VERSION ""

NS_ :

BS_:

BU_: FBD_HL IPB_App1 FBD_HM FBD_HR FBD_Miko FBD_MM FBD_Trunk FBD_VL FBD_VM FBD_VR Diagnosetool_CAN_FD_IPB_41

BO_ 686 AnalyticsDataFBD_HL: 48 FBD_HL
 SG_ AnalyticsDataFBD_HL_Ranging_Upti : 0|16@1+ (1.0,0) [0|65532] "s" IPB_App1
 SG_ AnalyticsDataFBD_HL_Ranging_Coun : 16|16@1+ (1.0,0) [0|65532] "" IPB_App1
 SG_ AnalyticsDataFBD_HL_RI_Low_New : 32|16@1+ (1.0,0) [0|65532] "" IPB_App1
 SG_ AnalyticsDataFBD_HL_RI_Low_Cont : 48|16@1+ (1.0,0) [0|65532] "" IPB_App1
 SG_ AnalyticsDataFBD_HL_RI_Med_New : 64|16@1+ (1.0,0) [0|65532] "" IPB_App1
 SG_ AnalyticsDataFBD_HL_RI_Med_Cont : 80|16@1+ (1.0,0) [0|65532] "" IPB_App1
 SG_ AnalyticsDataFBD_HL_RI_High_New : 96|16@1+ (1.0,0) [0|65532] "" IPB_App1
 SG_ AnalyticsDataFBD_HL_RI_High_Cont : 112|16@1+ (1.0,0) [0|65532] "" IPB_App1
 SG_ AnalyticsDataFBD_HL_Ranging_Sess : 128|16@1+ (1.0,0) [0|65532] "" IPB_App1
 SG_ AnalyticsDataFBD_HL_Ranging_Se_2 : 144|16@1+ (1.0,0) [0|65532] "" IPB_App1
 SG_ AnalyticsDataFBD_HL_Ranging_Se_3 : 160|16@1+ (1.0,0) [0|65532] "" IPB_App1
 SG_ AnalyticsDataFBD_HL_Ranging_Se_4 : 176|16@1+ (1.0,0) [0|65532] "" IPB_App1
 SG_ AnalyticsDataFBD_HL_Ranging_Se_5 : 192|16@1+ (1.0,0) [0|65532] "" IPB_App1
 SG_ AnalyticsDataFBD_HL_Ranging_Se_6 : 208|16@1+ (1.0,0) [0|65532] "" IPB_App1
 SG_ AnalyticsDataFBD_HL_Receive_Wind : 224|16@1+ (0.1,0) [0|6553.2] "s" IPB_App1
 SG_ AnalyticsDataFBD_HL_Receive_Wi_2 : 240|16@1+ (0.1,0) [0|6553.2] "s" IPB_App1
 SG_ AnalyticsDataFBD_HL_Receive_Wi_3 : 256|16@1+ (0.1,0) [0|6553.2] "s" IPB_App1
 SG_ AnalyticsDataFBD_HL_FDD_Success_ : 272|16@1+ (1.0,0) [0|65532] "" IPB_App1
 SG_ AnalyticsDataFBD_HL_FDD_Succes_2 : 288|16@1+ (1.0,0) [0|65532] "" IPB_App1
 SG_ AnalyticsDataFBD_HL_RSSI_New : 304|16@1+ (1.0,0) [0|65532] "" IPB_App1
 SG_ AnalyticsDataFBD_HL_RSSI_Cont : 320|16@1+ (1.0,0) [0|65532] "" IPB_App1
 SG_ AnalyticsDataFBD_HL_BLE_Localiza : 336|16@1+ (1.0,0) [0|65532] "" IPB_App1
 SG_ AnalyticsDataFBD_HL_BLE_Locali_2 : 352|16@1+ (1.0,0) [0|65532] "" IPB_App1
 SG_ AnalyticsDataFBD_HL_Fallback_Mod : 368|16@1+ (1.0,0) [0|65532] "" IPB_App1

BO_ 681 AnalyticsDataFBD_HM: 48 FBD_HM
 SG_ AnalyticsDataFBD_HM_Ranging_Upti : 0|16@1+ (1.0,0) [0|65532] "s" IPB_App1
 SG_ AnalyticsDataFBD_HM_Ranging_Coun : 16|16@1+ (1.0,0) [0|65532] "" IPB_App1
 SG_ AnalyticsDataFBD_HM_RI_Low_New : 32|16@1+ (1.0,0) [0|65532] "" IPB_App1
 SG_ AnalyticsDataFBD_HM_RI_Low_Cont : 48|16@1+ (1.0,0) [0|65532] "" IPB_App1
 SG_ AnalyticsDataFBD_HM_RI_Med_New : 64|16@1+ (1.0,0) [0|65532] "" IPB_App1
 SG_ AnalyticsDataFBD_HM_RI_Med_Cont : 80|16@1+ (1.0,0) [0|65532] "" IPB_App1
 SG_ AnalyticsDataFBD_HM_RI_High_New : 96|16@1+ (1.0,0) [0|65532] "" IPB_App1
 SG_ AnalyticsDataFBD_HM_RI_High_Cont : 112|16@1+ (1.0,0) [0|65532] "" IPB_App1
 SG_ AnalyticsDataFBD_HM_Ranging_Sess : 128|16@1+ (1.0,0) [0|65532] "" IPB_App1
 SG_ AnalyticsDataFBD_HM_Ranging_Se_2 : 144|16@1+ (1.0,0) [0|65532] "" IPB_App1
 SG_ AnalyticsDataFBD_HM_Ranging_Se_3 : 160|16@1+ (1.0,0) [0|65532] "" IPB_App1
 SG_ AnalyticsDataFBD_HM_Ranging_Se_4 : 176|16@1+ (1.0,0) [0|65532] "" IPB_App1
 SG_ AnalyticsDataFBD_HM_Ranging_Se_5 : 192|16@1+ (1.0,0) [0|65532] "" IPB_App1
 SG_ AnalyticsDataFBD_HM_Ranging_Se_6 : 208|16@1+ (1.0,0) [0|65532] "" IPB_App1
 SG_ AnalyticsDataFBD_HM_Receive_Wind : 224|16@1+ (0.1,0) [0|6553.2] "s" IPB_App1
 SG_ AnalyticsDataFBD_HM_Receive_Wi_2 : 240|16@1+ (0.1,0) [0|6553.2] "s" IPB_App1
 SG_ AnalyticsDataFBD_HM_Receive_Wi_3 : 256|16@1+ (0.1,0) [0|6553.2] "s" IPB_App1
 SG_ AnalyticsDataFBD_HM_FDD_Success_ : 272|16@1+ (1.0,0) [0|65532] "" IPB_App1
 SG_ AnalyticsDataFBD_HM_FDD_Succes_2 : 288|16@1+ (1.0,0) [0|65532] "" IPB_App1
 SG_ AnalyticsDataFBD_HM_RSSI_New : 304|16@1+ (1.0,0) [0|65532] "" IPB_App1
 SG_ AnalyticsDataFBD_HM_RSSI_Cont : 320|16@1+ (1.0,0) [0|65532] "" IPB_App1
 SG_ AnalyticsDataFBD_HM_BLE_Localiza : 336|16@1+ (1.0,0) [0|65532] "" IPB_App1
 SG_ AnalyticsDataFBD_HM_BLE_Locali_2 : 352|16@1+ (1.0,0) [0|65532] "" IPB_App1
 SG_ AnalyticsDataFBD_HM_Fallback_Mod : 368|16@1+ (1.0,0) [0|65532] "" IPB_App1

BO_ 687 AnalyticsDataFBD_HR: 48 FBD_HR
 SG_ AnalyticsDataFBD_HR_Ranging_Upti : 0|16@1+ (1.0,0) [0|65532] "s" IPB_App1
 SG_ AnalyticsDataFBD_HR_Ranging_Coun : 16|16@1+ (1.0,0) [0|65532] "" IPB_App1
 SG_ AnalyticsDataFBD_HR_RI_Low_New : 32|16@1+ (1.0,0) [0|65532] "" IPB_App1
 SG_ AnalyticsDataFBD_HR_RI_Low_Cont : 48|16@1+ (1.0,0) [0|65532] "" IPB_App1
 SG_ AnalyticsDataFBD_HR_RI_Med_New : 64|16@1+ (1.0,0) [0|65532] "" IPB_App1
 SG_ AnalyticsDataFBD_HR_RI_Med_Cont : 80|16@1+ (1.0,0) [0|65532] "" IPB_App1
 SG_ AnalyticsDataFBD_HR_RI_High_New : 96|16@1+ (1.0,0) [0|65532] "" IPB_App1
 SG_ AnalyticsDataFBD_HR_RI_High_Cont : 112|16@1+ (1.0,0) [0|65532] "" IPB_App1
 SG_ AnalyticsDataFBD_HR_Ranging_Sess : 128|16@1+ (1.0,0) [0|65532] "" IPB_App1
 SG_ AnalyticsDataFBD_HR_Ranging_Se_2 : 144|16@1+ (1.0,0) [0|65532] "" IPB_App1
 SG_ AnalyticsDataFBD_HR_Ranging_Se_3 : 160|16@1+ (1.0,0) [0|65532] "" IPB_App1
 SG_ AnalyticsDataFBD_HR_Ranging_Se_4 : 176|16@1+ (1.0,0) [0|65532] "" IPB_App1
 SG_ AnalyticsDataFBD_HR_Ranging_Se_5 : 192|16@1+ (1.0,0) [0|65532] "" IPB_App1
 SG_ AnalyticsDataFBD_HR_Ranging_Se_6 : 208|16@1+ (1.0,0) [0|65532] "" IPB_App1
 SG_ AnalyticsDataFBD_HR_Receive_Wind : 224|16@1+ (0.1,0) [0|6553.2] "s" IPB_App1
 SG_ AnalyticsDataFBD_HR_Receive_Wi_2 : 240|16@1+ (0.1,0) [0|6553.2] "s" IPB_App1
 SG_ AnalyticsDataFBD_HR_Receive_Wi_3 : 256|16@1+ (0.1,0) [0|6553.2] "s" IPB_App1
 SG_ AnalyticsDataFBD_HR_FDD_Success_ : 272|16@1+ (1.0,0) [0|65532] "" IPB_App1
 SG_ AnalyticsDataFBD_HR_FDD_Succes_2 : 288|16@1+ (1.0,0) [0|65532] "" IPB_App1
 SG_ AnalyticsDataFBD_HR_RSSI_New : 304|16@1+ (1.0,0) [0|65532] "" IPB_App1
 SG_ AnalyticsDataFBD_HR_RSSI_Cont : 320|16@1+ (1.0,0) [0|65532] "" IPB_App1
 SG_ AnalyticsDataFBD_HR_BLE_Localiza : 336|16@1+ (1.0,0) [0|65532] "" IPB_App1
 SG_ AnalyticsDataFBD_HR_BLE_Locali_2 : 352|16@1+ (1.0,0) [0|65532] "" IPB_App1
 SG_ AnalyticsDataFBD_HR_Fallback_Mod : 368|16@1+ (1.0,0) [0|65532] "" IPB_App1

BO_ 682 AnalyticsDataFBD_Miko: 48 FBD_Miko
 SG_ AnalyticsDataFBD_Miko_Ranging_Up : 0|16@1+ (1.0,0) [0|65532] "s" IPB_App1
 SG_ AnalyticsDataFBD_Miko_Ranging_Co : 16|16@1+ (1.0,0) [0|65532] "" IPB_App1
 SG_ AnalyticsDataFBD_Miko_RI_Low_New : 32|16@1+ (1.0,0) [0|65532] "" IPB_App1
 SG_ AnalyticsDataFBD_Miko_RI_Low_Con : 48|16@1+ (1.0,0) [0|65532] "" IPB_App1
 SG_ AnalyticsDataFBD_Miko_RI_Med_New : 64|16@1+ (1.0,0) [0|65532] "" IPB_App1
 SG_ AnalyticsDataFBD_Miko_RI_Med_Con : 80|16@1+ (1.0,0) [0|65532] "" IPB_App1
 SG_ AnalyticsDataFBD_Miko_RI_High_Ne : 96|16@1+ (1.0,0) [0|65532] "" IPB_App1
 SG_ AnalyticsDataFBD_Miko_RI_High_Co : 112|16@1+ (1.0,0) [0|65532] "" IPB_App1
 SG_ AnalyticsDataFBD_Miko_Ranging_Se : 128|16@1+ (1.0,0) [0|65532] "" IPB_App1
 SG_ AnalyticsDataFBD_Miko_Ranging__2 : 144|16@1+ (1.0,0) [0|65532] "" IPB_App1
 SG_ AnalyticsDataFBD_Miko_Ranging__3 : 160|16@1+ (1.0,0) [0|65532] "" IPB_App1
 SG_ AnalyticsDataFBD_Miko_Ranging__4 : 176|16@1+ (1.0,0) [0|65532] "" IPB_App1
 SG_ AnalyticsDataFBD_Miko_Ranging__5 : 192|16@1+ (1.0,0) [0|65532] "" IPB_App1
 SG_ AnalyticsDataFBD_Miko_Ranging__6 : 208|16@1+ (1.0,0) [0|65532] "" IPB_App1
 SG_ AnalyticsDataFBD_Miko_Receive_Wi : 224|16@1+ (0.1,0) [0|6553.2] "s" IPB_App1
 SG_ AnalyticsDataFBD_Miko_Receive__2 : 240|16@1+ (0.1,0) [0|6553.2] "s" IPB_App1
 SG_ AnalyticsDataFBD_Miko_Receive__3 : 256|16@1+ (0.1,0) [0|6553.2] "s" IPB_App1
 SG_ AnalyticsDataFBD_Miko_FDD_Succes : 272|16@1+ (1.0,0) [0|65532] "" IPB_App1
 SG_ AnalyticsDataFBD_Miko_FDD_Succ_2 : 288|16@1+ (1.0,0) [0|65532] "" IPB_App1
 SG_ AnalyticsDataFBD_Miko_RSSI_New : 304|16@1+ (1.0,0) [0|65532] "" IPB_App1
 SG_ AnalyticsDataFBD_Miko_RSSI_Cont : 320|16@1+ (1.0,0) [0|65532] "" IPB_App1
 SG_ AnalyticsDataFBD_Miko_BLE_Locali : 336|16@1+ (1.0,0) [0|65532] "" IPB_App1
 SG_ AnalyticsDataFBD_Miko_BLE_Loca_2 : 352|16@1+ (1.0,0) [0|65532] "" IPB_App1
 SG_ AnalyticsDataFBD_Miko_Fallback_M : 368|16@1+ (1.0,0) [0|65532] "" IPB_App1

BO_ 690 AnalyticsDataFBD_MM: 48 FBD_MM
 SG_ AnalyticsDataFBD_MM_Ranging_Upti : 0|16@1+ (1.0,0) [0|65532] "s" IPB_App1
 SG_ AnalyticsDataFBD_MM_Ranging_Coun : 16|16@1+ (1.0,0) [0|65532] "" IPB_App1
 SG_ AnalyticsDataFBD_MM_RI_Low_New : 32|16@1+ (1.0,0) [0|65532] "" IPB_App1
 SG_ AnalyticsDataFBD_MM_RI_Low_Cont : 48|16@1+ (1.0,0) [0|65532] "" IPB_App1
 SG_ AnalyticsDataFBD_MM_RI_Med_New : 64|16@1+ (1.0,0) [0|65532] "" IPB_App1
 SG_ AnalyticsDataFBD_MM_RI_Med_Cont : 80|16@1+ (1.0,0) [0|65532] "" IPB_App1
 SG_ AnalyticsDataFBD_MM_RI_High_New : 96|16@1+ (1.0,0) [0|65532] "" IPB_App1
 SG_ AnalyticsDataFBD_MM_RI_High_Cont : 112|16@1+ (1.0,0) [0|65532] "" IPB_App1
 SG_ AnalyticsDataFBD_MM_Ranging_Sess : 128|16@1+ (1.0,0) [0|65532] "" IPB_App1
 SG_ AnalyticsDataFBD_MM_Ranging_Se_2 : 144|16@1+ (1.0,0) [0|65532] "" IPB_App1
 SG_ AnalyticsDataFBD_MM_Ranging_Se_3 : 160|16@1+ (1.0,0) [0|65532] "" IPB_App1
 SG_ AnalyticsDataFBD_MM_Ranging_Se_4 : 176|16@1+ (1.0,0) [0|65532] "" IPB_App1
 SG_ AnalyticsDataFBD_MM_Ranging_Se_5 : 192|16@1+ (1.0,0) [0|65532] "" IPB_App1
 SG_ AnalyticsDataFBD_MM_Ranging_Se_6 : 208|16@1+ (1.0,0) [0|65532] "" IPB_App1
 SG_ AnalyticsDataFBD_MM_Receive_Wind : 224|16@1+ (0.1,0) [0|6553.2] "s" IPB_App1
 SG_ AnalyticsDataFBD_MM_Receive_Wi_2 : 240|16@1+ (0.1,0) [0|6553.2] "s" IPB_App1
 SG_ AnalyticsDataFBD_MM_Receive_Wi_3 : 256|16@1+ (0.1,0) [0|6553.2] "s" IPB_App1
 SG_ AnalyticsDataFBD_MM_FDD_Success_ : 272|16@1+ (1.0,0) [0|65532] "" IPB_App1
 SG_ AnalyticsDataFBD_MM_FDD_Succes_2 : 288|16@1+ (1.0,0) [0|65532] "" IPB_App1
 SG_ AnalyticsDataFBD_MM_RSSI_New : 304|16@1+ (1.0,0) [0|65532] "" IPB_App1
 SG_ AnalyticsDataFBD_MM_RSSI_Cont : 320|16@1+ (1.0,0) [0|65532] "" IPB_App1
 SG_ AnalyticsDataFBD_MM_BLE_Localiza : 336|16@1+ (1.0,0) [0|65532] "" IPB_App1
 SG_ AnalyticsDataFBD_MM_BLE_Locali_2 : 352|16@1+ (1.0,0) [0|65532] "" IPB_App1
 SG_ AnalyticsDataFBD_MM_Fallback_Mod : 368|16@1+ (1.0,0) [0|65532] "" IPB_App1

BO_ 683 AnalyticsDataFBD_Trunk: 48 FBD_Trunk
 SG_ AnalyticsDataFBD_Trunk_Ranging_U : 0|16@1+ (1.0,0) [0|65532] "s" IPB_App1
 SG_ AnalyticsDataFBD_Trunk_Ranging_C : 16|16@1+ (1.0,0) [0|65532] "" IPB_App1
 SG_ AnalyticsDataFBD_Trunk_RI_Low_Ne : 32|16@1+ (1.0,0) [0|65532] "" IPB_App1
 SG_ AnalyticsDataFBD_Trunk_RI_Low_Co : 48|16@1+ (1.0,0) [0|65532] "" IPB_App1
 SG_ AnalyticsDataFBD_Trunk_RI_Med_Ne : 64|16@1+ (1.0,0) [0|65532] "" IPB_App1
 SG_ AnalyticsDataFBD_Trunk_RI_Med_Co : 80|16@1+ (1.0,0) [0|65532] "" IPB_App1
 SG_ AnalyticsDataFBD_Trunk_RI_High_N : 96|16@1+ (1.0,0) [0|65532] "" IPB_App1
 SG_ AnalyticsDataFBD_Trunk_RI_High_C : 112|16@1+ (1.0,0) [0|65532] "" IPB_App1
 SG_ AnalyticsDataFBD_Trunk_Ranging_S : 128|16@1+ (1.0,0) [0|65532] "" IPB_App1
 SG_ AnalyticsDataFBD_Trunk_Ranging_2 : 144|16@1+ (1.0,0) [0|65532] "" IPB_App1
 SG_ AnalyticsDataFBD_Trunk_Ranging_3 : 160|16@1+ (1.0,0) [0|65532] "" IPB_App1
 SG_ AnalyticsDataFBD_Trunk_Ranging_4 : 176|16@1+ (1.0,0) [0|65532] "" IPB_App1
 SG_ AnalyticsDataFBD_Trunk_Ranging_5 : 192|16@1+ (1.0,0) [0|65532] "" IPB_App1
 SG_ AnalyticsDataFBD_Trunk_Ranging_6 : 208|16@1+ (1.0,0) [0|65532] "" IPB_App1
 SG_ AnalyticsDataFBD_Trunk_Receive_W : 224|16@1+ (0.1,0) [0|6553.2] "s" IPB_App1
 SG_ AnalyticsDataFBD_Trunk_Receive_2 : 240|16@1+ (0.1,0) [0|6553.2] "s" IPB_App1
 SG_ AnalyticsDataFBD_Trunk_Receive_3 : 256|16@1+ (0.1,0) [0|6553.2] "s" IPB_App1
 SG_ AnalyticsDataFBD_Trunk_FDD_Succe : 272|16@1+ (1.0,0) [0|65532] "" IPB_App1
 SG_ AnalyticsDataFBD_Trunk_FDD_Suc_2 : 288|16@1+ (1.0,0) [0|65532] "" IPB_App1
 SG_ AnalyticsDataFBD_Trunk_RSSI_New : 304|16@1+ (1.0,0) [0|65532] "" IPB_App1
 SG_ AnalyticsDataFBD_Trunk_RSSI_Cont : 320|16@1+ (1.0,0) [0|65532] "" IPB_App1
 SG_ AnalyticsDataFBD_Trunk_BLE_Local : 336|16@1+ (1.0,0) [0|65532] "" IPB_App1
 SG_ AnalyticsDataFBD_Trunk_BLE_Loc_2 : 352|16@1+ (1.0,0) [0|65532] "" IPB_App1
 SG_ AnalyticsDataFBD_Trunk_Fallback_ : 368|16@1+ (1.0,0) [0|65532] "" IPB_App1

BO_ 684 AnalyticsDataFBD_VL: 48 FBD_VL
 SG_ AnalyticsDataFBD_VL_Ranging_Upti : 0|16@1+ (1.0,0) [0|65532] "s" IPB_App1
 SG_ AnalyticsDataFBD_VL_Ranging_Coun : 16|16@1+ (1.0,0) [0|65532] "" IPB_App1
 SG_ AnalyticsDataFBD_VL_RI_Low_New : 32|16@1+ (1.0,0) [0|65532] "" IPB_App1
 SG_ AnalyticsDataFBD_VL_RI_Low_Cont : 48|16@1+ (1.0,0) [0|65532] "" IPB_App1
 SG_ AnalyticsDataFBD_VL_RI_Med_New : 64|16@1+ (1.0,0) [0|65532] "" IPB_App1
 SG_ AnalyticsDataFBD_VL_RI_Med_Cont : 80|16@1+ (1.0,0) [0|65532] "" IPB_App1
 SG_ AnalyticsDataFBD_VL_RI_High_New : 96|16@1+ (1.0,0) [0|65532] "" IPB_App1
 SG_ AnalyticsDataFBD_VL_RI_High_Cont : 112|16@1+ (1.0,0) [0|65532] "" IPB_App1
 SG_ AnalyticsDataFBD_VL_Ranging_Sess : 128|16@1+ (1.0,0) [0|65532] "" IPB_App1
 SG_ AnalyticsDataFBD_VL_Ranging_Se_2 : 144|16@1+ (1.0,0) [0|65532] "" IPB_App1
 SG_ AnalyticsDataFBD_VL_Ranging_Se_3 : 160|16@1+ (1.0,0) [0|65532] "" IPB_App1
 SG_ AnalyticsDataFBD_VL_Ranging_Se_4 : 176|16@1+ (1.0,0) [0|65532] "" IPB_App1
 SG_ AnalyticsDataFBD_VL_Ranging_Se_5 : 192|16@1+ (1.0,0) [0|65532] "" IPB_App1
 SG_ AnalyticsDataFBD_VL_Ranging_Se_6 : 208|16@1+ (1.0,0) [0|65532] "" IPB_App1
 SG_ AnalyticsDataFBD_VL_Receive_Wind : 224|16@1+ (0.1,0) [0|6553.2] "s" IPB_App1
 SG_ AnalyticsDataFBD_VL_Receive_Wi_2 : 240|16@1+ (0.1,0) [0|6553.2] "s" IPB_App1
 SG_ AnalyticsDataFBD_VL_Receive_Wi_3 : 256|16@1+ (0.1,0) [0|6553.2] "s" IPB_App1
 SG_ AnalyticsDataFBD_VL_FDD_Success_ : 272|16@1+ (1.0,0) [0|65532] "" IPB_App1
 SG_ AnalyticsDataFBD_VL_FDD_Succes_2 : 288|16@1+ (1.0,0) [0|65532] "" IPB_App1
 SG_ AnalyticsDataFBD_VL_RSSI_New : 304|16@1+ (1.0,0) [0|65532] "" IPB_App1
 SG_ AnalyticsDataFBD_VL_RSSI_Cont : 320|16@1+ (1.0,0) [0|65532] "" IPB_App1
 SG_ AnalyticsDataFBD_VL_BLE_Localiza : 336|16@1+ (1.0,0) [0|65532] "" IPB_App1
 SG_ AnalyticsDataFBD_VL_BLE_Locali_2 : 352|16@1+ (1.0,0) [0|65532] "" IPB_App1
 SG_ AnalyticsDataFBD_VL_Fallback_Mod : 368|16@1+ (1.0,0) [0|65532] "" IPB_App1

BO_ 680 AnalyticsDataFBD_VM: 48 FBD_VM
 SG_ AnalyticsDataFBD_VM_Ranging_Upti : 0|16@1+ (1.0,0) [0|65532] "s" IPB_App1
 SG_ AnalyticsDataFBD_VM_Ranging_Coun : 16|16@1+ (1.0,0) [0|65532] "" IPB_App1
 SG_ AnalyticsDataFBD_VM_RI_Low_New : 32|16@1+ (1.0,0) [0|65532] "" IPB_App1
 SG_ AnalyticsDataFBD_VM_RI_Low_Cont : 48|16@1+ (1.0,0) [0|65532] "" IPB_App1
 SG_ AnalyticsDataFBD_VM_RI_Med_New : 64|16@1+ (1.0,0) [0|65532] "" IPB_App1
 SG_ AnalyticsDataFBD_VM_RI_Med_Cont : 80|16@1+ (1.0,0) [0|65532] "" IPB_App1
 SG_ AnalyticsDataFBD_VM_RI_High_New : 96|16@1+ (1.0,0) [0|65532] "" IPB_App1
 SG_ AnalyticsDataFBD_VM_RI_High_Cont : 112|16@1+ (1.0,0) [0|65532] "" IPB_App1
 SG_ AnalyticsDataFBD_VM_Ranging_Sess : 128|16@1+ (1.0,0) [0|65532] "" IPB_App1
 SG_ AnalyticsDataFBD_VM_Ranging_Se_2 : 144|16@1+ (1.0,0) [0|65532] "" IPB_App1
 SG_ AnalyticsDataFBD_VM_Ranging_Se_3 : 160|16@1+ (1.0,0) [0|65532] "" IPB_App1
 SG_ AnalyticsDataFBD_VM_Ranging_Se_4 : 176|16@1+ (1.0,0) [0|65532] "" IPB_App1
 SG_ AnalyticsDataFBD_VM_Ranging_Se_5 : 192|16@1+ (1.0,0) [0|65532] "" IPB_App1
 SG_ AnalyticsDataFBD_VM_Ranging_Se_6 : 208|16@1+ (1.0,0) [0|65532] "" IPB_App1
 SG_ AnalyticsDataFBD_VM_Receive_Wind : 224|16@1+ (0.1,0) [0|6553.2] "s" IPB_App1
 SG_ AnalyticsDataFBD_VM_Receive_Wi_2 : 240|16@1+ (0.1,0) [0|6553.2] "s" IPB_App1
 SG_ AnalyticsDataFBD_VM_Receive_Wi_3 : 256|16@1+ (0.1,0) [0|6553.2] "s" IPB_App1
 SG_ AnalyticsDataFBD_VM_FDD_Success_ : 272|16@1+ (1.0,0) [0|65532] "" IPB_App1
 SG_ AnalyticsDataFBD_VM_FDD_Succes_2 : 288|16@1+ (1.0,0) [0|65532] "" IPB_App1
 SG_ AnalyticsDataFBD_VM_RSSI_New : 304|16@1+ (1.0,0) [0|65532] "" IPB_App1
 SG_ AnalyticsDataFBD_VM_RSSI_Cont : 320|16@1+ (1.0,0) [0|65532] "" IPB_App1
 SG_ AnalyticsDataFBD_VM_BLE_Localiza : 336|16@1+ (1.0,0) [0|65532] "" IPB_App1
 SG_ AnalyticsDataFBD_VM_BLE_Locali_2 : 352|16@1+ (1.0,0) [0|65532] "" IPB_App1
 SG_ AnalyticsDataFBD_VM_Fallback_Mod : 368|16@1+ (1.0,0) [0|65532] "" IPB_App1

BO_ 685 AnalyticsDataFBD_VR: 48 FBD_VR
 SG_ AnalyticsDataFBD_VR_Ranging_Upti : 0|16@1+ (1.0,0) [0|65532] "s" IPB_App1
 SG_ AnalyticsDataFBD_VR_Ranging_Coun : 16|16@1+ (1.0,0) [0|65532] "" IPB_App1
 SG_ AnalyticsDataFBD_VR_RI_Low_New : 32|16@1+ (1.0,0) [0|65532] "" IPB_App1
 SG_ AnalyticsDataFBD_VR_RI_Low_Cont : 48|16@1+ (1.0,0) [0|65532] "" IPB_App1
 SG_ AnalyticsDataFBD_VR_RI_Med_New : 64|16@1+ (1.0,0) [0|65532] "" IPB_App1
 SG_ AnalyticsDataFBD_VR_RI_Med_Cont : 80|16@1+ (1.0,0) [0|65532] "" IPB_App1
 SG_ AnalyticsDataFBD_VR_RI_High_New : 96|16@1+ (1.0,0) [0|65532] "" IPB_App1
 SG_ AnalyticsDataFBD_VR_RI_High_Cont : 112|16@1+ (1.0,0) [0|65532] "" IPB_App1
 SG_ AnalyticsDataFBD_VR_Ranging_Sess : 128|16@1+ (1.0,0) [0|65532] "" IPB_App1
 SG_ AnalyticsDataFBD_VR_Ranging_Se_2 : 144|16@1+ (1.0,0) [0|65532] "" IPB_App1
 SG_ AnalyticsDataFBD_VR_Ranging_Se_3 : 160|16@1+ (1.0,0) [0|65532] "" IPB_App1
 SG_ AnalyticsDataFBD_VR_Ranging_Se_4 : 176|16@1+ (1.0,0) [0|65532] "" IPB_App1
 SG_ AnalyticsDataFBD_VR_Ranging_Se_5 : 192|16@1+ (1.0,0) [0|65532] "" IPB_App1
 SG_ AnalyticsDataFBD_VR_Ranging_Se_6 : 208|16@1+ (1.0,0) [0|65532] "" IPB_App1
 SG_ AnalyticsDataFBD_VR_Receive_Wind : 224|16@1+ (0.1,0) [0|6553.2] "s" IPB_App1
 SG_ AnalyticsDataFBD_VR_Receive_Wi_2 : 240|16@1+ (0.1,0) [0|6553.2] "s" IPB_App1
 SG_ AnalyticsDataFBD_VR_Receive_Wi_3 : 256|16@1+ (0.1,0) [0|6553.2] "s" IPB_App1
 SG_ AnalyticsDataFBD_VR_FDD_Success_ : 272|16@1+ (1.0,0) [0|65532] "" IPB_App1
 SG_ AnalyticsDataFBD_VR_FDD_Succes_2 : 288|16@1+ (1.0,0) [0|65532] "" IPB_App1
 SG_ AnalyticsDataFBD_VR_RSSI_New : 304|16@1+ (1.0,0) [0|65532] "" IPB_App1
 SG_ AnalyticsDataFBD_VR_RSSI_Cont : 320|16@1+ (1.0,0) [0|65532] "" IPB_App1
 SG_ AnalyticsDataFBD_VR_BLE_Localiza : 336|16@1+ (1.0,0) [0|65532] "" IPB_App1
 SG_ AnalyticsDataFBD_VR_BLE_Locali_2 : 352|16@1+ (1.0,0) [0|65532] "" IPB_App1
 SG_ AnalyticsDataFBD_VR_Fallback_Mod : 368|16@1+ (1.0,0) [0|65532] "" IPB_App1

BO_ 607 AnalyticsDataRequest: 8 IPB_App1
 SG_ AnalyticsDataRequest_Address : 0|16@1+ (1,0) [0|0] "" FBD_HL,FBD_HM,FBD_HR,FBD_MM,FBD_Miko,FBD_Trunk,FBD_VL,FBD_VM,FBD_VR
 SG_ AnalyticsDataRequest_RequestData : 16|8@1+ (1.0,0) [0|252] "" FBD_HL,FBD_HM,FBD_HR,FBD_MM,FBD_Miko,FBD_Trunk,FBD_VL,FBD_VM,FBD_VR

BO_ 605 ControlBindingFBD: 64 IPB_App1
 SG_ ControlBindingFBD_Address : 0|16@1+ (1,0) [0|0] "" FBD_HL,FBD_HM,FBD_HR,FBD_MM,FBD_Miko,FBD_Trunk,FBD_VL,FBD_VM,FBD_VR
 SG_ ControlBindingFBD_BindingSequenc : 16|8@1+ (1.0,0) [0|252] "" FBD_HL,FBD_HM,FBD_HR,FBD_MM,FBD_Miko,FBD_Trunk,FBD_VL,FBD_VM,FBD_VR
 SG_ ControlBindingFBD_Data00 : 24|8@1+ (1.0,0) [0|255] "" FBD_HL,FBD_HM,FBD_HR,FBD_MM,FBD_Miko,FBD_Trunk,FBD_VL,FBD_VM,FBD_VR
 SG_ ControlBindingFBD_Data01 : 32|8@1+ (1.0,0) [0|255] "" FBD_HL,FBD_HM,FBD_HR,FBD_MM,FBD_Miko,FBD_Trunk,FBD_VL,FBD_VM,FBD_VR
 SG_ ControlBindingFBD_Data02 : 40|8@1+ (1.0,0) [0|255] "" FBD_HL,FBD_HM,FBD_HR,FBD_MM,FBD_Miko,FBD_Trunk,FBD_VL,FBD_VM,FBD_VR
 SG_ ControlBindingFBD_Data03 : 48|8@1+ (1.0,0) [0|255] "" FBD_HL,FBD_HM,FBD_HR,FBD_MM,FBD_Miko,FBD_Trunk,FBD_VL,FBD_VM,FBD_VR
 SG_ ControlBindingFBD_Data04 : 56|8@1+ (1.0,0) [0|255] "" FBD_HL,FBD_HM,FBD_HR,FBD_MM,FBD_Miko,FBD_Trunk,FBD_VL,FBD_VM,FBD_VR
 SG_ ControlBindingFBD_Data05 : 64|8@1+ (1.0,0) [0|255] "" FBD_HL,FBD_HM,FBD_HR,FBD_MM,FBD_Miko,FBD_Trunk,FBD_VL,FBD_VM,FBD_VR
 SG_ ControlBindingFBD_Data06 : 72|8@1+ (1.0,0) [0|255] "" FBD_HL,FBD_HM,FBD_HR,FBD_MM,FBD_Miko,FBD_Trunk,FBD_VL,FBD_VM,FBD_VR
 SG_ ControlBindingFBD_Data07 : 80|8@1+ (1.0,0) [0|255] "" FBD_HL,FBD_HM,FBD_HR,FBD_MM,FBD_Miko,FBD_Trunk,FBD_VL,FBD_VM,FBD_VR
 SG_ ControlBindingFBD_Data08 : 88|8@1+ (1.0,0) [0|255] "" FBD_HL,FBD_HM,FBD_HR,FBD_MM,FBD_Miko,FBD_Trunk,FBD_VL,FBD_VM,FBD_VR
 SG_ ControlBindingFBD_Data09 : 96|8@1+ (1.0,0) [0|255] "" FBD_HL,FBD_HM,FBD_HR,FBD_MM,FBD_Miko,FBD_Trunk,FBD_VL,FBD_VM,FBD_VR
 SG_ ControlBindingFBD_Data10 : 104|8@1+ (1.0,0) [0|255] "" FBD_HL,FBD_HM,FBD_HR,FBD_MM,FBD_Miko,FBD_Trunk,FBD_VL,FBD_VM,FBD_VR
 SG_ ControlBindingFBD_Data11 : 112|8@1+ (1.0,0) [0|255] "" FBD_HL,FBD_HM,FBD_HR,FBD_MM,FBD_Miko,FBD_Trunk,FBD_VL,FBD_VM,FBD_VR
 SG_ ControlBindingFBD_Data12 : 120|8@1+ (1.0,0) [0|255] "" FBD_HL,FBD_HM,FBD_HR,FBD_MM,FBD_Miko,FBD_Trunk,FBD_VL,FBD_VM,FBD_VR
 SG_ ControlBindingFBD_Data13 : 128|8@1+ (1.0,0) [0|255] "" FBD_HL,FBD_HM,FBD_HR,FBD_MM,FBD_Miko,FBD_Trunk,FBD_VL,FBD_VM,FBD_VR
 SG_ ControlBindingFBD_Data14 : 136|8@1+ (1.0,0) [0|255] "" FBD_HL,FBD_HM,FBD_HR,FBD_MM,FBD_Miko,FBD_Trunk,FBD_VL,FBD_VM,FBD_VR
 SG_ ControlBindingFBD_Data15 : 144|8@1+ (1.0,0) [0|255] "" FBD_HL,FBD_HM,FBD_HR,FBD_MM,FBD_Miko,FBD_Trunk,FBD_VL,FBD_VM,FBD_VR
 SG_ ControlBindingFBD_Data16 : 152|8@1+ (1.0,0) [0|255] "" FBD_HL,FBD_HM,FBD_HR,FBD_MM,FBD_Miko,FBD_Trunk,FBD_VL,FBD_VM,FBD_VR
 SG_ ControlBindingFBD_Data17 : 160|8@1+ (1.0,0) [0|255] "" FBD_HL,FBD_HM,FBD_HR,FBD_MM,FBD_Miko,FBD_Trunk,FBD_VL,FBD_VM,FBD_VR
 SG_ ControlBindingFBD_Data18 : 168|8@1+ (1.0,0) [0|255] "" FBD_HL,FBD_HM,FBD_HR,FBD_MM,FBD_Miko,FBD_Trunk,FBD_VL,FBD_VM,FBD_VR
 SG_ ControlBindingFBD_Data19 : 176|8@1+ (1.0,0) [0|255] "" FBD_HL,FBD_HM,FBD_HR,FBD_MM,FBD_Miko,FBD_Trunk,FBD_VL,FBD_VM,FBD_VR
 SG_ ControlBindingFBD_Data20 : 184|8@1+ (1.0,0) [0|255] "" FBD_HL,FBD_HM,FBD_HR,FBD_MM,FBD_Miko,FBD_Trunk,FBD_VL,FBD_VM,FBD_VR
 SG_ ControlBindingFBD_Data21 : 192|8@1+ (1.0,0) [0|255] "" FBD_HL,FBD_HM,FBD_HR,FBD_MM,FBD_Miko,FBD_Trunk,FBD_VL,FBD_VM,FBD_VR
 SG_ ControlBindingFBD_Data22 : 200|8@1+ (1.0,0) [0|255] "" FBD_HL,FBD_HM,FBD_HR,FBD_MM,FBD_Miko,FBD_Trunk,FBD_VL,FBD_VM,FBD_VR
 SG_ ControlBindingFBD_Data23 : 208|8@1+ (1.0,0) [0|255] "" FBD_HL,FBD_HM,FBD_HR,FBD_MM,FBD_Miko,FBD_Trunk,FBD_VL,FBD_VM,FBD_VR
 SG_ ControlBindingFBD_Data24 : 216|8@1+ (1.0,0) [0|255] "" FBD_HL,FBD_HM,FBD_HR,FBD_MM,FBD_Miko,FBD_Trunk,FBD_VL,FBD_VM,FBD_VR
 SG_ ControlBindingFBD_Data25 : 224|8@1+ (1.0,0) [0|255] "" FBD_HL,FBD_HM,FBD_HR,FBD_MM,FBD_Miko,FBD_Trunk,FBD_VL,FBD_VM,FBD_VR
 SG_ ControlBindingFBD_Data26 : 232|8@1+ (1.0,0) [0|255] "" FBD_HL,FBD_HM,FBD_HR,FBD_MM,FBD_Miko,FBD_Trunk,FBD_VL,FBD_VM,FBD_VR
 SG_ ControlBindingFBD_Data27 : 240|8@1+ (1.0,0) [0|255] "" FBD_HL,FBD_HM,FBD_HR,FBD_MM,FBD_Miko,FBD_Trunk,FBD_VL,FBD_VM,FBD_VR
 SG_ ControlBindingFBD_Data28 : 248|8@1+ (1.0,0) [0|255] "" FBD_HL,FBD_HM,FBD_HR,FBD_MM,FBD_Miko,FBD_Trunk,FBD_VL,FBD_VM,FBD_VR
 SG_ ControlBindingFBD_Data29 : 256|8@1+ (1.0,0) [0|255] "" FBD_HL,FBD_HM,FBD_HR,FBD_MM,FBD_Miko,FBD_Trunk,FBD_VL,FBD_VM,FBD_VR
 SG_ ControlBindingFBD_Data30 : 264|8@1+ (1.0,0) [0|255] "" FBD_HL,FBD_HM,FBD_HR,FBD_MM,FBD_Miko,FBD_Trunk,FBD_VL,FBD_VM,FBD_VR
 SG_ ControlBindingFBD_Data31 : 272|8@1+ (1.0,0) [0|255] "" FBD_HL,FBD_HM,FBD_HR,FBD_MM,FBD_Miko,FBD_Trunk,FBD_VL,FBD_VM,FBD_VR
 SG_ ControlBindingFBD_Data32 : 280|8@1+ (1.0,0) [0|255] "" FBD_HL,FBD_HM,FBD_HR,FBD_MM,FBD_Miko,FBD_Trunk,FBD_VL,FBD_VM,FBD_VR
 SG_ ControlBindingFBD_Data33 : 288|8@1+ (1.0,0) [0|255] "" FBD_HL,FBD_HM,FBD_HR,FBD_MM,FBD_Miko,FBD_Trunk,FBD_VL,FBD_VM,FBD_VR
 SG_ ControlBindingFBD_Data34 : 296|8@1+ (1.0,0) [0|255] "" FBD_HL,FBD_HM,FBD_HR,FBD_MM,FBD_Miko,FBD_Trunk,FBD_VL,FBD_VM,FBD_VR
 SG_ ControlBindingFBD_Data35 : 304|8@1+ (1.0,0) [0|255] "" FBD_HL,FBD_HM,FBD_HR,FBD_MM,FBD_Miko,FBD_Trunk,FBD_VL,FBD_VM,FBD_VR
 SG_ ControlBindingFBD_Data36 : 312|8@1+ (1.0,0) [0|255] "" FBD_HL,FBD_HM,FBD_HR,FBD_MM,FBD_Miko,FBD_Trunk,FBD_VL,FBD_VM,FBD_VR
 SG_ ControlBindingFBD_Data37 : 320|8@1+ (1.0,0) [0|255] "" FBD_HL,FBD_HM,FBD_HR,FBD_MM,FBD_Miko,FBD_Trunk,FBD_VL,FBD_VM,FBD_VR
 SG_ ControlBindingFBD_Data38 : 328|8@1+ (1.0,0) [0|255] "" FBD_HL,FBD_HM,FBD_HR,FBD_MM,FBD_Miko,FBD_Trunk,FBD_VL,FBD_VM,FBD_VR
 SG_ ControlBindingFBD_Data39 : 336|8@1+ (1.0,0) [0|255] "" FBD_HL,FBD_HM,FBD_HR,FBD_MM,FBD_Miko,FBD_Trunk,FBD_VL,FBD_VM,FBD_VR
 SG_ ControlBindingFBD_Data40 : 344|8@1+ (1.0,0) [0|255] "" FBD_HL,FBD_HM,FBD_HR,FBD_MM,FBD_Miko,FBD_Trunk,FBD_VL,FBD_VM,FBD_VR
 SG_ ControlBindingFBD_Data41 : 352|8@1+ (1.0,0) [0|255] "" FBD_HL,FBD_HM,FBD_HR,FBD_MM,FBD_Miko,FBD_Trunk,FBD_VL,FBD_VM,FBD_VR
 SG_ ControlBindingFBD_Data42 : 360|8@1+ (1.0,0) [0|255] "" FBD_HL,FBD_HM,FBD_HR,FBD_MM,FBD_Miko,FBD_Trunk,FBD_VL,FBD_VM,FBD_VR
 SG_ ControlBindingFBD_Data43 : 368|8@1+ (1.0,0) [0|255] "" FBD_HL,FBD_HM,FBD_HR,FBD_MM,FBD_Miko,FBD_Trunk,FBD_VL,FBD_VM,FBD_VR
 SG_ ControlBindingFBD_Data44 : 376|8@1+ (1.0,0) [0|255] "" FBD_HL,FBD_HM,FBD_HR,FBD_MM,FBD_Miko,FBD_Trunk,FBD_VL,FBD_VM,FBD_VR
 SG_ ControlBindingFBD_Data45 : 384|8@1+ (1.0,0) [0|255] "" FBD_HL,FBD_HM,FBD_HR,FBD_MM,FBD_Miko,FBD_Trunk,FBD_VL,FBD_VM,FBD_VR
 SG_ ControlBindingFBD_Data46 : 392|8@1+ (1.0,0) [0|255] "" FBD_HL,FBD_HM,FBD_HR,FBD_MM,FBD_Miko,FBD_Trunk,FBD_VL,FBD_VM,FBD_VR
 SG_ ControlBindingFBD_Data47 : 400|8@1+ (1.0,0) [0|255] "" FBD_HL,FBD_HM,FBD_HR,FBD_MM,FBD_Miko,FBD_Trunk,FBD_VL,FBD_VM,FBD_VR
 SG_ ControlBindingFBD_Data48 : 408|8@1+ (1.0,0) [0|255] "" FBD_HL,FBD_HM,FBD_HR,FBD_MM,FBD_Miko,FBD_Trunk,FBD_VL,FBD_VM,FBD_VR
 SG_ ControlBindingFBD_Data49 : 416|8@1+ (1.0,0) [0|255] "" FBD_HL,FBD_HM,FBD_HR,FBD_MM,FBD_Miko,FBD_Trunk,FBD_VL,FBD_VM,FBD_VR
 SG_ ControlBindingFBD_Data50 : 424|8@1+ (1.0,0) [0|255] "" FBD_HL,FBD_HM,FBD_HR,FBD_MM,FBD_Miko,FBD_Trunk,FBD_VL,FBD_VM,FBD_VR
 SG_ ControlBindingFBD_Data51 : 432|8@1+ (1.0,0) [0|255] "" FBD_HL,FBD_HM,FBD_HR,FBD_MM,FBD_Miko,FBD_Trunk,FBD_VL,FBD_VM,FBD_VR
 SG_ ControlBindingFBD_Data52 : 440|8@1+ (1.0,0) [0|255] "" FBD_HL,FBD_HM,FBD_HR,FBD_MM,FBD_Miko,FBD_Trunk,FBD_VL,FBD_VM,FBD_VR
 SG_ ControlBindingFBD_Data53 : 448|8@1+ (1.0,0) [0|255] "" FBD_HL,FBD_HM,FBD_HR,FBD_MM,FBD_Miko,FBD_Trunk,FBD_VL,FBD_VM,FBD_VR
 SG_ ControlBindingFBD_Data54 : 456|8@1+ (1.0,0) [0|255] "" FBD_HL,FBD_HM,FBD_HR,FBD_MM,FBD_Miko,FBD_Trunk,FBD_VL,FBD_VM,FBD_VR
 SG_ ControlBindingFBD_Data55 : 464|8@1+ (1.0,0) [0|255] "" FBD_HL,FBD_HM,FBD_HR,FBD_MM,FBD_Miko,FBD_Trunk,FBD_VL,FBD_VM,FBD_VR
 SG_ ControlBindingFBD_Data56 : 472|8@1+ (1.0,0) [0|255] "" FBD_HL,FBD_HM,FBD_HR,FBD_MM,FBD_Miko,FBD_Trunk,FBD_VL,FBD_VM,FBD_VR
 SG_ ControlBindingFBD_Data57 : 480|8@1+ (1.0,0) [0|255] "" FBD_HL,FBD_HM,FBD_HR,FBD_MM,FBD_Miko,FBD_Trunk,FBD_VL,FBD_VM,FBD_VR
 SG_ ControlBindingFBD_Data58 : 488|8@1+ (1.0,0) [0|255] "" FBD_HL,FBD_HM,FBD_HR,FBD_MM,FBD_Miko,FBD_Trunk,FBD_VL,FBD_VM,FBD_VR
 SG_ ControlBindingFBD_Data59 : 496|8@1+ (1.0,0) [0|255] "" FBD_HL,FBD_HM,FBD_HR,FBD_MM,FBD_Miko,FBD_Trunk,FBD_VL,FBD_VM,FBD_VR
 SG_ ControlBindingFBD_Data60 : 504|8@1+ (1.0,0) [0|255] "" FBD_HL,FBD_HM,FBD_HR,FBD_MM,FBD_Miko,FBD_Trunk,FBD_VL,FBD_VM,FBD_VR

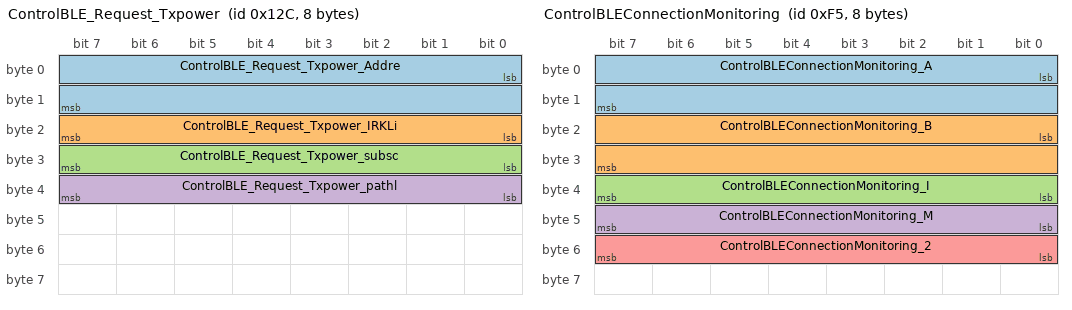
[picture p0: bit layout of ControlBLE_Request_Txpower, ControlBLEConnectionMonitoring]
BO_ 300 ControlBLE_Request_Txpower: 8 IPB_App1
 SG_ ControlBLE_Request_Txpower_Addre : 0|16@1+ (1,0) [0|0] "" FBD_HL,FBD_HM,FBD_HR,FBD_MM,FBD_Miko,FBD_Trunk,FBD_VL,FBD_VM,FBD_VR
 SG_ ControlBLE_Request_Txpower_IRKLi : 16|8@1+ (1.0,0) [0|252] "" FBD_HL,FBD_HM,FBD_HR,FBD_MM,FBD_Miko,FBD_Trunk,FBD_VL,FBD_VM,FBD_VR
 SG_ ControlBLE_Request_Txpower_subsc : 24|8@1+ (1,0) [0|0] "" FBD_HL,FBD_HM,FBD_HR,FBD_MM,FBD_Miko,FBD_Trunk,FBD_VL,FBD_VM,FBD_VR
 SG_ ControlBLE_Request_Txpower_pathl : 32|8@1+ (1,0) [0|0] "" FBD_HL,FBD_HM,FBD_HR,FBD_MM,FBD_Miko,FBD_Trunk,FBD_VL,FBD_VM,FBD_VR

BO_ 245 ControlBLEConnectionMonitoring: 8 IPB_App1
 SG_ ControlBLEConnectionMonitoring_A : 0|16@1+ (1,0) [0|0] "" FBD_HL,FBD_HM,FBD_HR,FBD_MM,FBD_Miko,FBD_Trunk,FBD_VL,FBD_VM,FBD_VR
 SG_ ControlBLEConnectionMonitoring_B : 16|16@1+ (1,0) [0|0] "" FBD_HL,FBD_HM,FBD_HR,FBD_MM,FBD_Miko,FBD_Trunk,FBD_VL,FBD_VM,FBD_VR
 SG_ ControlBLEConnectionMonitoring_I : 32|8@1+ (1.0,0) [0|252] "" FBD_HL,FBD_HM,FBD_HR,FBD_MM,FBD_Miko,FBD_Trunk,FBD_VL,FBD_VM,FBD_VR
 SG_ ControlBLEConnectionMonitoring_M : 40|8@1+ (1,0) [0|0] "" FBD_HL,FBD_HM,FBD_HR,FBD_MM,FBD_Miko,FBD_Trunk,FBD_VL,FBD_VM,FBD_VR
 SG_ ControlBLEConnectionMonitoring_2 : 48|8@1+ (10.0,0) [0|252] "ms" FBD_HL,FBD_HM,FBD_HR,FBD_MM,FBD_Miko,FBD_Trunk,FBD_VL,FBD_VM,FBD_VR

BO_ 383 ControlBLECS: 16 IPB_App1
 SG_ ControlBLECS_Address : 0|16@1+ (1,0) [0|0] "" FBD_HL,FBD_HM,FBD_HR,FBD_MM,FBD_Miko,FBD_Trunk,FBD_VL,FBD_VM,FBD_VR
 SG_ ControlBLECS_SessionID : 16|8@1+ (1.0,0) [0|252] "" FBD_HL,FBD_HM,FBD_HR,FBD_MM,FBD_Miko,FBD_Trunk,FBD_VL,FBD_VM,FBD_VR
 SG_ ControlBLECS_IRKListID : 24|8@1+ (1.0,0) [0|252] "" FBD_HL,FBD_HM,FBD_HR,FBD_MM,FBD_Miko,FBD_Trunk,FBD_VL,FBD_VM,FBD_VR
 SG_ ControlBLECS_DeviceGroup : 32|8@1+ (1.0,0) [0|252] "" FBD_HL,FBD_HM,FBD_HR,FBD_MM,FBD_Miko,FBD_Trunk,FBD_VL,FBD_VM,FBD_VR
 SG_ ControlBLECS_Algorithm : 40|8@1+ (1,0) [0|0] "" FBD_HL,FBD_HM,FBD_HR,FBD_MM,FBD_Miko,FBD_Trunk,FBD_VL,FBD_VM,FBD_VR
 SG_ ControlBLECS_DistanceOffset : 48|16@1+ (1.0,0) [0|65532] "" FBD_HL,FBD_HM,FBD_HR,FBD_MM,FBD_Miko,FBD_Trunk,FBD_VL,FBD_VM,FBD_VR
 SG_ ControlBLECS_AntennaConfig : 64|8@1+ (1,0) [0|0] "" FBD_HL,FBD_HM,FBD_HR,FBD_MM,FBD_Miko,FBD_Trunk,FBD_VL,FBD_VM,FBD_VR
 SG_ ControlBLECS_TxPower : 72|8@1+ (1.0,0) [0|252] "" FBD_HL,FBD_HM,FBD_HR,FBD_MM,FBD_Miko,FBD_Trunk,FBD_VL,FBD_VM,FBD_VR
 SG_ ControlBLECS_Role : 80|8@1+ (1,0) [0|0] "" FBD_HL,FBD_HM,FBD_HR,FBD_MM,FBD_Miko,FBD_Trunk,FBD_VL,FBD_VM,FBD_VR
 SG_ ControlBLECS_ProcedureResultsTra : 88|8@1+ (1,0) [0|0] "" FBD_HL,FBD_HM,FBD_HR,FBD_MM,FBD_Miko,FBD_Trunk,FBD_VL,FBD_VM,FBD_VR
 SG_ ControlBLECS_AntennaPathProcedur : 96|8@1+ (1,0) [0|0] "" FBD_HL,FBD_HM,FBD_HR,FBD_MM,FBD_Miko,FBD_Trunk,FBD_VL,FBD_VM,FBD_VR
 SG_ ControlBLECS_FBDonlyThreshold : 104|8@1+ (1.0,0) [0|252] "" FBD_HL,FBD_HM,FBD_HR,FBD_MM,FBD_Miko,FBD_Trunk,FBD_VL,FBD_VM,FBD_VR
 SG_ ControlBLECS_InlinePCT : 112|8@1+ (1,0) [0|0] "" FBD_HL,FBD_HM,FBD_HR,FBD_MM,FBD_Miko,FBD_Trunk,FBD_VL,FBD_VM,FBD_VR

BO_ 608 ControlBLEDeviceName: 32 IPB_App1
 SG_ ControlBLEDeviceName_Address : 0|16@1+ (1,0) [0|0] "" FBD_HL,FBD_HM,FBD_HR,FBD_MM,FBD_Miko,FBD_Trunk,FBD_VL,FBD_VM,FBD_VR
 SG_ ControlBLEDeviceName_Character00 : 16|8@1+ (1.0,0) [0|252] "" FBD_HL,FBD_HM,FBD_HR,FBD_MM,FBD_Miko,FBD_Trunk,FBD_VL,FBD_VM,FBD_VR
 SG_ ControlBLEDeviceName_Character01 : 24|8@1+ (1.0,0) [0|252] "" FBD_HL,FBD_HM,FBD_HR,FBD_MM,FBD_Miko,FBD_Trunk,FBD_VL,FBD_VM,FBD_VR
 SG_ ControlBLEDeviceName_Character02 : 32|8@1+ (1.0,0) [0|252] "" FBD_HL,FBD_HM,FBD_HR,FBD_MM,FBD_Miko,FBD_Trunk,FBD_VL,FBD_VM,FBD_VR
 SG_ ControlBLEDeviceName_Character03 : 40|8@1+ (1.0,0) [0|252] "" FBD_HL,FBD_HM,FBD_HR,FBD_MM,FBD_Miko,FBD_Trunk,FBD_VL,FBD_VM,FBD_VR
 SG_ ControlBLEDeviceName_Character04 : 48|8@1+ (1.0,0) [0|252] "" FBD_HL,FBD_HM,FBD_HR,FBD_MM,FBD_Miko,FBD_Trunk,FBD_VL,FBD_VM,FBD_VR
 SG_ ControlBLEDeviceName_Character05 : 56|8@1+ (1.0,0) [0|252] "" FBD_HL,FBD_HM,FBD_HR,FBD_MM,FBD_Miko,FBD_Trunk,FBD_VL,FBD_VM,FBD_VR
 SG_ ControlBLEDeviceName_Character06 : 64|8@1+ (1.0,0) [0|252] "" FBD_HL,FBD_HM,FBD_HR,FBD_MM,FBD_Miko,FBD_Trunk,FBD_VL,FBD_VM,FBD_VR
 SG_ ControlBLEDeviceName_Character07 : 72|8@1+ (1.0,0) [0|252] "" FBD_HL,FBD_HM,FBD_HR,FBD_MM,FBD_Miko,FBD_Trunk,FBD_VL,FBD_VM,FBD_VR
 SG_ ControlBLEDeviceName_Character08 : 80|8@1+ (1.0,0) [0|252] "" FBD_HL,FBD_HM,FBD_HR,FBD_MM,FBD_Miko,FBD_Trunk,FBD_VL,FBD_VM,FBD_VR
 SG_ ControlBLEDeviceName_Character09 : 88|8@1+ (1.0,0) [0|252] "" FBD_HL,FBD_HM,FBD_HR,FBD_MM,FBD_Miko,FBD_Trunk,FBD_VL,FBD_VM,FBD_VR
 SG_ ControlBLEDeviceName_Character10 : 96|8@1+ (1.0,0) [0|252] "" FBD_HL,FBD_HM,FBD_HR,FBD_MM,FBD_Miko,FBD_Trunk,FBD_VL,FBD_VM,FBD_VR
 SG_ ControlBLEDeviceName_Character11 : 104|8@1+ (1.0,0) [0|252] "" FBD_HL,FBD_HM,FBD_HR,FBD_MM,FBD_Miko,FBD_Trunk,FBD_VL,FBD_VM,FBD_VR
 SG_ ControlBLEDeviceName_Character12 : 112|8@1+ (1.0,0) [0|252] "" FBD_HL,FBD_HM,FBD_HR,FBD_MM,FBD_Miko,FBD_Trunk,FBD_VL,FBD_VM,FBD_VR
 SG_ ControlBLEDeviceName_Character13 : 120|8@1+ (1.0,0) [0|252] "" FBD_HL,FBD_HM,FBD_HR,FBD_MM,FBD_Miko,FBD_Trunk,FBD_VL,FBD_VM,FBD_VR
 SG_ ControlBLEDeviceName_Character14 : 128|8@1+ (1.0,0) [0|252] "" FBD_HL,FBD_HM,FBD_HR,FBD_MM,FBD_Miko,FBD_Trunk,FBD_VL,FBD_VM,FBD_VR
 SG_ ControlBLEDeviceName_Character15 : 136|8@1+ (1.0,0) [0|252] "" FBD_HL,FBD_HM,FBD_HR,FBD_MM,FBD_Miko,FBD_Trunk,FBD_VL,FBD_VM,FBD_VR
 SG_ ControlBLEDeviceName_Character16 : 144|8@1+ (1.0,0) [0|252] "" FBD_HL,FBD_HM,FBD_HR,FBD_MM,FBD_Miko,FBD_Trunk,FBD_VL,FBD_VM,FBD_VR
 SG_ ControlBLEDeviceName_Character17 : 152|8@1+ (1.0,0) [0|252] "" FBD_HL,FBD_HM,FBD_HR,FBD_MM,FBD_Miko,FBD_Trunk,FBD_VL,FBD_VM,FBD_VR
 SG_ ControlBLEDeviceName_Character18 : 160|8@1+ (1.0,0) [0|252] "" FBD_HL,FBD_HM,FBD_HR,FBD_MM,FBD_Miko,FBD_Trunk,FBD_VL,FBD_VM,FBD_VR
 SG_ ControlBLEDeviceName_Character19 : 168|8@1+ (1.0,0) [0|252] "" FBD_HL,FBD_HM,FBD_HR,FBD_MM,FBD_Miko,FBD_Trunk,FBD_VL,FBD_VM,FBD_VR
 SG_ ControlBLEDeviceName_Character20 : 176|8@1+ (1.0,0) [0|252] "" FBD_HL,FBD_HM,FBD_HR,FBD_MM,FBD_Miko,FBD_Trunk,FBD_VL,FBD_VM,FBD_VR
 SG_ ControlBLEDeviceName_Character21 : 184|8@1+ (1.0,0) [0|252] "" FBD_HL,FBD_HM,FBD_HR,FBD_MM,FBD_Miko,FBD_Trunk,FBD_VL,FBD_VM,FBD_VR
 SG_ ControlBLEDeviceName_Character22 : 192|8@1+ (1.0,0) [0|252] "" FBD_HL,FBD_HM,FBD_HR,FBD_MM,FBD_Miko,FBD_Trunk,FBD_VL,FBD_VM,FBD_VR
 SG_ ControlBLEDeviceName_Character23 : 200|8@1+ (1.0,0) [0|252] "" FBD_HL,FBD_HM,FBD_HR,FBD_MM,FBD_Miko,FBD_Trunk,FBD_VL,FBD_VM,FBD_VR
 SG_ ControlBLEDeviceName_Character24 : 208|8@1+ (1.0,0) [0|252] "" FBD_HL,FBD_HM,FBD_HR,FBD_MM,FBD_Miko,FBD_Trunk,FBD_VL,FBD_VM,FBD_VR
 SG_ ControlBLEDeviceName_Character25 : 216|8@1+ (1.0,0) [0|252] "" FBD_HL,FBD_HM,FBD_HR,FBD_MM,FBD_Miko,FBD_Trunk,FBD_VL,FBD_VM,FBD_VR
 SG_ ControlBLEDeviceName_Character26 : 224|8@1+ (1.0,0) [0|252] "" FBD_HL,FBD_HM,FBD_HR,FBD_MM,FBD_Miko,FBD_Trunk,FBD_VL,FBD_VM,FBD_VR
 SG_ ControlBLEDeviceName_Character27 : 232|8@1+ (1.0,0) [0|252] "" FBD_HL,FBD_HM,FBD_HR,FBD_MM,FBD_Miko,FBD_Trunk,FBD_VL,FBD_VM,FBD_VR
 SG_ ControlBLEDeviceName_Character28 : 240|8@1+ (1.0,0) [0|252] "" FBD_HL,FBD_HM,FBD_HR,FBD_MM,FBD_Miko,FBD_Trunk,FBD_VL,FBD_VM,FBD_VR
 SG_ ControlBLEDeviceName_Character29 : 248|8@1+ (1.0,0) [0|252] "" FBD_HL,FBD_HM,FBD_HR,FBD_MM,FBD_Miko,FBD_Trunk,FBD_VL,FBD_VM,FBD_VR

BO_ 200 ControlBLEInitialSettings: 20 IPB_App1
 SG_ ControlBLEInitialSettings_Addres : 0|16@1+ (1,0) [0|0] "" FBD_HL,FBD_HM,FBD_HR,FBD_MM,FBD_Miko,FBD_Trunk,FBD_VL,FBD_VM,FBD_VR
 SG_ ControlBLEInitialSettings_BLEOpe : 16|8@1+ (1,0) [0|0] "" FBD_HL,FBD_HM,FBD_HR,FBD_MM,FBD_Miko,FBD_Trunk,FBD_VL,FBD_VM,FBD_VR
 SG_ ControlBLEInitialSettings_Advert : 24|16@1+ (0.625,0) [0|40957] "ms" FBD_HL,FBD_HM,FBD_HR,FBD_MM,FBD_Miko,FBD_Trunk,FBD_VL,FBD_VM,FBD_VR
 SG_ ControlBLEInitialSettings_ScanWi : 40|16@1+ (0.625,0) [0|40957] "ms" FBD_HL,FBD_HM,FBD_HR,FBD_MM,FBD_Miko,FBD_Trunk,FBD_VL,FBD_VM,FBD_VR
 SG_ ControlBLEInitialSettings_enable : 56|8@1+ (1,0) [0|0] "" FBD_HL,FBD_HM,FBD_HR,FBD_MM,FBD_Miko,FBD_Trunk,FBD_VL,FBD_VM,FBD_VR
 SG_ ControlBLEInitialSettings_SetBLE : 64|8@1+ (1,0) [0|0] "" FBD_HL,FBD_HM,FBD_HR,FBD_MM,FBD_Miko,FBD_Trunk,FBD_VL,FBD_VM,FBD_VR
 SG_ ControlBLEInitialSettings_LR500_ : 72|16@1+ (0.625,0) [0|40957] "ms" FBD_HL,FBD_HM,FBD_HR,FBD_MM,FBD_Miko,FBD_Trunk,FBD_VL,FBD_VM,FBD_VR
 SG_ ControlBLEInitialSettings_LR125_ : 88|16@1+ (0.625,0) [0|40957] "ms" FBD_HL,FBD_HM,FBD_HR,FBD_MM,FBD_Miko,FBD_Trunk,FBD_VL,FBD_VM,FBD_VR
 SG_ ControlBLEInitialSettings_Enable : 104|8@1+ (1,0) [0|0] "" FBD_HL,FBD_HM,FBD_HR,FBD_MM,FBD_Miko,FBD_Trunk,FBD_VL,FBD_VM,FBD_VR
 SG_ ControlBLEInitialSettings_SetTxP : 112|8@1+ (1.0,0) [0|252] "" FBD_HL,FBD_HM,FBD_HR,FBD_MM,FBD_Miko,FBD_Trunk,FBD_VL,FBD_VM,FBD_VR
 SG_ ControlBLEInitialSettings_SetPSM : 120|8@1+ (1.0,0) [0|252] "" FBD_HL,FBD_HM,FBD_HR,FBD_MM,FBD_Miko,FBD_Trunk,FBD_VL,FBD_VM,FBD_VR
 SG_ ControlBLEInitialSettings_SetRPA : 128|8@1+ (1.0,0) [0|252] "" FBD_HL,FBD_HM,FBD_HR,FBD_MM,FBD_Miko,FBD_Trunk,FBD_VL,FBD_VM,FBD_VR
 SG_ ControlBLEInitialSettings_SetDCK : 136|8@1+ (1.0,0) [0|252] "" FBD_HL,FBD_HM,FBD_HR,FBD_MM,FBD_Miko,FBD_Trunk,FBD_VL,FBD_VM,FBD_VR
 SG_ ControlBLEInitialSettings_SetSca : 144|8@1+ (1,0) [0|0] "" FBD_HL,FBD_HM,FBD_HR,FBD_MM,FBD_Miko,FBD_Trunk,FBD_VL,FBD_VM,FBD_VR

BO_ 209 ControlBLERSSIRangingIntent: 16 IPB_App1
 SG_ ControlBLERSSIRangingIntent_Addr : 0|16@1+ (1,0) [0|0] "" FBD_HL,FBD_HM,FBD_HR,FBD_MM,FBD_Miko,FBD_Trunk,FBD_VL,FBD_VM,FBD_VR
 SG_ ControlBLERSSIRangingIntent_Acti : 16|8@1+ (1.0,0) [0|252] "" FBD_HL,FBD_HM,FBD_HR,FBD_MM,FBD_Miko,FBD_Trunk,FBD_VL,FBD_VM,FBD_VR
 SG_ ControlBLERSSIRangingIntent_Movi : 24|16@1+ (1.0,0) [0|65532] "ms" FBD_HL,FBD_HM,FBD_HR,FBD_MM,FBD_Miko,FBD_Trunk,FBD_VL,FBD_VM,FBD_VR
 SG_ ControlBLERSSIRangingIntent_FBD_ : 40|8@1+ (1.0,0) [0|252] "" FBD_HL,FBD_HM,FBD_HR,FBD_MM,FBD_Miko,FBD_Trunk,FBD_VL,FBD_VM,FBD_VR
 SG_ ControlBLERSSIRangingIntent_Mult : 48|8@1+ (1.0,0) [0|252] "" FBD_HL,FBD_HM,FBD_HR,FBD_MM,FBD_Miko,FBD_Trunk,FBD_VL,FBD_VM,FBD_VR
 SG_ ControlBLERSSIRangingIntent_IRKL : 56|8@1+ (1.0,0) [0|252] "" FBD_HL,FBD_HM,FBD_HR,FBD_MM,FBD_Miko,FBD_Trunk,FBD_VL,FBD_VM,FBD_VR
 SG_ ControlBLERSSIRangingIntent_BLEN : 64|16@1+ (1,0) [0|0] "" FBD_HL,FBD_HM,FBD_HR,FBD_MM,FBD_Miko,FBD_Trunk,FBD_VL,FBD_VM,FBD_VR
 SG_ ControlBLERSSIRangingIntent_MinN : 80|8@1+ (1.0,0) [0|252] "" FBD_HL,FBD_HM,FBD_HR,FBD_MM,FBD_Miko,FBD_Trunk,FBD_VL,FBD_VM,FBD_VR
 SG_ ControlBLERSSIRangingIntent_Devi : 88|8@1+ (1.0,0) [0|252] "" FBD_HL,FBD_HM,FBD_HR,FBD_MM,FBD_Miko,FBD_Trunk,FBD_VL,FBD_VM,FBD_VR

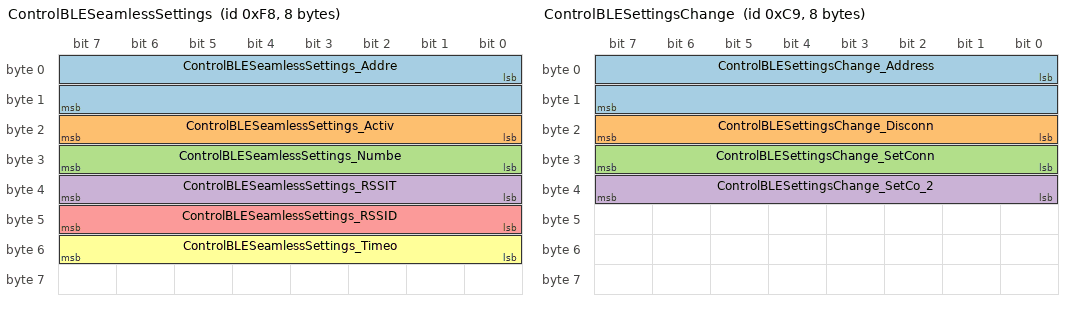
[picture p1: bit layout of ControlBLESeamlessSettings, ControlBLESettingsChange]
BO_ 248 ControlBLESeamlessSettings: 8 IPB_App1
 SG_ ControlBLESeamlessSettings_Addre : 0|16@1+ (1,0) [0|0] "" FBD_HL,FBD_HM,FBD_HR,FBD_MM,FBD_Miko,FBD_Trunk,FBD_VL,FBD_VM,FBD_VR
 SG_ ControlBLESeamlessSettings_Activ : 16|8@1+ (1.0,0) [0|252] "" FBD_HL,FBD_HM,FBD_HR,FBD_MM,FBD_Miko,FBD_Trunk,FBD_VL,FBD_VM,FBD_VR
 SG_ ControlBLESeamlessSettings_Numbe : 24|8@1+ (1.0,0) [0|252] "" FBD_HL,FBD_HM,FBD_HR,FBD_MM,FBD_Miko,FBD_Trunk,FBD_VL,FBD_VM,FBD_VR
 SG_ ControlBLESeamlessSettings_RSSIT : 32|8@1+ (0.5,-127) [-127|-1] "dB" FBD_HL,FBD_HM,FBD_HR,FBD_MM,FBD_Miko,FBD_Trunk,FBD_VL,FBD_VM,FBD_VR
 SG_ ControlBLESeamlessSettings_RSSID : 40|8@1+ (0.5,0) [0|126] "dB" FBD_HL,FBD_HM,FBD_HR,FBD_MM,FBD_Miko,FBD_Trunk,FBD_VL,FBD_VM,FBD_VR
 SG_ ControlBLESeamlessSettings_Timeo : 48|8@1+ (1.0,0) [0|252] "ms" FBD_HL,FBD_HM,FBD_HR,FBD_MM,FBD_Miko,FBD_Trunk,FBD_VL,FBD_VM,FBD_VR

BO_ 201 ControlBLESettingsChange: 8 IPB_App1
 SG_ ControlBLESettingsChange_Address : 0|16@1+ (1,0) [0|0] "" FBD_HL,FBD_HM,FBD_HR,FBD_MM,FBD_Miko,FBD_Trunk,FBD_VL,FBD_VM,FBD_VR
 SG_ ControlBLESettingsChange_Disconn : 16|8@1+ (1.0,0) [0|252] "" FBD_HL,FBD_HM,FBD_HR,FBD_MM,FBD_Miko,FBD_Trunk,FBD_VL,FBD_VM,FBD_VR
 SG_ ControlBLESettingsChange_SetConn : 24|8@1+ (1.0,0) [0|252] "" FBD_HL,FBD_HM,FBD_HR,FBD_MM,FBD_Miko,FBD_Trunk,FBD_VL,FBD_VM,FBD_VR
 SG_ ControlBLESettingsChange_SetCo_2 : 32|8@1+ (1.0,0) [0|252] "" FBD_HL,FBD_HM,FBD_HR,FBD_MM,FBD_Miko,FBD_Trunk,FBD_VL,FBD_VM,FBD_VR

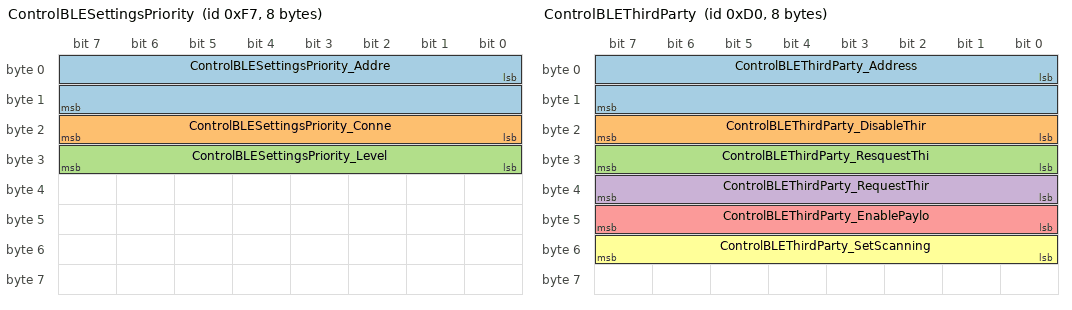
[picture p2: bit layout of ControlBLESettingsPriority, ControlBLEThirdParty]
BO_ 247 ControlBLESettingsPriority: 8 IPB_App1
 SG_ ControlBLESettingsPriority_Addre : 0|16@1+ (1,0) [0|0] "" FBD_HL,FBD_HM,FBD_HR,FBD_MM,FBD_Miko,FBD_Trunk,FBD_VL,FBD_VM,FBD_VR
 SG_ ControlBLESettingsPriority_Conne : 16|8@1+ (1.0,0) [0|252] "" FBD_HL,FBD_HM,FBD_HR,FBD_MM,FBD_Miko,FBD_Trunk,FBD_VL,FBD_VM,FBD_VR
 SG_ ControlBLESettingsPriority_Level : 24|8@1+ (1,0) [0|0] "" FBD_HL,FBD_HM,FBD_HR,FBD_MM,FBD_Miko,FBD_Trunk,FBD_VL,FBD_VM,FBD_VR

BO_ 208 ControlBLEThirdParty: 8 IPB_App1
 SG_ ControlBLEThirdParty_Address : 0|16@1+ (1,0) [0|0] "" FBD_HL,FBD_HM,FBD_HR,FBD_MM,FBD_Miko,FBD_Trunk,FBD_VL,FBD_VM,FBD_VR
 SG_ ControlBLEThirdParty_DisableThir : 16|8@1+ (1,0) [0|0] "" FBD_HL,FBD_HM,FBD_HR,FBD_MM,FBD_Miko,FBD_Trunk,FBD_VL,FBD_VM,FBD_VR
 SG_ ControlBLEThirdParty_ResquestThi : 24|8@1+ (1,0) [0|0] "" FBD_HL,FBD_HM,FBD_HR,FBD_MM,FBD_Miko,FBD_Trunk,FBD_VL,FBD_VM,FBD_VR
 SG_ ControlBLEThirdParty_RequestThir : 32|8@1+ (1.0,0) [0|252] "" FBD_HL,FBD_HM,FBD_HR,FBD_MM,FBD_Miko,FBD_Trunk,FBD_VL,FBD_VM,FBD_VR
 SG_ ControlBLEThirdParty_EnablePaylo : 40|8@1+ (1,0) [0|0] "" FBD_HL,FBD_HM,FBD_HR,FBD_MM,FBD_Miko,FBD_Trunk,FBD_VL,FBD_VM,FBD_VR
 SG_ ControlBLEThirdParty_SetScanning : 48|8@1+ (1,0) [0|0] "" FBD_HL,FBD_HM,FBD_HR,FBD_MM,FBD_Miko,FBD_Trunk,FBD_VL,FBD_VM,FBD_VR

BO_ 600 ControlConfigurationFBD: 20 IPB_App1
 SG_ ControlConfigurationFBD_Address : 0|16@1+ (1,0) [0|0] "" FBD_HL,FBD_HM,FBD_HR,FBD_MM,FBD_Miko,FBD_Trunk,FBD_VL,FBD_VM,FBD_VR
 SG_ ControlConfigurationFBD_DeviceGr : 16|8@1+ (1.0,0) [0|252] "" FBD_HL,FBD_HM,FBD_HR,FBD_MM,FBD_Miko,FBD_Trunk,FBD_VL,FBD_VM,FBD_VR
 SG_ ControlConfigurationFBD_IRKListI : 24|8@1+ (1.0,0) [0|252] "" FBD_HL,FBD_HM,FBD_HR,FBD_MM,FBD_Miko,FBD_Trunk,FBD_VL,FBD_VM,FBD_VR
 SG_ ControlConfigurationFBD_RSSIRang : 32|8@1+ (1.0,0) [0|252] "" FBD_HL,FBD_HM,FBD_HR,FBD_MM,FBD_Miko,FBD_Trunk,FBD_VL,FBD_VM,FBD_VR
 SG_ ControlConfigurationFBD_RSSIRa_2 : 40|8@1+ (1.0,0) [0|252] "" FBD_HL,FBD_HM,FBD_HR,FBD_MM,FBD_Miko,FBD_Trunk,FBD_VL,FBD_VM,FBD_VR
 SG_ ControlConfigurationFBD_FBD_Only : 48|8@1+ (1.0,0) [0|252] "" FBD_HL,FBD_HM,FBD_HR,FBD_MM,FBD_Miko,FBD_Trunk,FBD_VL,FBD_VM,FBD_VR
 SG_ ControlConfigurationFBD_UWBDutyC : 56|8@1+ (0.5,0) [0|126] "ms" FBD_HL,FBD_HM,FBD_HR,FBD_MM,FBD_Miko,FBD_Trunk,FBD_VL,FBD_VM,FBD_VR
 SG_ ControlConfigurationFBD_UWBDut_2 : 64|8@1+ (0.1,0) [0|25.2] "s" FBD_HL,FBD_HM,FBD_HR,FBD_MM,FBD_Miko,FBD_Trunk,FBD_VL,FBD_VM,FBD_VR
 SG_ ControlConfigurationFBD_UWBDut_3 : 72|8@1+ (0.5,0) [0|126] "ms" FBD_HL,FBD_HM,FBD_HR,FBD_MM,FBD_Miko,FBD_Trunk,FBD_VL,FBD_VM,FBD_VR
 SG_ ControlConfigurationFBD_FBDonlyW : 80|8@1+ (0.1,0) [0|25.2] "m" FBD_HL,FBD_HM,FBD_HR,FBD_MM,FBD_Miko,FBD_Trunk,FBD_VL,FBD_VM,FBD_VR
 SG_ ControlConfigurationFBD_FBDonlyR : 88|8@1+ (1,0) [0|0] "" FBD_HL,FBD_HM,FBD_HR,FBD_MM,FBD_Miko,FBD_Trunk,FBD_VL,FBD_VM,FBD_VR
 SG_ ControlConfigurationFBD_FBDonl_2 : 96|8@1+ (1.0,0) [0|252] "s" FBD_HL,FBD_HM,FBD_HR,FBD_MM,FBD_Miko,FBD_Trunk,FBD_VL,FBD_VM,FBD_VR
 SG_ ControlConfigurationFBD_FBDonl_3 : 104|8@1+ (1.0,0) [0|252] "" FBD_HL,FBD_HM,FBD_HR,FBD_MM,FBD_Miko,FBD_Trunk,FBD_VL,FBD_VM,FBD_VR
 SG_ ControlConfigurationFBD_FBDonl_4 : 112|8@1+ (1.0,0) [0|252] "s" FBD_HL,FBD_HM,FBD_HR,FBD_MM,FBD_Miko,FBD_Trunk,FBD_VL,FBD_VM,FBD_VR
 SG_ ControlConfigurationFBD_FBDonl_5 : 120|8@1+ (1.0,0) [0|252] "s" FBD_HL,FBD_HM,FBD_HR,FBD_MM,FBD_Miko,FBD_Trunk,FBD_VL,FBD_VM,FBD_VR
 SG_ ControlConfigurationFBD_FBDonl_6 : 128|8@1+ (1.0,0) [0|252] "min" FBD_HL,FBD_HM,FBD_HR,FBD_MM,FBD_Miko,FBD_Trunk,FBD_VL,FBD_VM,FBD_VR
 SG_ ControlConfigurationFBD_FBDonl_7 : 136|8@1+ (1.0,0) [0|252] "" FBD_HL,FBD_HM,FBD_HR,FBD_MM,FBD_Miko,FBD_Trunk,FBD_VL,FBD_VM,FBD_VR
 SG_ ControlConfigurationFBD_FBDonlyD : 144|8@1+ (1,0) [0|0] "" FBD_HL,FBD_HM,FBD_HR,FBD_MM,FBD_Miko,FBD_Trunk,FBD_VL,FBD_VM,FBD_VR

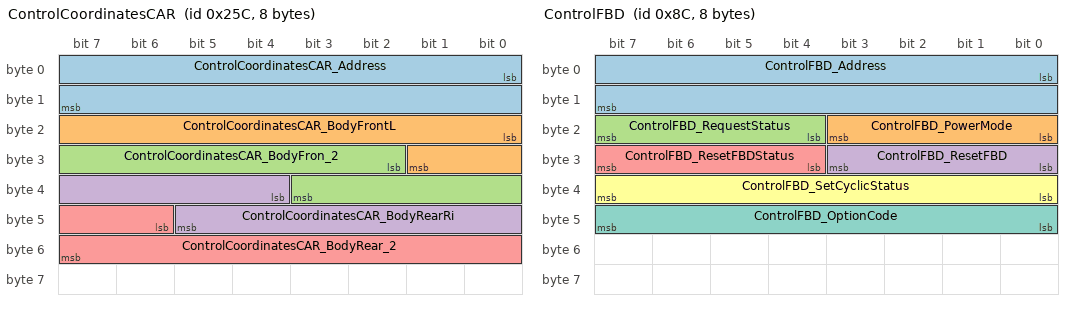
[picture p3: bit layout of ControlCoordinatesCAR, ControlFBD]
BO_ 604 ControlCoordinatesCAR: 8 IPB_App1
 SG_ ControlCoordinatesCAR_Address : 0|16@1+ (1,0) [0|0] "" FBD_HL,FBD_HM,FBD_HR,FBD_MM,FBD_Miko,FBD_Trunk,FBD_VL,FBD_VM,FBD_VR
 SG_ ControlCoordinatesCAR_BodyFrontL : 16|10@1+ (1.0,-250) [-250|770] "cm" FBD_HL,FBD_HM,FBD_HR,FBD_MM,FBD_Miko,FBD_Trunk,FBD_VL,FBD_VM,FBD_VR
 SG_ ControlCoordinatesCAR_BodyFron_2 : 26|10@1+ (1.0,-250) [-250|770] "cm" FBD_HL,FBD_HM,FBD_HR,FBD_MM,FBD_Miko,FBD_Trunk,FBD_VL,FBD_VM,FBD_VR
 SG_ ControlCoordinatesCAR_BodyRearRi : 36|10@1+ (1.0,-250) [-250|770] "cm" FBD_HL,FBD_HM,FBD_HR,FBD_MM,FBD_Miko,FBD_Trunk,FBD_VL,FBD_VM,FBD_VR
 SG_ ControlCoordinatesCAR_BodyRear_2 : 46|10@1+ (1.0,-250) [-250|770] "cm" FBD_HL,FBD_HM,FBD_HR,FBD_MM,FBD_Miko,FBD_Trunk,FBD_VL,FBD_VM,FBD_VR

BO_ 603 ControlCoordinatesFBD: 64 IPB_App1
 SG_ ControlCoordinatesFBD_Address : 0|16@1+ (1,0) [0|0] "" FBD_HL,FBD_HM,FBD_HR,FBD_MM,FBD_Miko,FBD_Trunk,FBD_VL,FBD_VM,FBD_VR
 SG_ ControlCoordinatesFBD_VM_X : 16|10@1+ (1.0,-250) [-250|770] "cm" FBD_HL,FBD_HM,FBD_HR,FBD_MM,FBD_Miko,FBD_Trunk,FBD_VL,FBD_VM,FBD_VR
 SG_ ControlCoordinatesFBD_VM_Y : 26|10@1+ (1.0,-250) [-250|770] "cm" FBD_HL,FBD_HM,FBD_HR,FBD_MM,FBD_Miko,FBD_Trunk,FBD_VL,FBD_VM,FBD_VR
 SG_ ControlCoordinatesFBD_VM_Z : 36|10@1+ (1.0,-250) [-250|770] "cm" FBD_HL,FBD_HM,FBD_HR,FBD_MM,FBD_Miko,FBD_Trunk,FBD_VL,FBD_VM,FBD_VR
 SG_ ControlCoordinatesFBD_VM_azimuth : 46|9@1+ (1.0,-180) [-180|180] "°" FBD_HL,FBD_HM,FBD_HR,FBD_MM,FBD_Miko,FBD_Trunk,FBD_VL,FBD_VM,FBD_VR
 SG_ ControlCoordinatesFBD_VM_elevati : 55|8@1+ (1.0,-100) [-100|100] "°" FBD_HL,FBD_HM,FBD_HR,FBD_MM,FBD_Miko,FBD_Trunk,FBD_VL,FBD_VM,FBD_VR
 SG_ ControlCoordinatesFBD_HM_X : 63|10@1+ (1.0,-250) [-250|770] "cm" FBD_HL,FBD_HM,FBD_HR,FBD_MM,FBD_Miko,FBD_Trunk,FBD_VL,FBD_VM,FBD_VR
 SG_ ControlCoordinatesFBD_HM_Y : 73|10@1+ (1.0,-250) [-250|770] "cm" FBD_HL,FBD_HM,FBD_HR,FBD_MM,FBD_Miko,FBD_Trunk,FBD_VL,FBD_VM,FBD_VR
 SG_ ControlCoordinatesFBD_HM_Z : 83|10@1+ (1.0,-250) [-250|770] "cm" FBD_HL,FBD_HM,FBD_HR,FBD_MM,FBD_Miko,FBD_Trunk,FBD_VL,FBD_VM,FBD_VR
 SG_ ControlCoordinatesFBD_HM_azimuth : 93|9@1+ (1.0,-180) [-180|180] "°" FBD_HL,FBD_HM,FBD_HR,FBD_MM,FBD_Miko,FBD_Trunk,FBD_VL,FBD_VM,FBD_VR
 SG_ ControlCoordinatesFBD_HM_elevati : 102|8@1+ (1.0,-100) [-100|100] "°" FBD_HL,FBD_HM,FBD_HR,FBD_MM,FBD_Miko,FBD_Trunk,FBD_VL,FBD_VM,FBD_VR
 SG_ ControlCoordinatesFBD_Miko_X : 110|10@1+ (1.0,-250) [-250|770] "cm" FBD_HL,FBD_HM,FBD_HR,FBD_MM,FBD_Miko,FBD_Trunk,FBD_VL,FBD_VM,FBD_VR
 SG_ ControlCoordinatesFBD_Miko_Y : 120|10@1+ (1.0,-250) [-250|770] "cm" FBD_HL,FBD_HM,FBD_HR,FBD_MM,FBD_Miko,FBD_Trunk,FBD_VL,FBD_VM,FBD_VR
 SG_ ControlCoordinatesFBD_Miko_Z : 130|10@1+ (1.0,-250) [-250|770] "cm" FBD_HL,FBD_HM,FBD_HR,FBD_MM,FBD_Miko,FBD_Trunk,FBD_VL,FBD_VM,FBD_VR
 SG_ ControlCoordinatesFBD_Miko_azimu : 140|9@1+ (1.0,-180) [-180|180] "°" FBD_HL,FBD_HM,FBD_HR,FBD_MM,FBD_Miko,FBD_Trunk,FBD_VL,FBD_VM,FBD_VR
 SG_ ControlCoordinatesFBD_Miko_eleva : 149|8@1+ (1.0,-100) [-100|100] "°" FBD_HL,FBD_HM,FBD_HR,FBD_MM,FBD_Miko,FBD_Trunk,FBD_VL,FBD_VM,FBD_VR
 SG_ ControlCoordinatesFBD_Trunk_X : 157|10@1+ (1.0,-250) [-250|770] "cm" FBD_HL,FBD_HM,FBD_HR,FBD_MM,FBD_Miko,FBD_Trunk,FBD_VL,FBD_VM,FBD_VR
 SG_ ControlCoordinatesFBD_Trunk_Y : 167|10@1+ (1.0,-250) [-250|770] "cm" FBD_HL,FBD_HM,FBD_HR,FBD_MM,FBD_Miko,FBD_Trunk,FBD_VL,FBD_VM,FBD_VR
 SG_ ControlCoordinatesFBD_Trunk_Z : 177|10@1+ (1.0,-250) [-250|770] "cm" FBD_HL,FBD_HM,FBD_HR,FBD_MM,FBD_Miko,FBD_Trunk,FBD_VL,FBD_VM,FBD_VR
 SG_ ControlCoordinatesFBD_Trunk_azim : 187|9@1+ (1.0,-180) [-180|180] "°" FBD_HL,FBD_HM,FBD_HR,FBD_MM,FBD_Miko,FBD_Trunk,FBD_VL,FBD_VM,FBD_VR
 SG_ ControlCoordinatesFBD_Trunk_elev : 196|8@1+ (1.0,-100) [-100|100] "°" FBD_HL,FBD_HM,FBD_HR,FBD_MM,FBD_Miko,FBD_Trunk,FBD_VL,FBD_VM,FBD_VR
 SG_ ControlCoordinatesFBD_VL_X : 204|10@1+ (1.0,-250) [-250|770] "cm" FBD_HL,FBD_HM,FBD_HR,FBD_MM,FBD_Miko,FBD_Trunk,FBD_VL,FBD_VM,FBD_VR
 SG_ ControlCoordinatesFBD_VL_Y : 214|10@1+ (1.0,-250) [-250|770] "cm" FBD_HL,FBD_HM,FBD_HR,FBD_MM,FBD_Miko,FBD_Trunk,FBD_VL,FBD_VM,FBD_VR
 SG_ ControlCoordinatesFBD_VL_Z : 224|10@1+ (1.0,-250) [-250|770] "cm" FBD_HL,FBD_HM,FBD_HR,FBD_MM,FBD_Miko,FBD_Trunk,FBD_VL,FBD_VM,FBD_VR
 SG_ ControlCoordinatesFBD_VL_azimuth : 234|9@1+ (1.0,-180) [-180|180] "°" FBD_HL,FBD_HM,FBD_HR,FBD_MM,FBD_Miko,FBD_Trunk,FBD_VL,FBD_VM,FBD_VR
 SG_ ControlCoordinatesFBD_VL_elevati : 243|8@1+ (1.0,-100) [-100|100] "°" FBD_HL,FBD_HM,FBD_HR,FBD_MM,FBD_Miko,FBD_Trunk,FBD_VL,FBD_VM,FBD_VR
 SG_ ControlCoordinatesFBD_VR_X : 251|10@1+ (1.0,-250) [-250|770] "cm" FBD_HL,FBD_HM,FBD_HR,FBD_MM,FBD_Miko,FBD_Trunk,FBD_VL,FBD_VM,FBD_VR
 SG_ ControlCoordinatesFBD_VR_Y : 261|10@1+ (1.0,-250) [-250|770] "cm" FBD_HL,FBD_HM,FBD_HR,FBD_MM,FBD_Miko,FBD_Trunk,FBD_VL,FBD_VM,FBD_VR
 SG_ ControlCoordinatesFBD_VR_Z : 271|10@1+ (1.0,-250) [-250|770] "cm" FBD_HL,FBD_HM,FBD_HR,FBD_MM,FBD_Miko,FBD_Trunk,FBD_VL,FBD_VM,FBD_VR
 SG_ ControlCoordinatesFBD_VR_azimuth : 281|9@1+ (1.0,-180) [-180|180] "°" FBD_HL,FBD_HM,FBD_HR,FBD_MM,FBD_Miko,FBD_Trunk,FBD_VL,FBD_VM,FBD_VR
 SG_ ControlCoordinatesFBD_VR_elevati : 290|8@1+ (1.0,-100) [-100|100] "°" FBD_HL,FBD_HM,FBD_HR,FBD_MM,FBD_Miko,FBD_Trunk,FBD_VL,FBD_VM,FBD_VR
 SG_ ControlCoordinatesFBD_HL_X : 298|10@1+ (1.0,-250) [-250|770] "cm" FBD_HL,FBD_HM,FBD_HR,FBD_MM,FBD_Miko,FBD_Trunk,FBD_VL,FBD_VM,FBD_VR
 SG_ ControlCoordinatesFBD_HL_Y : 308|10@1+ (1.0,-250) [-250|770] "cm" FBD_HL,FBD_HM,FBD_HR,FBD_MM,FBD_Miko,FBD_Trunk,FBD_VL,FBD_VM,FBD_VR
 SG_ ControlCoordinatesFBD_HL_Z : 318|10@1+ (1.0,-250) [-250|770] "cm" FBD_HL,FBD_HM,FBD_HR,FBD_MM,FBD_Miko,FBD_Trunk,FBD_VL,FBD_VM,FBD_VR
 SG_ ControlCoordinatesFBD_HL_azimuth : 328|9@1+ (1.0,-180) [-180|180] "°" FBD_HL,FBD_HM,FBD_HR,FBD_MM,FBD_Miko,FBD_Trunk,FBD_VL,FBD_VM,FBD_VR
 SG_ ControlCoordinatesFBD_HL_elevati : 337|8@1+ (1.0,-100) [-100|100] "°" FBD_HL,FBD_HM,FBD_HR,FBD_MM,FBD_Miko,FBD_Trunk,FBD_VL,FBD_VM,FBD_VR
 SG_ ControlCoordinatesFBD_HR_X : 345|10@1+ (1.0,-250) [-250|770] "cm" FBD_HL,FBD_HM,FBD_HR,FBD_MM,FBD_Miko,FBD_Trunk,FBD_VL,FBD_VM,FBD_VR
 SG_ ControlCoordinatesFBD_HR_Y : 355|10@1+ (1.0,-250) [-250|770] "cm" FBD_HL,FBD_HM,FBD_HR,FBD_MM,FBD_Miko,FBD_Trunk,FBD_VL,FBD_VM,FBD_VR
 SG_ ControlCoordinatesFBD_HR_Z : 365|10@1+ (1.0,-250) [-250|770] "cm" FBD_HL,FBD_HM,FBD_HR,FBD_MM,FBD_Miko,FBD_Trunk,FBD_VL,FBD_VM,FBD_VR
 SG_ ControlCoordinatesFBD_HR_azimuth : 375|9@1+ (1.0,-180) [-180|180] "°" FBD_HL,FBD_HM,FBD_HR,FBD_MM,FBD_Miko,FBD_Trunk,FBD_VL,FBD_VM,FBD_VR
 SG_ ControlCoordinatesFBD_HR_elevati : 384|8@1+ (1.0,-100) [-100|100] "°" FBD_HL,FBD_HM,FBD_HR,FBD_MM,FBD_Miko,FBD_Trunk,FBD_VL,FBD_VM,FBD_VR
 SG_ ControlCoordinatesFBD_SML_X : 392|10@1+ (1.0,-250) [-250|770] "cm" FBD_HL,FBD_HM,FBD_HR,FBD_MM,FBD_Miko,FBD_Trunk,FBD_VL,FBD_VM,FBD_VR
 SG_ ControlCoordinatesFBD_SML_Y : 402|10@1+ (1.0,-250) [-250|770] "cm" FBD_HL,FBD_HM,FBD_HR,FBD_MM,FBD_Miko,FBD_Trunk,FBD_VL,FBD_VM,FBD_VR
 SG_ ControlCoordinatesFBD_SML_Z : 412|10@1+ (1.0,-250) [-250|770] "cm" FBD_HL,FBD_HM,FBD_HR,FBD_MM,FBD_Miko,FBD_Trunk,FBD_VL,FBD_VM,FBD_VR
 SG_ ControlCoordinatesFBD_SML_azimut : 422|9@1+ (1.0,-180) [-180|180] "°" FBD_HL,FBD_HM,FBD_HR,FBD_MM,FBD_Miko,FBD_Trunk,FBD_VL,FBD_VM,FBD_VR
 SG_ ControlCoordinatesFBD_SML_elevat : 431|8@1+ (1.0,-100) [-100|100] "°" FBD_HL,FBD_HM,FBD_HR,FBD_MM,FBD_Miko,FBD_Trunk,FBD_VL,FBD_VM,FBD_VR
 SG_ ControlCoordinatesFBD_SMR_X : 439|10@1+ (1.0,-250) [-250|770] "cm" FBD_HL,FBD_HM,FBD_HR,FBD_MM,FBD_Miko,FBD_Trunk,FBD_VL,FBD_VM,FBD_VR
 SG_ ControlCoordinatesFBD_SMR_Y : 449|10@1+ (1.0,-250) [-250|770] "cm" FBD_HL,FBD_HM,FBD_HR,FBD_MM,FBD_Miko,FBD_Trunk,FBD_VL,FBD_VM,FBD_VR
 SG_ ControlCoordinatesFBD_SMR_Z : 459|10@1+ (1.0,-250) [-250|770] "cm" FBD_HL,FBD_HM,FBD_HR,FBD_MM,FBD_Miko,FBD_Trunk,FBD_VL,FBD_VM,FBD_VR
 SG_ ControlCoordinatesFBD_SMR_azimut : 469|9@1+ (1.0,-180) [-180|180] "°" FBD_HL,FBD_HM,FBD_HR,FBD_MM,FBD_Miko,FBD_Trunk,FBD_VL,FBD_VM,FBD_VR
 SG_ ControlCoordinatesFBD_SMR_elevat : 478|8@1+ (1.0,-100) [-100|100] "°" FBD_HL,FBD_HM,FBD_HR,FBD_MM,FBD_Miko,FBD_Trunk,FBD_VL,FBD_VM,FBD_VR

BO_ 302 ControlCPDSession: 20 IPB_App1
 SG_ ControlCPDSession_Address : 0|16@1+ (1,0) [0|0] "" FBD_HL,FBD_HM,FBD_HR,FBD_MM,FBD_Miko,FBD_Trunk,FBD_VL,FBD_VM,FBD_VR
 SG_ ControlCPDSession_Command : 16|8@1+ (1,0) [0|0] "" FBD_HL,FBD_HM,FBD_HR,FBD_MM,FBD_Miko,FBD_Trunk,FBD_VL,FBD_VM,FBD_VR
 SG_ ControlCPDSession_SensitivityBoo : 24|8@1+ (1,0) [0|0] "" FBD_HL,FBD_HM,FBD_HR,FBD_MM,FBD_Miko,FBD_Trunk,FBD_VL,FBD_VM,FBD_VR
 SG_ ControlCPDSession_CycleTime : 32|8@1+ (1,0) [0|0] "" FBD_HL,FBD_HM,FBD_HR,FBD_MM,FBD_Miko,FBD_Trunk,FBD_VL,FBD_VM,FBD_VR
 SG_ ControlCPDSession_Channel : 40|8@1+ (1,0) [0|0] "" FBD_HL,FBD_HM,FBD_HR,FBD_MM,FBD_Miko,FBD_Trunk,FBD_VL,FBD_VM,FBD_VR
 SG_ ControlCPDSession_NoiseSuppressi : 48|8@1+ (1,0) [0|0] "" FBD_HL,FBD_HM,FBD_HR,FBD_MM,FBD_Miko,FBD_Trunk,FBD_VL,FBD_VM,FBD_VR
 SG_ ControlCPDSession_SessionPriorit : 56|8@1+ (1.0,0) [0|252] "" FBD_HL,FBD_HM,FBD_HR,FBD_MM,FBD_Miko,FBD_Trunk,FBD_VL,FBD_VM,FBD_VR
 SG_ ControlCPDSession_Sign : 64|32@1+ (1.0,0) [0|4294967294] "" FBD_HL,FBD_HM,FBD_HR,FBD_MM,FBD_Miko,FBD_Trunk,FBD_VL,FBD_VM,FBD_VR
 SG_ ControlCPDSession_Data00 : 96|8@1+ (1.0,0) [0|255] "" FBD_HL,FBD_HM,FBD_HR,FBD_MM,FBD_Miko,FBD_Trunk,FBD_VL,FBD_VM,FBD_VR
 SG_ ControlCPDSession_Data01 : 104|8@1+ (1.0,0) [0|255] "" FBD_HL,FBD_HM,FBD_HR,FBD_MM,FBD_Miko,FBD_Trunk,FBD_VL,FBD_VM,FBD_VR
 SG_ ControlCPDSession_Data02 : 112|8@1+ (1.0,0) [0|255] "" FBD_HL,FBD_HM,FBD_HR,FBD_MM,FBD_Miko,FBD_Trunk,FBD_VL,FBD_VM,FBD_VR
 SG_ ControlCPDSession_Data03 : 120|8@1+ (1.0,0) [0|255] "" FBD_HL,FBD_HM,FBD_HR,FBD_MM,FBD_Miko,FBD_Trunk,FBD_VL,FBD_VM,FBD_VR
 SG_ ControlCPDSession_Data04 : 128|8@1+ (1.0,0) [0|255] "" FBD_HL,FBD_HM,FBD_HR,FBD_MM,FBD_Miko,FBD_Trunk,FBD_VL,FBD_VM,FBD_VR
 SG_ ControlCPDSession_Data05 : 136|8@1+ (1.0,0) [0|255] "" FBD_HL,FBD_HM,FBD_HR,FBD_MM,FBD_Miko,FBD_Trunk,FBD_VL,FBD_VM,FBD_VR
 SG_ ControlCPDSession_Data06 : 144|8@1+ (1.0,0) [0|255] "" FBD_HL,FBD_HM,FBD_HR,FBD_MM,FBD_Miko,FBD_Trunk,FBD_VL,FBD_VM,FBD_VR
 SG_ ControlCPDSession_Data07 : 152|8@1+ (1.0,0) [0|255] "" FBD_HL,FBD_HM,FBD_HR,FBD_MM,FBD_Miko,FBD_Trunk,FBD_VL,FBD_VM,FBD_VR

BO_ 140 ControlFBD: 8 IPB_App1
 SG_ ControlFBD_Address : 0|16@1+ (1,0) [0|0] "" FBD_HL,FBD_HM,FBD_HR,FBD_MM,FBD_Miko,FBD_Trunk,FBD_VL,FBD_VM,FBD_VR
 SG_ ControlFBD_PowerMode : 16|4@1+ (1,0) [0|0] "" FBD_HL,FBD_HM,FBD_HR,FBD_MM,FBD_Miko,FBD_Trunk,FBD_VL,FBD_VM,FBD_VR
 SG_ ControlFBD_RequestStatus : 20|4@1+ (1.0,0) [0|12] "" FBD_HL,FBD_HM,FBD_HR,FBD_MM,FBD_Miko,FBD_Trunk,FBD_VL,FBD_VM,FBD_VR
 SG_ ControlFBD_ResetFBD : 24|4@1+ (1.0,0) [0|12] "" FBD_HL,FBD_HM,FBD_HR,FBD_MM,FBD_Miko,FBD_Trunk,FBD_VL,FBD_VM,FBD_VR
 SG_ ControlFBD_ResetFBDStatus : 28|4@1+ (1.0,0) [0|12] "" FBD_HL,FBD_HM,FBD_HR,FBD_MM,FBD_Miko,FBD_Trunk,FBD_VL,FBD_VM,FBD_VR
 SG_ ControlFBD_SetCyclicStatus : 32|8@1+ (1.0,0) [0|252] "" FBD_HL,FBD_HM,FBD_HR,FBD_MM,FBD_Miko,FBD_Trunk,FBD_VL,FBD_VM,FBD_VR
 SG_ ControlFBD_OptionCode : 40|8@1+ (1,0) [0|0] "" FBD_HL,FBD_HM,FBD_HR,FBD_MM,FBD_Miko,FBD_Trunk,FBD_VL,FBD_VM,FBD_VR

BO_ 402 ControlRangingSession: 20 IPB_App1
 SG_ ControlRangingSession_Address : 0|16@1+ (1,0) [0|0] "" FBD_HL,FBD_HM,FBD_HR,FBD_MM,FBD_Miko,FBD_Trunk,FBD_VL,FBD_VM,FBD_VR
 SG_ ControlRangingSession_Function : 16|8@1+ (1,0) [0|0] "" FBD_HL,FBD_HM,FBD_HR,FBD_MM,FBD_Miko,FBD_Trunk,FBD_VL,FBD_VM,FBD_VR
 SG_ ControlRangingSession_SessionIDS : 24|8@1+ (1.0,0) [0|252] "" FBD_HL,FBD_HM,FBD_HR,FBD_MM,FBD_Miko,FBD_Trunk,FBD_VL,FBD_VM,FBD_VR
 SG_ ControlRangingSession_STSIndex : 32|32@1+ (1.0,0) [0|4294967292] "" FBD_HL,FBD_HM,FBD_HR,FBD_MM,FBD_Miko,FBD_Trunk,FBD_VL,FBD_VM,FBD_VR
 SG_ ControlRangingSession_RANmultipl : 64|8@1+ (1.0,0) [0|252] "" FBD_HL,FBD_HM,FBD_HR,FBD_MM,FBD_Miko,FBD_Trunk,FBD_VL,FBD_VM,FBD_VR
 SG_ ControlRangingSession_UWBTime0 : 72|64@1+ (1.0,0) [0|18446744073709551612] "" FBD_HL,FBD_HM,FBD_HR,FBD_MM,FBD_Miko,FBD_Trunk,FBD_VL,FBD_VM,FBD_VR

BO_ 400 ControlRangingSessionSetup1: 64 IPB_App1
 SG_ ControlRangingSessionSetup1_Addr : 0|16@1+ (1,0) [0|0] "" FBD_HL,FBD_HM,FBD_HR,FBD_MM,FBD_Miko,FBD_Trunk,FBD_VL,FBD_VM,FBD_VR
 SG_ ControlRangingSessionSetup1_Sess : 16|8@1+ (1.0,0) [0|252] "" FBD_HL,FBD_HM,FBD_HR,FBD_MM,FBD_Miko,FBD_Trunk,FBD_VL,FBD_VM,FBD_VR
 SG_ ControlRangingSessionSetup1_Conf : 24|16@1+ (1.0,0) [0|65532] "" FBD_HL,FBD_HM,FBD_HR,FBD_MM,FBD_Miko,FBD_Trunk,FBD_VL,FBD_VM,FBD_VR
 SG_ ControlRangingSessionSetup1_Co_2 : 40|8@1+ (1,0) [0|0] "" FBD_HL,FBD_HM,FBD_HR,FBD_MM,FBD_Miko,FBD_Trunk,FBD_VL,FBD_VM,FBD_VR
 SG_ ControlRangingSessionSetup1_Auto : 48|8@1+ (1,0) [0|0] "" FBD_HL,FBD_HM,FBD_HR,FBD_MM,FBD_Miko,FBD_Trunk,FBD_VL,FBD_VM,FBD_VR
 SG_ ControlRangingSessionSetup1_Bitm : 56|16@1+ (1,0) [0|0] "" FBD_HL,FBD_HM,FBD_HR,FBD_MM,FBD_Miko,FBD_Trunk,FBD_VL,FBD_VM,FBD_VR
 SG_ ControlRangingSessionSetup1_Prot : 72|16@1+ (1.0,0) [0|65532] "" FBD_HL,FBD_HM,FBD_HR,FBD_MM,FBD_Miko,FBD_Trunk,FBD_VL,FBD_VM,FBD_VR
 SG_ ControlRangingSessionSetup1_Data : 88|8@1+ (1.0,0) [0|255] "" FBD_HL,FBD_HM,FBD_HR,FBD_MM,FBD_Miko,FBD_Trunk,FBD_VL,FBD_VM,FBD_VR
 SG_ ControlRangingSessionSetup1_Da_2 : 96|8@1+ (1.0,0) [0|255] "" FBD_HL,FBD_HM,FBD_HR,FBD_MM,FBD_Miko,FBD_Trunk,FBD_VL,FBD_VM,FBD_VR
 SG_ ControlRangingSessionSetup1_Da_3 : 104|8@1+ (1.0,0) [0|255] "" FBD_HL,FBD_HM,FBD_HR,FBD_MM,FBD_Miko,FBD_Trunk,FBD_VL,FBD_VM,FBD_VR
 SG_ ControlRangingSessionSetup1_Da_4 : 112|8@1+ (1.0,0) [0|255] "" FBD_HL,FBD_HM,FBD_HR,FBD_MM,FBD_Miko,FBD_Trunk,FBD_VL,FBD_VM,FBD_VR
 SG_ ControlRangingSessionSetup1_Da_5 : 120|8@1+ (1.0,0) [0|255] "" FBD_HL,FBD_HM,FBD_HR,FBD_MM,FBD_Miko,FBD_Trunk,FBD_VL,FBD_VM,FBD_VR
 SG_ ControlRangingSessionSetup1_Da_6 : 128|8@1+ (1.0,0) [0|255] "" FBD_HL,FBD_HM,FBD_HR,FBD_MM,FBD_Miko,FBD_Trunk,FBD_VL,FBD_VM,FBD_VR
 SG_ ControlRangingSessionSetup1_Da_7 : 136|8@1+ (1.0,0) [0|255] "" FBD_HL,FBD_HM,FBD_HR,FBD_MM,FBD_Miko,FBD_Trunk,FBD_VL,FBD_VM,FBD_VR
 SG_ ControlRangingSessionSetup1_Da_8 : 144|8@1+ (1.0,0) [0|255] "" FBD_HL,FBD_HM,FBD_HR,FBD_MM,FBD_Miko,FBD_Trunk,FBD_VL,FBD_VM,FBD_VR
 SG_ ControlRangingSessionSetup1_Da_9 : 152|8@1+ (1.0,0) [0|255] "" FBD_HL,FBD_HM,FBD_HR,FBD_MM,FBD_Miko,FBD_Trunk,FBD_VL,FBD_VM,FBD_VR
 SG_ ControlRangingSessionSetup1_D_10 : 160|8@1+ (1.0,0) [0|255] "" FBD_HL,FBD_HM,FBD_HR,FBD_MM,FBD_Miko,FBD_Trunk,FBD_VL,FBD_VM,FBD_VR
 SG_ ControlRangingSessionSetup1_D_11 : 168|8@1+ (1.0,0) [0|255] "" FBD_HL,FBD_HM,FBD_HR,FBD_MM,FBD_Miko,FBD_Trunk,FBD_VL,FBD_VM,FBD_VR
 SG_ ControlRangingSessionSetup1_D_12 : 176|8@1+ (1.0,0) [0|255] "" FBD_HL,FBD_HM,FBD_HR,FBD_MM,FBD_Miko,FBD_Trunk,FBD_VL,FBD_VM,FBD_VR
 SG_ ControlRangingSessionSetup1_D_13 : 184|8@1+ (1.0,0) [0|255] "" FBD_HL,FBD_HM,FBD_HR,FBD_MM,FBD_Miko,FBD_Trunk,FBD_VL,FBD_VM,FBD_VR
 SG_ ControlRangingSessionSetup1_D_14 : 192|8@1+ (1.0,0) [0|255] "" FBD_HL,FBD_HM,FBD_HR,FBD_MM,FBD_Miko,FBD_Trunk,FBD_VL,FBD_VM,FBD_VR
 SG_ ControlRangingSessionSetup1_D_15 : 200|8@1+ (1.0,0) [0|255] "" FBD_HL,FBD_HM,FBD_HR,FBD_MM,FBD_Miko,FBD_Trunk,FBD_VL,FBD_VM,FBD_VR
 SG_ ControlRangingSessionSetup1_D_16 : 208|8@1+ (1.0,0) [0|255] "" FBD_HL,FBD_HM,FBD_HR,FBD_MM,FBD_Miko,FBD_Trunk,FBD_VL,FBD_VM,FBD_VR
 SG_ ControlRangingSessionSetup1_D_17 : 216|8@1+ (1.0,0) [0|255] "" FBD_HL,FBD_HM,FBD_HR,FBD_MM,FBD_Miko,FBD_Trunk,FBD_VL,FBD_VM,FBD_VR
 SG_ ControlRangingSessionSetup1_D_18 : 224|8@1+ (1.0,0) [0|255] "" FBD_HL,FBD_HM,FBD_HR,FBD_MM,FBD_Miko,FBD_Trunk,FBD_VL,FBD_VM,FBD_VR
 SG_ ControlRangingSessionSetup1_D_19 : 232|8@1+ (1.0,0) [0|255] "" FBD_HL,FBD_HM,FBD_HR,FBD_MM,FBD_Miko,FBD_Trunk,FBD_VL,FBD_VM,FBD_VR
 SG_ ControlRangingSessionSetup1_D_20 : 240|8@1+ (1.0,0) [0|255] "" FBD_HL,FBD_HM,FBD_HR,FBD_MM,FBD_Miko,FBD_Trunk,FBD_VL,FBD_VM,FBD_VR
 SG_ ControlRangingSessionSetup1_D_21 : 248|8@1+ (1.0,0) [0|255] "" FBD_HL,FBD_HM,FBD_HR,FBD_MM,FBD_Miko,FBD_Trunk,FBD_VL,FBD_VM,FBD_VR
 SG_ ControlRangingSessionSetup1_D_22 : 256|8@1+ (1.0,0) [0|255] "" FBD_HL,FBD_HM,FBD_HR,FBD_MM,FBD_Miko,FBD_Trunk,FBD_VL,FBD_VM,FBD_VR
 SG_ ControlRangingSessionSetup1_D_23 : 264|8@1+ (1.0,0) [0|255] "" FBD_HL,FBD_HM,FBD_HR,FBD_MM,FBD_Miko,FBD_Trunk,FBD_VL,FBD_VM,FBD_VR
 SG_ ControlRangingSessionSetup1_D_24 : 272|8@1+ (1.0,0) [0|255] "" FBD_HL,FBD_HM,FBD_HR,FBD_MM,FBD_Miko,FBD_Trunk,FBD_VL,FBD_VM,FBD_VR
 SG_ ControlRangingSessionSetup1_D_25 : 280|8@1+ (1.0,0) [0|255] "" FBD_HL,FBD_HM,FBD_HR,FBD_MM,FBD_Miko,FBD_Trunk,FBD_VL,FBD_VM,FBD_VR
 SG_ ControlRangingSessionSetup1_D_26 : 288|8@1+ (1.0,0) [0|255] "" FBD_HL,FBD_HM,FBD_HR,FBD_MM,FBD_Miko,FBD_Trunk,FBD_VL,FBD_VM,FBD_VR
 SG_ ControlRangingSessionSetup1_D_27 : 296|8@1+ (1.0,0) [0|255] "" FBD_HL,FBD_HM,FBD_HR,FBD_MM,FBD_Miko,FBD_Trunk,FBD_VL,FBD_VM,FBD_VR
 SG_ ControlRangingSessionSetup1_D_28 : 304|8@1+ (1.0,0) [0|255] "" FBD_HL,FBD_HM,FBD_HR,FBD_MM,FBD_Miko,FBD_Trunk,FBD_VL,FBD_VM,FBD_VR
 SG_ ControlRangingSessionSetup1_D_29 : 312|8@1+ (1.0,0) [0|255] "" FBD_HL,FBD_HM,FBD_HR,FBD_MM,FBD_Miko,FBD_Trunk,FBD_VL,FBD_VM,FBD_VR
 SG_ ControlRangingSessionSetup1_D_30 : 320|8@1+ (1.0,0) [0|255] "" FBD_HL,FBD_HM,FBD_HR,FBD_MM,FBD_Miko,FBD_Trunk,FBD_VL,FBD_VM,FBD_VR
 SG_ ControlRangingSessionSetup1_D_31 : 328|8@1+ (1.0,0) [0|255] "" FBD_HL,FBD_HM,FBD_HR,FBD_MM,FBD_Miko,FBD_Trunk,FBD_VL,FBD_VM,FBD_VR
 SG_ ControlRangingSessionSetup1_D_32 : 336|8@1+ (1.0,0) [0|255] "" FBD_HL,FBD_HM,FBD_HR,FBD_MM,FBD_Miko,FBD_Trunk,FBD_VL,FBD_VM,FBD_VR
 SG_ ControlRangingSessionSetup1_D_33 : 344|8@1+ (1.0,0) [0|255] "" FBD_HL,FBD_HM,FBD_HR,FBD_MM,FBD_Miko,FBD_Trunk,FBD_VL,FBD_VM,FBD_VR
 SG_ ControlRangingSessionSetup1_D_34 : 352|8@1+ (1.0,0) [0|255] "" FBD_HL,FBD_HM,FBD_HR,FBD_MM,FBD_Miko,FBD_Trunk,FBD_VL,FBD_VM,FBD_VR
 SG_ ControlRangingSessionSetup1_D_35 : 360|8@1+ (1.0,0) [0|255] "" FBD_HL,FBD_HM,FBD_HR,FBD_MM,FBD_Miko,FBD_Trunk,FBD_VL,FBD_VM,FBD_VR
 SG_ ControlRangingSessionSetup1_D_36 : 368|8@1+ (1.0,0) [0|255] "" FBD_HL,FBD_HM,FBD_HR,FBD_MM,FBD_Miko,FBD_Trunk,FBD_VL,FBD_VM,FBD_VR
 SG_ ControlRangingSessionSetup1_D_37 : 376|8@1+ (1.0,0) [0|255] "" FBD_HL,FBD_HM,FBD_HR,FBD_MM,FBD_Miko,FBD_Trunk,FBD_VL,FBD_VM,FBD_VR
 SG_ ControlRangingSessionSetup1_D_38 : 384|8@1+ (1.0,0) [0|255] "" FBD_HL,FBD_HM,FBD_HR,FBD_MM,FBD_Miko,FBD_Trunk,FBD_VL,FBD_VM,FBD_VR
 SG_ ControlRangingSessionSetup1_D_39 : 392|8@1+ (1.0,0) [0|255] "" FBD_HL,FBD_HM,FBD_HR,FBD_MM,FBD_Miko,FBD_Trunk,FBD_VL,FBD_VM,FBD_VR
 SG_ ControlRangingSessionSetup1_D_40 : 400|8@1+ (1.0,0) [0|255] "" FBD_HL,FBD_HM,FBD_HR,FBD_MM,FBD_Miko,FBD_Trunk,FBD_VL,FBD_VM,FBD_VR
 SG_ ControlRangingSessionSetup1_D_41 : 408|8@1+ (1.0,0) [0|255] "" FBD_HL,FBD_HM,FBD_HR,FBD_MM,FBD_Miko,FBD_Trunk,FBD_VL,FBD_VM,FBD_VR
 SG_ ControlRangingSessionSetup1_D_42 : 416|8@1+ (1.0,0) [0|255] "" FBD_HL,FBD_HM,FBD_HR,FBD_MM,FBD_Miko,FBD_Trunk,FBD_VL,FBD_VM,FBD_VR
 SG_ ControlRangingSessionSetup1_D_43 : 424|8@1+ (1.0,0) [0|255] "" FBD_HL,FBD_HM,FBD_HR,FBD_MM,FBD_Miko,FBD_Trunk,FBD_VL,FBD_VM,FBD_VR
 SG_ ControlRangingSessionSetup1_D_44 : 432|8@1+ (1.0,0) [0|255] "" FBD_HL,FBD_HM,FBD_HR,FBD_MM,FBD_Miko,FBD_Trunk,FBD_VL,FBD_VM,FBD_VR
 SG_ ControlRangingSessionSetup1_D_45 : 440|8@1+ (1.0,0) [0|255] "" FBD_HL,FBD_HM,FBD_HR,FBD_MM,FBD_Miko,FBD_Trunk,FBD_VL,FBD_VM,FBD_VR
 SG_ ControlRangingSessionSetup1_D_46 : 448|8@1+ (1.0,0) [0|255] "" FBD_HL,FBD_HM,FBD_HR,FBD_MM,FBD_Miko,FBD_Trunk,FBD_VL,FBD_VM,FBD_VR
 SG_ ControlRangingSessionSetup1_D_47 : 456|8@1+ (1.0,0) [0|255] "" FBD_HL,FBD_HM,FBD_HR,FBD_MM,FBD_Miko,FBD_Trunk,FBD_VL,FBD_VM,FBD_VR
 SG_ ControlRangingSessionSetup1_D_48 : 464|8@1+ (1.0,0) [0|255] "" FBD_HL,FBD_HM,FBD_HR,FBD_MM,FBD_Miko,FBD_Trunk,FBD_VL,FBD_VM,FBD_VR
 SG_ ControlRangingSessionSetup1_D_49 : 472|8@1+ (1.0,0) [0|255] "" FBD_HL,FBD_HM,FBD_HR,FBD_MM,FBD_Miko,FBD_Trunk,FBD_VL,FBD_VM,FBD_VR
 SG_ ControlRangingSessionSetup1_D_50 : 480|8@1+ (1.0,0) [0|255] "" FBD_HL,FBD_HM,FBD_HR,FBD_MM,FBD_Miko,FBD_Trunk,FBD_VL,FBD_VM,FBD_VR
 SG_ ControlRangingSessionSetup1_D_51 : 488|8@1+ (1.0,0) [0|255] "" FBD_HL,FBD_HM,FBD_HR,FBD_MM,FBD_Miko,FBD_Trunk,FBD_VL,FBD_VM,FBD_VR
 SG_ ControlRangingSessionSetup1_D_52 : 496|8@1+ (1.0,0) [0|255] "" FBD_HL,FBD_HM,FBD_HR,FBD_MM,FBD_Miko,FBD_Trunk,FBD_VL,FBD_VM,FBD_VR
 SG_ ControlRangingSessionSetup1_D_53 : 504|8@1+ (1.0,0) [0|255] "" FBD_HL,FBD_HM,FBD_HR,FBD_MM,FBD_Miko,FBD_Trunk,FBD_VL,FBD_VM,FBD_VR

BO_ 401 ControlRangingSessionSetup2: 64 IPB_App1
 SG_ ControlRangingSessionSetup2_Addr : 0|16@1+ (1,0) [0|0] "" FBD_HL,FBD_HM,FBD_HR,FBD_MM,FBD_Miko,FBD_Trunk,FBD_VL,FBD_VM,FBD_VR
 SG_ ControlRangingSessionSetup2_Sess : 16|8@1+ (1.0,0) [0|252] "" FBD_HL,FBD_HM,FBD_HR,FBD_MM,FBD_Miko,FBD_Trunk,FBD_VL,FBD_VM,FBD_VR
 SG_ ControlRangingSessionSetup2_Data : 24|8@1+ (1.0,0) [0|255] "" FBD_HL,FBD_HM,FBD_HR,FBD_MM,FBD_Miko,FBD_Trunk,FBD_VL,FBD_VM,FBD_VR
 SG_ ControlRangingSessionSetup2_Da_2 : 32|8@1+ (1.0,0) [0|255] "" FBD_HL,FBD_HM,FBD_HR,FBD_MM,FBD_Miko,FBD_Trunk,FBD_VL,FBD_VM,FBD_VR
 SG_ ControlRangingSessionSetup2_Da_3 : 40|8@1+ (1.0,0) [0|255] "" FBD_HL,FBD_HM,FBD_HR,FBD_MM,FBD_Miko,FBD_Trunk,FBD_VL,FBD_VM,FBD_VR
 SG_ ControlRangingSessionSetup2_Da_4 : 48|8@1+ (1.0,0) [0|255] "" FBD_HL,FBD_HM,FBD_HR,FBD_MM,FBD_Miko,FBD_Trunk,FBD_VL,FBD_VM,FBD_VR
 SG_ ControlRangingSessionSetup2_Da_5 : 56|8@1+ (1.0,0) [0|255] "" FBD_HL,FBD_HM,FBD_HR,FBD_MM,FBD_Miko,FBD_Trunk,FBD_VL,FBD_VM,FBD_VR
 SG_ ControlRangingSessionSetup2_Da_6 : 64|8@1+ (1.0,0) [0|255] "" FBD_HL,FBD_HM,FBD_HR,FBD_MM,FBD_Miko,FBD_Trunk,FBD_VL,FBD_VM,FBD_VR
 SG_ ControlRangingSessionSetup2_Da_7 : 72|8@1+ (1.0,0) [0|255] "" FBD_HL,FBD_HM,FBD_HR,FBD_MM,FBD_Miko,FBD_Trunk,FBD_VL,FBD_VM,FBD_VR
 SG_ ControlRangingSessionSetup2_Da_8 : 80|8@1+ (1.0,0) [0|255] "" FBD_HL,FBD_HM,FBD_HR,FBD_MM,FBD_Miko,FBD_Trunk,FBD_VL,FBD_VM,FBD_VR
 SG_ ControlRangingSessionSetup2_Da_9 : 88|8@1+ (1.0,0) [0|255] "" FBD_HL,FBD_HM,FBD_HR,FBD_MM,FBD_Miko,FBD_Trunk,FBD_VL,FBD_VM,FBD_VR
 SG_ ControlRangingSessionSetup2_D_10 : 96|8@1+ (1.0,0) [0|255] "" FBD_HL,FBD_HM,FBD_HR,FBD_MM,FBD_Miko,FBD_Trunk,FBD_VL,FBD_VM,FBD_VR
 SG_ ControlRangingSessionSetup2_D_11 : 104|8@1+ (1.0,0) [0|255] "" FBD_HL,FBD_HM,FBD_HR,FBD_MM,FBD_Miko,FBD_Trunk,FBD_VL,FBD_VM,FBD_VR
 SG_ ControlRangingSessionSetup2_D_12 : 112|8@1+ (1.0,0) [0|255] "" FBD_HL,FBD_HM,FBD_HR,FBD_MM,FBD_Miko,FBD_Trunk,FBD_VL,FBD_VM,FBD_VR
 SG_ ControlRangingSessionSetup2_D_13 : 120|8@1+ (1.0,0) [0|255] "" FBD_HL,FBD_HM,FBD_HR,FBD_MM,FBD_Miko,FBD_Trunk,FBD_VL,FBD_VM,FBD_VR
 SG_ ControlRangingSessionSetup2_D_14 : 128|8@1+ (1.0,0) [0|255] "" FBD_HL,FBD_HM,FBD_HR,FBD_MM,FBD_Miko,FBD_Trunk,FBD_VL,FBD_VM,FBD_VR
 SG_ ControlRangingSessionSetup2_D_15 : 136|8@1+ (1.0,0) [0|255] "" FBD_HL,FBD_HM,FBD_HR,FBD_MM,FBD_Miko,FBD_Trunk,FBD_VL,FBD_VM,FBD_VR
 SG_ ControlRangingSessionSetup2_D_16 : 144|8@1+ (1.0,0) [0|255] "" FBD_HL,FBD_HM,FBD_HR,FBD_MM,FBD_Miko,FBD_Trunk,FBD_VL,FBD_VM,FBD_VR
 SG_ ControlRangingSessionSetup2_D_17 : 152|8@1+ (1.0,0) [0|255] "" FBD_HL,FBD_HM,FBD_HR,FBD_MM,FBD_Miko,FBD_Trunk,FBD_VL,FBD_VM,FBD_VR
 SG_ ControlRangingSessionSetup2_D_18 : 160|8@1+ (1.0,0) [0|255] "" FBD_HL,FBD_HM,FBD_HR,FBD_MM,FBD_Miko,FBD_Trunk,FBD_VL,FBD_VM,FBD_VR
 SG_ ControlRangingSessionSetup2_D_19 : 168|8@1+ (1.0,0) [0|255] "" FBD_HL,FBD_HM,FBD_HR,FBD_MM,FBD_Miko,FBD_Trunk,FBD_VL,FBD_VM,FBD_VR
 SG_ ControlRangingSessionSetup2_D_20 : 176|8@1+ (1.0,0) [0|255] "" FBD_HL,FBD_HM,FBD_HR,FBD_MM,FBD_Miko,FBD_Trunk,FBD_VL,FBD_VM,FBD_VR
 SG_ ControlRangingSessionSetup2_D_21 : 184|8@1+ (1.0,0) [0|255] "" FBD_HL,FBD_HM,FBD_HR,FBD_MM,FBD_Miko,FBD_Trunk,FBD_VL,FBD_VM,FBD_VR
 SG_ ControlRangingSessionSetup2_D_22 : 192|8@1+ (1.0,0) [0|255] "" FBD_HL,FBD_HM,FBD_HR,FBD_MM,FBD_Miko,FBD_Trunk,FBD_VL,FBD_VM,FBD_VR
 SG_ ControlRangingSessionSetup2_D_23 : 200|8@1+ (1.0,0) [0|255] "" FBD_HL,FBD_HM,FBD_HR,FBD_MM,FBD_Miko,FBD_Trunk,FBD_VL,FBD_VM,FBD_VR
 SG_ ControlRangingSessionSetup2_D_24 : 208|8@1+ (1.0,0) [0|255] "" FBD_HL,FBD_HM,FBD_HR,FBD_MM,FBD_Miko,FBD_Trunk,FBD_VL,FBD_VM,FBD_VR
 SG_ ControlRangingSessionSetup2_D_25 : 216|8@1+ (1.0,0) [0|255] "" FBD_HL,FBD_HM,FBD_HR,FBD_MM,FBD_Miko,FBD_Trunk,FBD_VL,FBD_VM,FBD_VR
 SG_ ControlRangingSessionSetup2_D_26 : 224|8@1+ (1.0,0) [0|255] "" FBD_HL,FBD_HM,FBD_HR,FBD_MM,FBD_Miko,FBD_Trunk,FBD_VL,FBD_VM,FBD_VR
 SG_ ControlRangingSessionSetup2_D_27 : 232|8@1+ (1.0,0) [0|255] "" FBD_HL,FBD_HM,FBD_HR,FBD_MM,FBD_Miko,FBD_Trunk,FBD_VL,FBD_VM,FBD_VR
 SG_ ControlRangingSessionSetup2_D_28 : 240|8@1+ (1.0,0) [0|255] "" FBD_HL,FBD_HM,FBD_HR,FBD_MM,FBD_Miko,FBD_Trunk,FBD_VL,FBD_VM,FBD_VR
 SG_ ControlRangingSessionSetup2_D_29 : 248|8@1+ (1.0,0) [0|255] "" FBD_HL,FBD_HM,FBD_HR,FBD_MM,FBD_Miko,FBD_Trunk,FBD_VL,FBD_VM,FBD_VR
 SG_ ControlRangingSessionSetup2_D_30 : 256|8@1+ (1.0,0) [0|255] "" FBD_HL,FBD_HM,FBD_HR,FBD_MM,FBD_Miko,FBD_Trunk,FBD_VL,FBD_VM,FBD_VR
 SG_ ControlRangingSessionSetup2_D_31 : 264|8@1+ (1.0,0) [0|255] "" FBD_HL,FBD_HM,FBD_HR,FBD_MM,FBD_Miko,FBD_Trunk,FBD_VL,FBD_VM,FBD_VR
 SG_ ControlRangingSessionSetup2_D_32 : 272|8@1+ (1.0,0) [0|255] "" FBD_HL,FBD_HM,FBD_HR,FBD_MM,FBD_Miko,FBD_Trunk,FBD_VL,FBD_VM,FBD_VR
 SG_ ControlRangingSessionSetup2_D_33 : 280|8@1+ (1.0,0) [0|255] "" FBD_HL,FBD_HM,FBD_HR,FBD_MM,FBD_Miko,FBD_Trunk,FBD_VL,FBD_VM,FBD_VR
 SG_ ControlRangingSessionSetup2_D_34 : 288|8@1+ (1.0,0) [0|255] "" FBD_HL,FBD_HM,FBD_HR,FBD_MM,FBD_Miko,FBD_Trunk,FBD_VL,FBD_VM,FBD_VR
 SG_ ControlRangingSessionSetup2_D_35 : 296|8@1+ (1.0,0) [0|255] "" FBD_HL,FBD_HM,FBD_HR,FBD_MM,FBD_Miko,FBD_Trunk,FBD_VL,FBD_VM,FBD_VR
 SG_ ControlRangingSessionSetup2_D_36 : 304|8@1+ (1.0,0) [0|255] "" FBD_HL,FBD_HM,FBD_HR,FBD_MM,FBD_Miko,FBD_Trunk,FBD_VL,FBD_VM,FBD_VR
 SG_ ControlRangingSessionSetup2_D_37 : 312|8@1+ (1.0,0) [0|255] "" FBD_HL,FBD_HM,FBD_HR,FBD_MM,FBD_Miko,FBD_Trunk,FBD_VL,FBD_VM,FBD_VR
 SG_ ControlRangingSessionSetup2_D_38 : 320|8@1+ (1.0,0) [0|255] "" FBD_HL,FBD_HM,FBD_HR,FBD_MM,FBD_Miko,FBD_Trunk,FBD_VL,FBD_VM,FBD_VR
 SG_ ControlRangingSessionSetup2_D_39 : 328|8@1+ (1.0,0) [0|255] "" FBD_HL,FBD_HM,FBD_HR,FBD_MM,FBD_Miko,FBD_Trunk,FBD_VL,FBD_VM,FBD_VR
 SG_ ControlRangingSessionSetup2_D_40 : 336|8@1+ (1.0,0) [0|255] "" FBD_HL,FBD_HM,FBD_HR,FBD_MM,FBD_Miko,FBD_Trunk,FBD_VL,FBD_VM,FBD_VR
 SG_ ControlRangingSessionSetup2_D_41 : 344|8@1+ (1.0,0) [0|255] "" FBD_HL,FBD_HM,FBD_HR,FBD_MM,FBD_Miko,FBD_Trunk,FBD_VL,FBD_VM,FBD_VR
 SG_ ControlRangingSessionSetup2_D_42 : 352|8@1+ (1.0,0) [0|255] "" FBD_HL,FBD_HM,FBD_HR,FBD_MM,FBD_Miko,FBD_Trunk,FBD_VL,FBD_VM,FBD_VR
 SG_ ControlRangingSessionSetup2_D_43 : 360|8@1+ (1.0,0) [0|255] "" FBD_HL,FBD_HM,FBD_HR,FBD_MM,FBD_Miko,FBD_Trunk,FBD_VL,FBD_VM,FBD_VR
 SG_ ControlRangingSessionSetup2_D_44 : 368|8@1+ (1.0,0) [0|255] "" FBD_HL,FBD_HM,FBD_HR,FBD_MM,FBD_Miko,FBD_Trunk,FBD_VL,FBD_VM,FBD_VR
 SG_ ControlRangingSessionSetup2_D_45 : 376|8@1+ (1.0,0) [0|255] "" FBD_HL,FBD_HM,FBD_HR,FBD_MM,FBD_Miko,FBD_Trunk,FBD_VL,FBD_VM,FBD_VR
 SG_ ControlRangingSessionSetup2_D_46 : 384|8@1+ (1.0,0) [0|255] "" FBD_HL,FBD_HM,FBD_HR,FBD_MM,FBD_Miko,FBD_Trunk,FBD_VL,FBD_VM,FBD_VR
 SG_ ControlRangingSessionSetup2_D_47 : 392|8@1+ (1.0,0) [0|255] "" FBD_HL,FBD_HM,FBD_HR,FBD_MM,FBD_Miko,FBD_Trunk,FBD_VL,FBD_VM,FBD_VR
 SG_ ControlRangingSessionSetup2_D_48 : 400|8@1+ (1.0,0) [0|255] "" FBD_HL,FBD_HM,FBD_HR,FBD_MM,FBD_Miko,FBD_Trunk,FBD_VL,FBD_VM,FBD_VR
 SG_ ControlRangingSessionSetup2_D_49 : 408|8@1+ (1.0,0) [0|255] "" FBD_HL,FBD_HM,FBD_HR,FBD_MM,FBD_Miko,FBD_Trunk,FBD_VL,FBD_VM,FBD_VR
 SG_ ControlRangingSessionSetup2_D_50 : 416|8@1+ (1.0,0) [0|255] "" FBD_HL,FBD_HM,FBD_HR,FBD_MM,FBD_Miko,FBD_Trunk,FBD_VL,FBD_VM,FBD_VR
 SG_ ControlRangingSessionSetup2_D_51 : 424|8@1+ (1.0,0) [0|255] "" FBD_HL,FBD_HM,FBD_HR,FBD_MM,FBD_Miko,FBD_Trunk,FBD_VL,FBD_VM,FBD_VR
 SG_ ControlRangingSessionSetup2_D_52 : 432|8@1+ (1.0,0) [0|255] "" FBD_HL,FBD_HM,FBD_HR,FBD_MM,FBD_Miko,FBD_Trunk,FBD_VL,FBD_VM,FBD_VR
 SG_ ControlRangingSessionSetup2_D_53 : 440|8@1+ (1.0,0) [0|255] "" FBD_HL,FBD_HM,FBD_HR,FBD_MM,FBD_Miko,FBD_Trunk,FBD_VL,FBD_VM,FBD_VR
 SG_ ControlRangingSessionSetup2_D_54 : 448|8@1+ (1.0,0) [0|255] "" FBD_HL,FBD_HM,FBD_HR,FBD_MM,FBD_Miko,FBD_Trunk,FBD_VL,FBD_VM,FBD_VR
 SG_ ControlRangingSessionSetup2_D_55 : 456|8@1+ (1.0,0) [0|255] "" FBD_HL,FBD_HM,FBD_HR,FBD_MM,FBD_Miko,FBD_Trunk,FBD_VL,FBD_VM,FBD_VR
 SG_ ControlRangingSessionSetup2_D_56 : 464|8@1+ (1.0,0) [0|255] "" FBD_HL,FBD_HM,FBD_HR,FBD_MM,FBD_Miko,FBD_Trunk,FBD_VL,FBD_VM,FBD_VR
 SG_ ControlRangingSessionSetup2_D_57 : 472|8@1+ (1.0,0) [0|255] "" FBD_HL,FBD_HM,FBD_HR,FBD_MM,FBD_Miko,FBD_Trunk,FBD_VL,FBD_VM,FBD_VR
 SG_ ControlRangingSessionSetup2_D_58 : 480|8@1+ (1.0,0) [0|255] "" FBD_HL,FBD_HM,FBD_HR,FBD_MM,FBD_Miko,FBD_Trunk,FBD_VL,FBD_VM,FBD_VR
 SG_ ControlRangingSessionSetup2_D_59 : 488|8@1+ (1.0,0) [0|255] "" FBD_HL,FBD_HM,FBD_HR,FBD_MM,FBD_Miko,FBD_Trunk,FBD_VL,FBD_VM,FBD_VR
 SG_ ControlRangingSessionSetup2_D_60 : 496|8@1+ (1.0,0) [0|255] "" FBD_HL,FBD_HM,FBD_HR,FBD_MM,FBD_Miko,FBD_Trunk,FBD_VL,FBD_VM,FBD_VR
 SG_ ControlRangingSessionSetup2_D_61 : 504|8@1+ (1.0,0) [0|255] "" FBD_HL,FBD_HM,FBD_HR,FBD_MM,FBD_Miko,FBD_Trunk,FBD_VL,FBD_VM,FBD_VR

BO_ 404 ControlRangingSessionSetup3: 64 IPB_App1
 SG_ ControlRangingSessionSetup3_Addr : 0|16@1+ (1,0) [0|0] "" FBD_HL,FBD_HM,FBD_HR,FBD_MM,FBD_Miko,FBD_Trunk,FBD_VL,FBD_VM,FBD_VR
 SG_ ControlRangingSessionSetup3_Sess : 16|8@1+ (1.0,0) [0|252] "" FBD_HL,FBD_HM,FBD_HR,FBD_MM,FBD_Miko,FBD_Trunk,FBD_VL,FBD_VM,FBD_VR
 SG_ ControlRangingSessionSetup3_Data : 24|8@1+ (1.0,0) [0|255] "" FBD_HL,FBD_HM,FBD_HR,FBD_MM,FBD_Miko,FBD_Trunk,FBD_VL,FBD_VM,FBD_VR
 SG_ ControlRangingSessionSetup3_Da_2 : 32|8@1+ (1.0,0) [0|255] "" FBD_HL,FBD_HM,FBD_HR,FBD_MM,FBD_Miko,FBD_Trunk,FBD_VL,FBD_VM,FBD_VR
 SG_ ControlRangingSessionSetup3_Da_3 : 40|8@1+ (1.0,0) [0|255] "" FBD_HL,FBD_HM,FBD_HR,FBD_MM,FBD_Miko,FBD_Trunk,FBD_VL,FBD_VM,FBD_VR
 SG_ ControlRangingSessionSetup3_Da_4 : 48|8@1+ (1.0,0) [0|255] "" FBD_HL,FBD_HM,FBD_HR,FBD_MM,FBD_Miko,FBD_Trunk,FBD_VL,FBD_VM,FBD_VR
 SG_ ControlRangingSessionSetup3_Da_5 : 56|8@1+ (1.0,0) [0|255] "" FBD_HL,FBD_HM,FBD_HR,FBD_MM,FBD_Miko,FBD_Trunk,FBD_VL,FBD_VM,FBD_VR
 SG_ ControlRangingSessionSetup3_Da_6 : 64|8@1+ (1.0,0) [0|255] "" FBD_HL,FBD_HM,FBD_HR,FBD_MM,FBD_Miko,FBD_Trunk,FBD_VL,FBD_VM,FBD_VR
 SG_ ControlRangingSessionSetup3_Da_7 : 72|8@1+ (1.0,0) [0|255] "" FBD_HL,FBD_HM,FBD_HR,FBD_MM,FBD_Miko,FBD_Trunk,FBD_VL,FBD_VM,FBD_VR
 SG_ ControlRangingSessionSetup3_Da_8 : 80|8@1+ (1.0,0) [0|255] "" FBD_HL,FBD_HM,FBD_HR,FBD_MM,FBD_Miko,FBD_Trunk,FBD_VL,FBD_VM,FBD_VR
 SG_ ControlRangingSessionSetup3_Da_9 : 88|8@1+ (1.0,0) [0|255] "" FBD_HL,FBD_HM,FBD_HR,FBD_MM,FBD_Miko,FBD_Trunk,FBD_VL,FBD_VM,FBD_VR
 SG_ ControlRangingSessionSetup3_D_10 : 96|8@1+ (1.0,0) [0|255] "" FBD_HL,FBD_HM,FBD_HR,FBD_MM,FBD_Miko,FBD_Trunk,FBD_VL,FBD_VM,FBD_VR
 SG_ ControlRangingSessionSetup3_D_11 : 104|8@1+ (1.0,0) [0|255] "" FBD_HL,FBD_HM,FBD_HR,FBD_MM,FBD_Miko,FBD_Trunk,FBD_VL,FBD_VM,FBD_VR
 SG_ ControlRangingSessionSetup3_D_12 : 112|8@1+ (1.0,0) [0|255] "" FBD_HL,FBD_HM,FBD_HR,FBD_MM,FBD_Miko,FBD_Trunk,FBD_VL,FBD_VM,FBD_VR
 SG_ ControlRangingSessionSetup3_D_13 : 120|8@1+ (1.0,0) [0|255] "" FBD_HL,FBD_HM,FBD_HR,FBD_MM,FBD_Miko,FBD_Trunk,FBD_VL,FBD_VM,FBD_VR
 SG_ ControlRangingSessionSetup3_D_14 : 128|8@1+ (1.0,0) [0|255] "" FBD_HL,FBD_HM,FBD_HR,FBD_MM,FBD_Miko,FBD_Trunk,FBD_VL,FBD_VM,FBD_VR
 SG_ ControlRangingSessionSetup3_D_15 : 136|8@1+ (1.0,0) [0|255] "" FBD_HL,FBD_HM,FBD_HR,FBD_MM,FBD_Miko,FBD_Trunk,FBD_VL,FBD_VM,FBD_VR
 SG_ ControlRangingSessionSetup3_D_16 : 144|8@1+ (1.0,0) [0|255] "" FBD_HL,FBD_HM,FBD_HR,FBD_MM,FBD_Miko,FBD_Trunk,FBD_VL,FBD_VM,FBD_VR
 SG_ ControlRangingSessionSetup3_D_17 : 152|8@1+ (1.0,0) [0|255] "" FBD_HL,FBD_HM,FBD_HR,FBD_MM,FBD_Miko,FBD_Trunk,FBD_VL,FBD_VM,FBD_VR
 SG_ ControlRangingSessionSetup3_D_18 : 160|8@1+ (1.0,0) [0|255] "" FBD_HL,FBD_HM,FBD_HR,FBD_MM,FBD_Miko,FBD_Trunk,FBD_VL,FBD_VM,FBD_VR
 SG_ ControlRangingSessionSetup3_D_19 : 168|8@1+ (1.0,0) [0|255] "" FBD_HL,FBD_HM,FBD_HR,FBD_MM,FBD_Miko,FBD_Trunk,FBD_VL,FBD_VM,FBD_VR
 SG_ ControlRangingSessionSetup3_D_20 : 176|8@1+ (1.0,0) [0|255] "" FBD_HL,FBD_HM,FBD_HR,FBD_MM,FBD_Miko,FBD_Trunk,FBD_VL,FBD_VM,FBD_VR
 SG_ ControlRangingSessionSetup3_D_21 : 184|8@1+ (1.0,0) [0|255] "" FBD_HL,FBD_HM,FBD_HR,FBD_MM,FBD_Miko,FBD_Trunk,FBD_VL,FBD_VM,FBD_VR
 SG_ ControlRangingSessionSetup3_D_22 : 192|8@1+ (1.0,0) [0|255] "" FBD_HL,FBD_HM,FBD_HR,FBD_MM,FBD_Miko,FBD_Trunk,FBD_VL,FBD_VM,FBD_VR
 SG_ ControlRangingSessionSetup3_D_23 : 200|8@1+ (1.0,0) [0|255] "" FBD_HL,FBD_HM,FBD_HR,FBD_MM,FBD_Miko,FBD_Trunk,FBD_VL,FBD_VM,FBD_VR
 SG_ ControlRangingSessionSetup3_D_24 : 208|8@1+ (1.0,0) [0|255] "" FBD_HL,FBD_HM,FBD_HR,FBD_MM,FBD_Miko,FBD_Trunk,FBD_VL,FBD_VM,FBD_VR
 SG_ ControlRangingSessionSetup3_D_25 : 216|8@1+ (1.0,0) [0|255] "" FBD_HL,FBD_HM,FBD_HR,FBD_MM,FBD_Miko,FBD_Trunk,FBD_VL,FBD_VM,FBD_VR
 SG_ ControlRangingSessionSetup3_D_26 : 224|8@1+ (1.0,0) [0|255] "" FBD_HL,FBD_HM,FBD_HR,FBD_MM,FBD_Miko,FBD_Trunk,FBD_VL,FBD_VM,FBD_VR
 SG_ ControlRangingSessionSetup3_D_27 : 232|8@1+ (1.0,0) [0|255] "" FBD_HL,FBD_HM,FBD_HR,FBD_MM,FBD_Miko,FBD_Trunk,FBD_VL,FBD_VM,FBD_VR
 SG_ ControlRangingSessionSetup3_D_28 : 240|8@1+ (1.0,0) [0|255] "" FBD_HL,FBD_HM,FBD_HR,FBD_MM,FBD_Miko,FBD_Trunk,FBD_VL,FBD_VM,FBD_VR
 SG_ ControlRangingSessionSetup3_D_29 : 248|8@1+ (1.0,0) [0|255] "" FBD_HL,FBD_HM,FBD_HR,FBD_MM,FBD_Miko,FBD_Trunk,FBD_VL,FBD_VM,FBD_VR
 SG_ ControlRangingSessionSetup3_D_30 : 256|8@1+ (1.0,0) [0|255] "" FBD_HL,FBD_HM,FBD_HR,FBD_MM,FBD_Miko,FBD_Trunk,FBD_VL,FBD_VM,FBD_VR
 SG_ ControlRangingSessionSetup3_D_31 : 264|8@1+ (1.0,0) [0|255] "" FBD_HL,FBD_HM,FBD_HR,FBD_MM,FBD_Miko,FBD_Trunk,FBD_VL,FBD_VM,FBD_VR
 SG_ ControlRangingSessionSetup3_D_32 : 272|8@1+ (1.0,0) [0|255] "" FBD_HL,FBD_HM,FBD_HR,FBD_MM,FBD_Miko,FBD_Trunk,FBD_VL,FBD_VM,FBD_VR
 SG_ ControlRangingSessionSetup3_D_33 : 280|8@1+ (1.0,0) [0|255] "" FBD_HL,FBD_HM,FBD_HR,FBD_MM,FBD_Miko,FBD_Trunk,FBD_VL,FBD_VM,FBD_VR
 SG_ ControlRangingSessionSetup3_D_34 : 288|8@1+ (1.0,0) [0|255] "" FBD_HL,FBD_HM,FBD_HR,FBD_MM,FBD_Miko,FBD_Trunk,FBD_VL,FBD_VM,FBD_VR
 SG_ ControlRangingSessionSetup3_D_35 : 296|8@1+ (1.0,0) [0|255] "" FBD_HL,FBD_HM,FBD_HR,FBD_MM,FBD_Miko,FBD_Trunk,FBD_VL,FBD_VM,FBD_VR
 SG_ ControlRangingSessionSetup3_D_36 : 304|8@1+ (1.0,0) [0|255] "" FBD_HL,FBD_HM,FBD_HR,FBD_MM,FBD_Miko,FBD_Trunk,FBD_VL,FBD_VM,FBD_VR
 SG_ ControlRangingSessionSetup3_D_37 : 312|8@1+ (1.0,0) [0|255] "" FBD_HL,FBD_HM,FBD_HR,FBD_MM,FBD_Miko,FBD_Trunk,FBD_VL,FBD_VM,FBD_VR
 SG_ ControlRangingSessionSetup3_D_38 : 320|8@1+ (1.0,0) [0|255] "" FBD_HL,FBD_HM,FBD_HR,FBD_MM,FBD_Miko,FBD_Trunk,FBD_VL,FBD_VM,FBD_VR
 SG_ ControlRangingSessionSetup3_D_39 : 328|8@1+ (1.0,0) [0|255] "" FBD_HL,FBD_HM,FBD_HR,FBD_MM,FBD_Miko,FBD_Trunk,FBD_VL,FBD_VM,FBD_VR
 SG_ ControlRangingSessionSetup3_D_40 : 336|8@1+ (1.0,0) [0|255] "" FBD_HL,FBD_HM,FBD_HR,FBD_MM,FBD_Miko,FBD_Trunk,FBD_VL,FBD_VM,FBD_VR
 SG_ ControlRangingSessionSetup3_D_41 : 344|8@1+ (1.0,0) [0|255] "" FBD_HL,FBD_HM,FBD_HR,FBD_MM,FBD_Miko,FBD_Trunk,FBD_VL,FBD_VM,FBD_VR
 SG_ ControlRangingSessionSetup3_D_42 : 352|8@1+ (1.0,0) [0|255] "" FBD_HL,FBD_HM,FBD_HR,FBD_MM,FBD_Miko,FBD_Trunk,FBD_VL,FBD_VM,FBD_VR
 SG_ ControlRangingSessionSetup3_D_43 : 360|8@1+ (1.0,0) [0|255] "" FBD_HL,FBD_HM,FBD_HR,FBD_MM,FBD_Miko,FBD_Trunk,FBD_VL,FBD_VM,FBD_VR
 SG_ ControlRangingSessionSetup3_D_44 : 368|8@1+ (1.0,0) [0|255] "" FBD_HL,FBD_HM,FBD_HR,FBD_MM,FBD_Miko,FBD_Trunk,FBD_VL,FBD_VM,FBD_VR
 SG_ ControlRangingSessionSetup3_D_45 : 376|8@1+ (1.0,0) [0|255] "" FBD_HL,FBD_HM,FBD_HR,FBD_MM,FBD_Miko,FBD_Trunk,FBD_VL,FBD_VM,FBD_VR
 SG_ ControlRangingSessionSetup3_D_46 : 384|8@1+ (1.0,0) [0|255] "" FBD_HL,FBD_HM,FBD_HR,FBD_MM,FBD_Miko,FBD_Trunk,FBD_VL,FBD_VM,FBD_VR
 SG_ ControlRangingSessionSetup3_D_47 : 392|8@1+ (1.0,0) [0|255] "" FBD_HL,FBD_HM,FBD_HR,FBD_MM,FBD_Miko,FBD_Trunk,FBD_VL,FBD_VM,FBD_VR
 SG_ ControlRangingSessionSetup3_D_48 : 400|8@1+ (1.0,0) [0|255] "" FBD_HL,FBD_HM,FBD_HR,FBD_MM,FBD_Miko,FBD_Trunk,FBD_VL,FBD_VM,FBD_VR
 SG_ ControlRangingSessionSetup3_D_49 : 408|8@1+ (1.0,0) [0|255] "" FBD_HL,FBD_HM,FBD_HR,FBD_MM,FBD_Miko,FBD_Trunk,FBD_VL,FBD_VM,FBD_VR
 SG_ ControlRangingSessionSetup3_D_50 : 416|8@1+ (1.0,0) [0|255] "" FBD_HL,FBD_HM,FBD_HR,FBD_MM,FBD_Miko,FBD_Trunk,FBD_VL,FBD_VM,FBD_VR
 SG_ ControlRangingSessionSetup3_D_51 : 424|8@1+ (1.0,0) [0|255] "" FBD_HL,FBD_HM,FBD_HR,FBD_MM,FBD_Miko,FBD_Trunk,FBD_VL,FBD_VM,FBD_VR
 SG_ ControlRangingSessionSetup3_D_52 : 432|8@1+ (1.0,0) [0|255] "" FBD_HL,FBD_HM,FBD_HR,FBD_MM,FBD_Miko,FBD_Trunk,FBD_VL,FBD_VM,FBD_VR
 SG_ ControlRangingSessionSetup3_D_53 : 440|8@1+ (1.0,0) [0|255] "" FBD_HL,FBD_HM,FBD_HR,FBD_MM,FBD_Miko,FBD_Trunk,FBD_VL,FBD_VM,FBD_VR
 SG_ ControlRangingSessionSetup3_D_54 : 448|8@1+ (1.0,0) [0|255] "" FBD_HL,FBD_HM,FBD_HR,FBD_MM,FBD_Miko,FBD_Trunk,FBD_VL,FBD_VM,FBD_VR
 SG_ ControlRangingSessionSetup3_D_55 : 456|8@1+ (1.0,0) [0|255] "" FBD_HL,FBD_HM,FBD_HR,FBD_MM,FBD_Miko,FBD_Trunk,FBD_VL,FBD_VM,FBD_VR
 SG_ ControlRangingSessionSetup3_D_56 : 464|8@1+ (1.0,0) [0|255] "" FBD_HL,FBD_HM,FBD_HR,FBD_MM,FBD_Miko,FBD_Trunk,FBD_VL,FBD_VM,FBD_VR
 SG_ ControlRangingSessionSetup3_D_57 : 472|8@1+ (1.0,0) [0|255] "" FBD_HL,FBD_HM,FBD_HR,FBD_MM,FBD_Miko,FBD_Trunk,FBD_VL,FBD_VM,FBD_VR
 SG_ ControlRangingSessionSetup3_D_58 : 480|8@1+ (1.0,0) [0|255] "" FBD_HL,FBD_HM,FBD_HR,FBD_MM,FBD_Miko,FBD_Trunk,FBD_VL,FBD_VM,FBD_VR
 SG_ ControlRangingSessionSetup3_D_59 : 488|8@1+ (1.0,0) [0|255] "" FBD_HL,FBD_HM,FBD_HR,FBD_MM,FBD_Miko,FBD_Trunk,FBD_VL,FBD_VM,FBD_VR
 SG_ ControlRangingSessionSetup3_D_60 : 496|8@1+ (1.0,0) [0|255] "" FBD_HL,FBD_HM,FBD_HR,FBD_MM,FBD_Miko,FBD_Trunk,FBD_VL,FBD_VM,FBD_VR
 SG_ ControlRangingSessionSetup3_D_61 : 504|8@1+ (1.0,0) [0|255] "" FBD_HL,FBD_HM,FBD_HR,FBD_MM,FBD_Miko,FBD_Trunk,FBD_VL,FBD_VM,FBD_VR

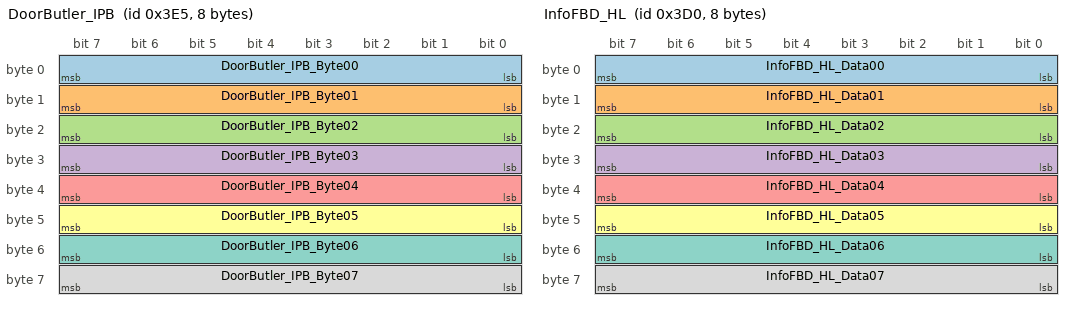
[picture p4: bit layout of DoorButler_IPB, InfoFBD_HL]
BO_ 997 DoorButler_IPB: 8 IPB_App1
 SG_ DoorButler_IPB_Byte00 : 0|8@1+ (1.0,0) [0|252] "" Diagnosetool_CAN_FD_IPB_41
 SG_ DoorButler_IPB_Byte01 : 8|8@1+ (1.0,0) [0|252] "" Diagnosetool_CAN_FD_IPB_41
 SG_ DoorButler_IPB_Byte02 : 16|8@1+ (1.0,0) [0|252] "" Diagnosetool_CAN_FD_IPB_41
 SG_ DoorButler_IPB_Byte03 : 24|8@1+ (1.0,0) [0|252] "" Diagnosetool_CAN_FD_IPB_41
 SG_ DoorButler_IPB_Byte04 : 32|8@1+ (1.0,0) [0|252] "" Diagnosetool_CAN_FD_IPB_41
 SG_ DoorButler_IPB_Byte05 : 40|8@1+ (1.0,0) [0|252] "" Diagnosetool_CAN_FD_IPB_41
 SG_ DoorButler_IPB_Byte06 : 48|8@1+ (1.0,0) [0|252] "" Diagnosetool_CAN_FD_IPB_41
 SG_ DoorButler_IPB_Byte07 : 56|8@1+ (1.0,0) [0|252] "" Diagnosetool_CAN_FD_IPB_41

BO_ 1100 EndOfLineControlFBD: 64 IPB_App1
 SG_ EndOfLineControlFBD_Byte00 : 0|8@1+ (1.0,0) [0|252] "" FBD_VM
 SG_ EndOfLineControlFBD_Byte01 : 8|8@1+ (1.0,0) [0|252] "" FBD_VM
 SG_ EndOfLineControlFBD_Byte02 : 16|8@1+ (1.0,0) [0|252] "" FBD_VM
 SG_ EndOfLineControlFBD_Byte03 : 24|8@1+ (1.0,0) [0|252] "" FBD_VM
 SG_ EndOfLineControlFBD_Byte04 : 32|8@1+ (1.0,0) [0|252] "" FBD_VM
 SG_ EndOfLineControlFBD_Byte05 : 40|8@1+ (1.0,0) [0|252] "" FBD_VM
 SG_ EndOfLineControlFBD_Byte06 : 48|8@1+ (1.0,0) [0|252] "" FBD_VM
 SG_ EndOfLineControlFBD_Byte07 : 56|8@1+ (1.0,0) [0|252] "" FBD_VM
 SG_ EndOfLineControlFBD_Byte08 : 64|8@1+ (1.0,0) [0|252] "" FBD_VM
 SG_ EndOfLineControlFBD_Byte09 : 72|8@1+ (1.0,0) [0|252] "" FBD_VM
 SG_ EndOfLineControlFBD_Byte10 : 80|8@1+ (1.0,0) [0|252] "" FBD_VM
 SG_ EndOfLineControlFBD_Byte11 : 88|8@1+ (1.0,0) [0|252] "" FBD_VM
 SG_ EndOfLineControlFBD_Byte12 : 96|8@1+ (1.0,0) [0|252] "" FBD_VM
 SG_ EndOfLineControlFBD_Byte13 : 104|8@1+ (1.0,0) [0|252] "" FBD_VM
 SG_ EndOfLineControlFBD_Byte14 : 112|8@1+ (1.0,0) [0|252] "" FBD_VM
 SG_ EndOfLineControlFBD_Byte15 : 120|8@1+ (1.0,0) [0|252] "" FBD_VM
 SG_ EndOfLineControlFBD_Byte16 : 128|8@1+ (1.0,0) [0|252] "" FBD_VM
 SG_ EndOfLineControlFBD_Byte17 : 136|8@1+ (1.0,0) [0|252] "" FBD_VM
 SG_ EndOfLineControlFBD_Byte18 : 144|8@1+ (1.0,0) [0|252] "" FBD_VM
 SG_ EndOfLineControlFBD_Byte19 : 152|8@1+ (1.0,0) [0|252] "" FBD_VM
 SG_ EndOfLineControlFBD_Byte20 : 160|8@1+ (1.0,0) [0|252] "" FBD_VM
 SG_ EndOfLineControlFBD_Byte21 : 168|8@1+ (1.0,0) [0|252] "" FBD_VM
 SG_ EndOfLineControlFBD_Byte22 : 176|8@1+ (1.0,0) [0|252] "" FBD_VM
 SG_ EndOfLineControlFBD_Byte23 : 184|8@1+ (1.0,0) [0|252] "" FBD_VM
 SG_ EndOfLineControlFBD_Byte24 : 192|8@1+ (1.0,0) [0|252] "" FBD_VM
 SG_ EndOfLineControlFBD_Byte25 : 200|8@1+ (1.0,0) [0|252] "" FBD_VM
 SG_ EndOfLineControlFBD_Byte26 : 208|8@1+ (1.0,0) [0|252] "" FBD_VM
 SG_ EndOfLineControlFBD_Byte27 : 216|8@1+ (1.0,0) [0|252] "" FBD_VM
 SG_ EndOfLineControlFBD_Byte28 : 224|8@1+ (1.0,0) [0|252] "" FBD_VM
 SG_ EndOfLineControlFBD_Byte29 : 232|8@1+ (1.0,0) [0|252] "" FBD_VM
 SG_ EndOfLineControlFBD_Byte30 : 240|8@1+ (1.0,0) [0|252] "" FBD_VM
 SG_ EndOfLineControlFBD_Byte31 : 248|8@1+ (1.0,0) [0|252] "" FBD_VM
 SG_ EndOfLineControlFBD_Byte32 : 256|8@1+ (1.0,0) [0|252] "" FBD_VM
 SG_ EndOfLineControlFBD_Byte33 : 264|8@1+ (1.0,0) [0|252] "" FBD_VM
 SG_ EndOfLineControlFBD_Byte34 : 272|8@1+ (1.0,0) [0|252] "" FBD_VM
 SG_ EndOfLineControlFBD_Byte35 : 280|8@1+ (1.0,0) [0|252] "" FBD_VM
 SG_ EndOfLineControlFBD_Byte36 : 288|8@1+ (1.0,0) [0|252] "" FBD_VM
 SG_ EndOfLineControlFBD_Byte37 : 296|8@1+ (1.0,0) [0|252] "" FBD_VM
 SG_ EndOfLineControlFBD_Byte38 : 304|8@1+ (1.0,0) [0|252] "" FBD_VM
 SG_ EndOfLineControlFBD_Byte39 : 312|8@1+ (1.0,0) [0|252] "" FBD_VM
 SG_ EndOfLineControlFBD_Byte40 : 320|8@1+ (1.0,0) [0|252] "" FBD_VM
 SG_ EndOfLineControlFBD_Byte41 : 328|8@1+ (1.0,0) [0|252] "" FBD_VM
 SG_ EndOfLineControlFBD_Byte42 : 336|8@1+ (1.0,0) [0|252] "" FBD_VM
 SG_ EndOfLineControlFBD_Byte43 : 344|8@1+ (1.0,0) [0|252] "" FBD_VM
 SG_ EndOfLineControlFBD_Byte44 : 352|8@1+ (1.0,0) [0|252] "" FBD_VM
 SG_ EndOfLineControlFBD_Byte45 : 360|8@1+ (1.0,0) [0|252] "" FBD_VM
 SG_ EndOfLineControlFBD_Byte46 : 368|8@1+ (1.0,0) [0|252] "" FBD_VM
 SG_ EndOfLineControlFBD_Byte47 : 376|8@1+ (1.0,0) [0|252] "" FBD_VM
 SG_ EndOfLineControlFBD_Byte48 : 384|8@1+ (1.0,0) [0|252] "" FBD_VM
 SG_ EndOfLineControlFBD_Byte49 : 392|8@1+ (1.0,0) [0|252] "" FBD_VM
 SG_ EndOfLineControlFBD_Byte50 : 400|8@1+ (1.0,0) [0|252] "" FBD_VM
 SG_ EndOfLineControlFBD_Byte51 : 408|8@1+ (1.0,0) [0|252] "" FBD_VM
 SG_ EndOfLineControlFBD_Byte52 : 416|8@1+ (1.0,0) [0|252] "" FBD_VM
 SG_ EndOfLineControlFBD_Byte53 : 424|8@1+ (1.0,0) [0|252] "" FBD_VM
 SG_ EndOfLineControlFBD_Byte54 : 432|8@1+ (1.0,0) [0|252] "" FBD_VM
 SG_ EndOfLineControlFBD_Byte55 : 440|8@1+ (1.0,0) [0|252] "" FBD_VM
 SG_ EndOfLineControlFBD_Byte56 : 448|8@1+ (1.0,0) [0|252] "" FBD_VM
 SG_ EndOfLineControlFBD_Byte57 : 456|8@1+ (1.0,0) [0|252] "" FBD_VM
 SG_ EndOfLineControlFBD_Byte58 : 464|8@1+ (1.0,0) [0|252] "" FBD_VM
 SG_ EndOfLineControlFBD_Byte59 : 472|8@1+ (1.0,0) [0|252] "" FBD_VM
 SG_ EndOfLineControlFBD_Byte60 : 480|8@1+ (1.0,0) [0|252] "" FBD_VM
 SG_ EndOfLineControlFBD_Byte61 : 488|8@1+ (1.0,0) [0|252] "" FBD_VM
 SG_ EndOfLineControlFBD_Byte62 : 496|8@1+ (1.0,0) [0|252] "" FBD_VM
 SG_ EndOfLineControlFBD_Byte63 : 504|8@1+ (1.0,0) [0|252] "" FBD_VM

BO_ 1101 EndOfLineStatusFBD: 64 FBD_VM
 SG_ EndOfLineStatusFBD_Byte00 : 0|8@1+ (1.0,0) [0|252] "" IPB_App1
 SG_ EndOfLineStatusFBD_Byte01 : 8|8@1+ (1.0,0) [0|252] "" IPB_App1
 SG_ EndOfLineStatusFBD_Byte02 : 16|8@1+ (1.0,0) [0|252] "" IPB_App1
 SG_ EndOfLineStatusFBD_Byte03 : 24|8@1+ (1.0,0) [0|252] "" IPB_App1
 SG_ EndOfLineStatusFBD_Byte04 : 32|8@1+ (1.0,0) [0|252] "" IPB_App1
 SG_ EndOfLineStatusFBD_Byte05 : 40|8@1+ (1.0,0) [0|252] "" IPB_App1
 SG_ EndOfLineStatusFBD_Byte06 : 48|8@1+ (1.0,0) [0|252] "" IPB_App1
 SG_ EndOfLineStatusFBD_Byte07 : 56|8@1+ (1.0,0) [0|252] "" IPB_App1
 SG_ EndOfLineStatusFBD_Byte08 : 64|8@1+ (1.0,0) [0|252] "" IPB_App1
 SG_ EndOfLineStatusFBD_Byte09 : 72|8@1+ (1.0,0) [0|252] "" IPB_App1
 SG_ EndOfLineStatusFBD_Byte10 : 80|8@1+ (1.0,0) [0|252] "" IPB_App1
 SG_ EndOfLineStatusFBD_Byte11 : 88|8@1+ (1.0,0) [0|252] "" IPB_App1
 SG_ EndOfLineStatusFBD_Byte12 : 96|8@1+ (1.0,0) [0|252] "" IPB_App1
 SG_ EndOfLineStatusFBD_Byte13 : 104|8@1+ (1.0,0) [0|252] "" IPB_App1
 SG_ EndOfLineStatusFBD_Byte14 : 112|8@1+ (1.0,0) [0|252] "" IPB_App1
 SG_ EndOfLineStatusFBD_Byte15 : 120|8@1+ (1.0,0) [0|252] "" IPB_App1
 SG_ EndOfLineStatusFBD_Byte16 : 128|8@1+ (1.0,0) [0|252] "" IPB_App1
 SG_ EndOfLineStatusFBD_Byte17 : 136|8@1+ (1.0,0) [0|252] "" IPB_App1
 SG_ EndOfLineStatusFBD_Byte18 : 144|8@1+ (1.0,0) [0|252] "" IPB_App1
 SG_ EndOfLineStatusFBD_Byte19 : 152|8@1+ (1.0,0) [0|252] "" IPB_App1
 SG_ EndOfLineStatusFBD_Byte20 : 160|8@1+ (1.0,0) [0|252] "" IPB_App1
 SG_ EndOfLineStatusFBD_Byte21 : 168|8@1+ (1.0,0) [0|252] "" IPB_App1
 SG_ EndOfLineStatusFBD_Byte22 : 176|8@1+ (1.0,0) [0|252] "" IPB_App1
 SG_ EndOfLineStatusFBD_Byte23 : 184|8@1+ (1.0,0) [0|252] "" IPB_App1
 SG_ EndOfLineStatusFBD_Byte24 : 192|8@1+ (1.0,0) [0|252] "" IPB_App1
 SG_ EndOfLineStatusFBD_Byte25 : 200|8@1+ (1.0,0) [0|252] "" IPB_App1
 SG_ EndOfLineStatusFBD_Byte26 : 208|8@1+ (1.0,0) [0|252] "" IPB_App1
 SG_ EndOfLineStatusFBD_Byte27 : 216|8@1+ (1.0,0) [0|252] "" IPB_App1
 SG_ EndOfLineStatusFBD_Byte28 : 224|8@1+ (1.0,0) [0|252] "" IPB_App1
 SG_ EndOfLineStatusFBD_Byte29 : 232|8@1+ (1.0,0) [0|252] "" IPB_App1
 SG_ EndOfLineStatusFBD_Byte30 : 240|8@1+ (1.0,0) [0|252] "" IPB_App1
 SG_ EndOfLineStatusFBD_Byte31 : 248|8@1+ (1.0,0) [0|252] "" IPB_App1
 SG_ EndOfLineStatusFBD_Byte32 : 256|8@1+ (1.0,0) [0|252] "" IPB_App1
 SG_ EndOfLineStatusFBD_Byte33 : 264|8@1+ (1.0,0) [0|252] "" IPB_App1
 SG_ EndOfLineStatusFBD_Byte34 : 272|8@1+ (1.0,0) [0|252] "" IPB_App1
 SG_ EndOfLineStatusFBD_Byte35 : 280|8@1+ (1.0,0) [0|252] "" IPB_App1
 SG_ EndOfLineStatusFBD_Byte36 : 288|8@1+ (1.0,0) [0|252] "" IPB_App1
 SG_ EndOfLineStatusFBD_Byte37 : 296|8@1+ (1.0,0) [0|252] "" IPB_App1
 SG_ EndOfLineStatusFBD_Byte38 : 304|8@1+ (1.0,0) [0|252] "" IPB_App1
 SG_ EndOfLineStatusFBD_Byte39 : 312|8@1+ (1.0,0) [0|252] "" IPB_App1
 SG_ EndOfLineStatusFBD_Byte40 : 320|8@1+ (1.0,0) [0|252] "" IPB_App1
 SG_ EndOfLineStatusFBD_Byte41 : 328|8@1+ (1.0,0) [0|252] "" IPB_App1
 SG_ EndOfLineStatusFBD_Byte42 : 336|8@1+ (1.0,0) [0|252] "" IPB_App1
 SG_ EndOfLineStatusFBD_Byte43 : 344|8@1+ (1.0,0) [0|252] "" IPB_App1
 SG_ EndOfLineStatusFBD_Byte44 : 352|8@1+ (1.0,0) [0|252] "" IPB_App1
 SG_ EndOfLineStatusFBD_Byte45 : 360|8@1+ (1.0,0) [0|252] "" IPB_App1
 SG_ EndOfLineStatusFBD_Byte46 : 368|8@1+ (1.0,0) [0|252] "" IPB_App1
 SG_ EndOfLineStatusFBD_Byte47 : 376|8@1+ (1.0,0) [0|252] "" IPB_App1
 SG_ EndOfLineStatusFBD_Byte48 : 384|8@1+ (1.0,0) [0|252] "" IPB_App1
 SG_ EndOfLineStatusFBD_Byte49 : 392|8@1+ (1.0,0) [0|252] "" IPB_App1
 SG_ EndOfLineStatusFBD_Byte50 : 400|8@1+ (1.0,0) [0|252] "" IPB_App1
 SG_ EndOfLineStatusFBD_Byte51 : 408|8@1+ (1.0,0) [0|252] "" IPB_App1
 SG_ EndOfLineStatusFBD_Byte52 : 416|8@1+ (1.0,0) [0|252] "" IPB_App1
 SG_ EndOfLineStatusFBD_Byte53 : 424|8@1+ (1.0,0) [0|252] "" IPB_App1
 SG_ EndOfLineStatusFBD_Byte54 : 432|8@1+ (1.0,0) [0|252] "" IPB_App1
 SG_ EndOfLineStatusFBD_Byte55 : 440|8@1+ (1.0,0) [0|252] "" IPB_App1
 SG_ EndOfLineStatusFBD_Byte56 : 448|8@1+ (1.0,0) [0|252] "" IPB_App1
 SG_ EndOfLineStatusFBD_Byte57 : 456|8@1+ (1.0,0) [0|252] "" IPB_App1
 SG_ EndOfLineStatusFBD_Byte58 : 464|8@1+ (1.0,0) [0|252] "" IPB_App1
 SG_ EndOfLineStatusFBD_Byte59 : 472|8@1+ (1.0,0) [0|252] "" IPB_App1
 SG_ EndOfLineStatusFBD_Byte60 : 480|8@1+ (1.0,0) [0|252] "" IPB_App1
 SG_ EndOfLineStatusFBD_Byte61 : 488|8@1+ (1.0,0) [0|252] "" IPB_App1
 SG_ EndOfLineStatusFBD_Byte62 : 496|8@1+ (1.0,0) [0|252] "" IPB_App1
 SG_ EndOfLineStatusFBD_Byte63 : 504|8@1+ (1.0,0) [0|252] "" IPB_App1

BO_ 976 InfoFBD_HL: 8 FBD_HL
 SG_ InfoFBD_HL_Data00 : 0|8@1+ (1.0,0) [0|252] "" IPB_App1
 SG_ InfoFBD_HL_Data01 : 8|8@1+ (1.0,0) [0|252] "" IPB_App1
 SG_ InfoFBD_HL_Data02 : 16|8@1+ (1.0,0) [0|252] "" IPB_App1
 SG_ InfoFBD_HL_Data03 : 24|8@1+ (1.0,0) [0|252] "" IPB_App1
 SG_ InfoFBD_HL_Data04 : 32|8@1+ (1.0,0) [0|252] "" IPB_App1
 SG_ InfoFBD_HL_Data05 : 40|8@1+ (1.0,0) [0|252] "" IPB_App1
 SG_ InfoFBD_HL_Data06 : 48|8@1+ (1.0,0) [0|252] "" IPB_App1
 SG_ InfoFBD_HL_Data07 : 56|8@1+ (1.0,0) [0|252] "" IPB_App1

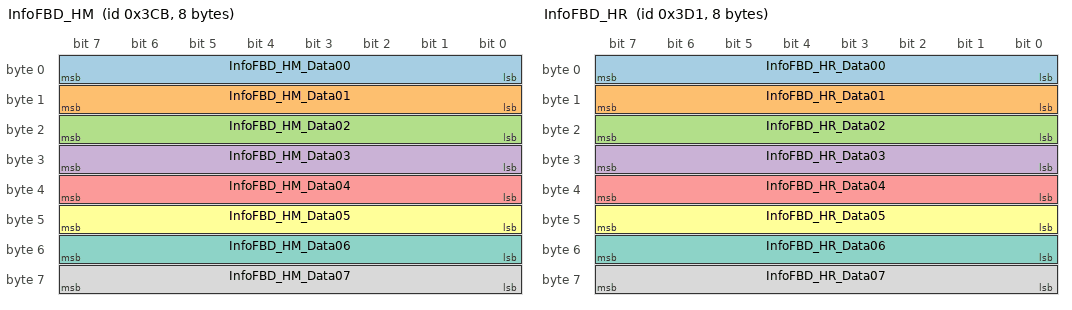
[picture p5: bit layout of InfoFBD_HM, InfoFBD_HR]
BO_ 971 InfoFBD_HM: 8 FBD_HM
 SG_ InfoFBD_HM_Data00 : 0|8@1+ (1.0,0) [0|252] "" IPB_App1
 SG_ InfoFBD_HM_Data01 : 8|8@1+ (1.0,0) [0|252] "" IPB_App1
 SG_ InfoFBD_HM_Data02 : 16|8@1+ (1.0,0) [0|252] "" IPB_App1
 SG_ InfoFBD_HM_Data03 : 24|8@1+ (1.0,0) [0|252] "" IPB_App1
 SG_ InfoFBD_HM_Data04 : 32|8@1+ (1.0,0) [0|252] "" IPB_App1
 SG_ InfoFBD_HM_Data05 : 40|8@1+ (1.0,0) [0|252] "" IPB_App1
 SG_ InfoFBD_HM_Data06 : 48|8@1+ (1.0,0) [0|252] "" IPB_App1
 SG_ InfoFBD_HM_Data07 : 56|8@1+ (1.0,0) [0|252] "" IPB_App1

BO_ 977 InfoFBD_HR: 8 FBD_HR
 SG_ InfoFBD_HR_Data00 : 0|8@1+ (1.0,0) [0|252] "" IPB_App1
 SG_ InfoFBD_HR_Data01 : 8|8@1+ (1.0,0) [0|252] "" IPB_App1
 SG_ InfoFBD_HR_Data02 : 16|8@1+ (1.0,0) [0|252] "" IPB_App1
 SG_ InfoFBD_HR_Data03 : 24|8@1+ (1.0,0) [0|252] "" IPB_App1
 SG_ InfoFBD_HR_Data04 : 32|8@1+ (1.0,0) [0|252] "" IPB_App1
 SG_ InfoFBD_HR_Data05 : 40|8@1+ (1.0,0) [0|252] "" IPB_App1
 SG_ InfoFBD_HR_Data06 : 48|8@1+ (1.0,0) [0|252] "" IPB_App1
 SG_ InfoFBD_HR_Data07 : 56|8@1+ (1.0,0) [0|252] "" IPB_App1

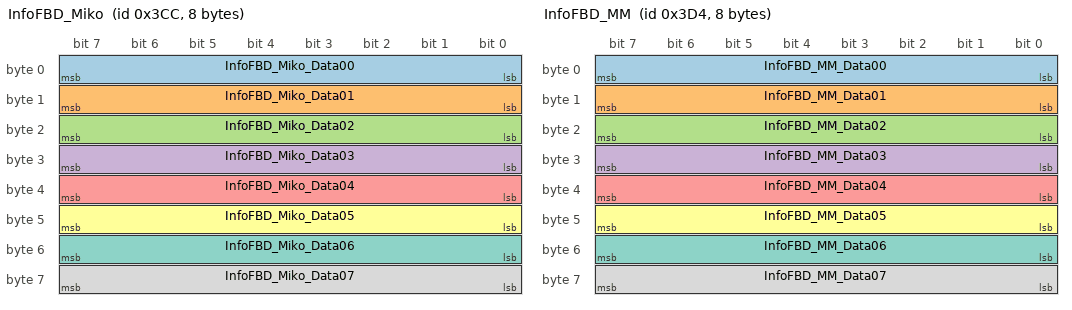
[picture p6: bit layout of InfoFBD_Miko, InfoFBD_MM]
BO_ 972 InfoFBD_Miko: 8 FBD_Miko
 SG_ InfoFBD_Miko_Data00 : 0|8@1+ (1.0,0) [0|252] "" IPB_App1
 SG_ InfoFBD_Miko_Data01 : 8|8@1+ (1.0,0) [0|252] "" IPB_App1
 SG_ InfoFBD_Miko_Data02 : 16|8@1+ (1.0,0) [0|252] "" IPB_App1
 SG_ InfoFBD_Miko_Data03 : 24|8@1+ (1.0,0) [0|252] "" IPB_App1
 SG_ InfoFBD_Miko_Data04 : 32|8@1+ (1.0,0) [0|252] "" IPB_App1
 SG_ InfoFBD_Miko_Data05 : 40|8@1+ (1.0,0) [0|252] "" IPB_App1
 SG_ InfoFBD_Miko_Data06 : 48|8@1+ (1.0,0) [0|252] "" IPB_App1
 SG_ InfoFBD_Miko_Data07 : 56|8@1+ (1.0,0) [0|252] "" IPB_App1

BO_ 980 InfoFBD_MM: 8 FBD_MM
 SG_ InfoFBD_MM_Data00 : 0|8@1+ (1.0,0) [0|252] "" IPB_App1
 SG_ InfoFBD_MM_Data01 : 8|8@1+ (1.0,0) [0|252] "" IPB_App1
 SG_ InfoFBD_MM_Data02 : 16|8@1+ (1.0,0) [0|252] "" IPB_App1
 SG_ InfoFBD_MM_Data03 : 24|8@1+ (1.0,0) [0|252] "" IPB_App1
 SG_ InfoFBD_MM_Data04 : 32|8@1+ (1.0,0) [0|252] "" IPB_App1
 SG_ InfoFBD_MM_Data05 : 40|8@1+ (1.0,0) [0|252] "" IPB_App1
 SG_ InfoFBD_MM_Data06 : 48|8@1+ (1.0,0) [0|252] "" IPB_App1
 SG_ InfoFBD_MM_Data07 : 56|8@1+ (1.0,0) [0|252] "" IPB_App1

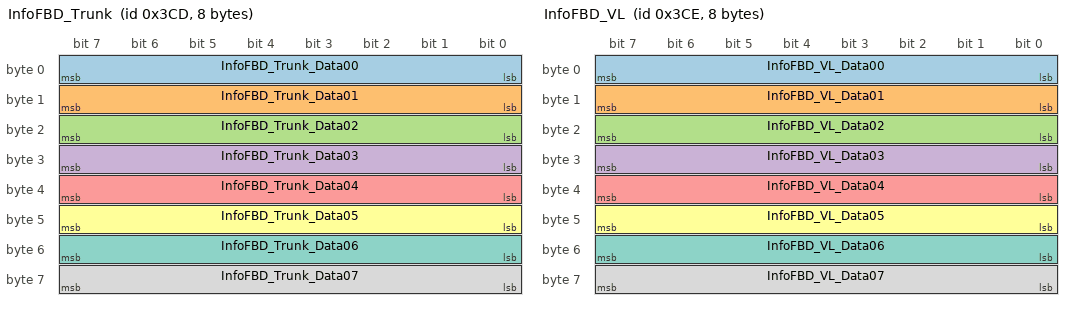
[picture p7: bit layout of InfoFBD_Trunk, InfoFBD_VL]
BO_ 973 InfoFBD_Trunk: 8 FBD_Trunk
 SG_ InfoFBD_Trunk_Data00 : 0|8@1+ (1.0,0) [0|252] "" IPB_App1
 SG_ InfoFBD_Trunk_Data01 : 8|8@1+ (1.0,0) [0|252] "" IPB_App1
 SG_ InfoFBD_Trunk_Data02 : 16|8@1+ (1.0,0) [0|252] "" IPB_App1
 SG_ InfoFBD_Trunk_Data03 : 24|8@1+ (1.0,0) [0|252] "" IPB_App1
 SG_ InfoFBD_Trunk_Data04 : 32|8@1+ (1.0,0) [0|252] "" IPB_App1
 SG_ InfoFBD_Trunk_Data05 : 40|8@1+ (1.0,0) [0|252] "" IPB_App1
 SG_ InfoFBD_Trunk_Data06 : 48|8@1+ (1.0,0) [0|252] "" IPB_App1
 SG_ InfoFBD_Trunk_Data07 : 56|8@1+ (1.0,0) [0|252] "" IPB_App1

BO_ 974 InfoFBD_VL: 8 FBD_VL
 SG_ InfoFBD_VL_Data00 : 0|8@1+ (1.0,0) [0|252] "" IPB_App1
 SG_ InfoFBD_VL_Data01 : 8|8@1+ (1.0,0) [0|252] "" IPB_App1
 SG_ InfoFBD_VL_Data02 : 16|8@1+ (1.0,0) [0|252] "" IPB_App1
 SG_ InfoFBD_VL_Data03 : 24|8@1+ (1.0,0) [0|252] "" IPB_App1
 SG_ InfoFBD_VL_Data04 : 32|8@1+ (1.0,0) [0|252] "" IPB_App1
 SG_ InfoFBD_VL_Data05 : 40|8@1+ (1.0,0) [0|252] "" IPB_App1
 SG_ InfoFBD_VL_Data06 : 48|8@1+ (1.0,0) [0|252] "" IPB_App1
 SG_ InfoFBD_VL_Data07 : 56|8@1+ (1.0,0) [0|252] "" IPB_App1

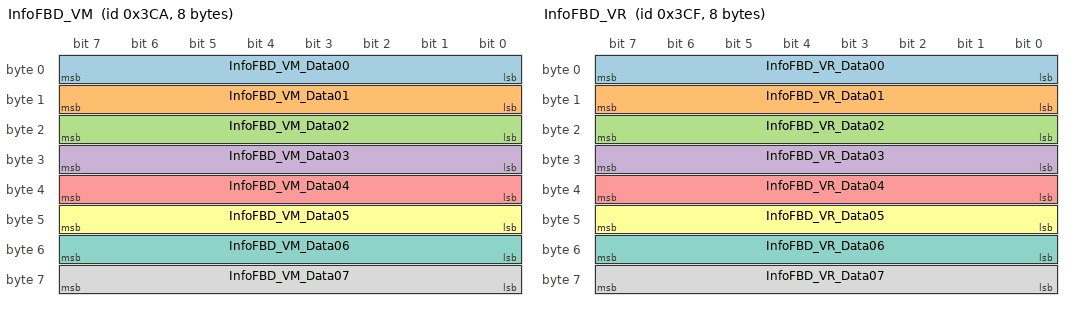
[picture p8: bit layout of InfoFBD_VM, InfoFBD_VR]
BO_ 970 InfoFBD_VM: 8 FBD_VM
 SG_ InfoFBD_VM_Data00 : 0|8@1+ (1.0,0) [0|252] "" IPB_App1
 SG_ InfoFBD_VM_Data01 : 8|8@1+ (1.0,0) [0|252] "" IPB_App1
 SG_ InfoFBD_VM_Data02 : 16|8@1+ (1.0,0) [0|252] "" IPB_App1
 SG_ InfoFBD_VM_Data03 : 24|8@1+ (1.0,0) [0|252] "" IPB_App1
 SG_ InfoFBD_VM_Data04 : 32|8@1+ (1.0,0) [0|252] "" IPB_App1
 SG_ InfoFBD_VM_Data05 : 40|8@1+ (1.0,0) [0|252] "" IPB_App1
 SG_ InfoFBD_VM_Data06 : 48|8@1+ (1.0,0) [0|252] "" IPB_App1
 SG_ InfoFBD_VM_Data07 : 56|8@1+ (1.0,0) [0|252] "" IPB_App1

BO_ 975 InfoFBD_VR: 8 FBD_VR
 SG_ InfoFBD_VR_Data00 : 0|8@1+ (1.0,0) [0|252] "" IPB_App1
 SG_ InfoFBD_VR_Data01 : 8|8@1+ (1.0,0) [0|252] "" IPB_App1
 SG_ InfoFBD_VR_Data02 : 16|8@1+ (1.0,0) [0|252] "" IPB_App1
 SG_ InfoFBD_VR_Data03 : 24|8@1+ (1.0,0) [0|252] "" IPB_App1
 SG_ InfoFBD_VR_Data04 : 32|8@1+ (1.0,0) [0|252] "" IPB_App1
 SG_ InfoFBD_VR_Data05 : 40|8@1+ (1.0,0) [0|252] "" IPB_App1
 SG_ InfoFBD_VR_Data06 : 48|8@1+ (1.0,0) [0|252] "" IPB_App1
 SG_ InfoFBD_VR_Data07 : 56|8@1+ (1.0,0) [0|252] "" IPB_App1

BO_ 556 LocalizationInitFBD_HL: 48 FBD_HL
 SG_ LocalizationInitFBD_HL_IRKListIn : 0|8@1+ (1.0,0) [0|252] "" IPB_App1
 SG_ LocalizationInitFBD_HL_ZoneEntry : 8|8@1+ (1.0,0) [0|252] "" IPB_App1
 SG_ LocalizationInitFBD_HL_RangingBl : 16|16@1+ (1.0,0) [0|65532] "" IPB_App1
 SG_ LocalizationInitFBD_HL_TimeOfFli : 32|16@1+ (15.65,0) [0|1000000] "ps" IPB_App1
 SG_ LocalizationInitFBD_HL_RSSI_0 : 48|8@1+ (1.0,-90) [-90|90] "°" IPB_App1
 SG_ LocalizationInitFBD_HL_Ranging_2 : 56|16@1+ (1.0,0) [0|65532] "" IPB_App1
 SG_ LocalizationInitFBD_HL_TimeOfF_2 : 72|16@1+ (15.65,0) [0|1000000] "ps" IPB_App1
 SG_ LocalizationInitFBD_HL_RSSI_1 : 88|8@1+ (1.0,-90) [-90|90] "°" IPB_App1
 SG_ LocalizationInitFBD_HL_Ranging_3 : 96|16@1+ (1.0,0) [0|65532] "" IPB_App1
 SG_ LocalizationInitFBD_HL_TimeOfF_3 : 112|16@1+ (15.65,0) [0|1000000] "ps" IPB_App1
 SG_ LocalizationInitFBD_HL_RSSI_2 : 128|8@1+ (1.0,-90) [-90|90] "°" IPB_App1
 SG_ LocalizationInitFBD_HL_Ranging_4 : 136|16@1+ (1.0,0) [0|65532] "" IPB_App1
 SG_ LocalizationInitFBD_HL_TimeOfF_4 : 152|16@1+ (15.65,0) [0|1000000] "ps" IPB_App1
 SG_ LocalizationInitFBD_HL_RSSI_3 : 168|8@1+ (1.0,-90) [-90|90] "°" IPB_App1
 SG_ LocalizationInitFBD_HL_Ranging_5 : 176|16@1+ (1.0,0) [0|65532] "" IPB_App1
 SG_ LocalizationInitFBD_HL_TimeOfF_5 : 192|16@1+ (15.65,0) [0|1000000] "ps" IPB_App1
 SG_ LocalizationInitFBD_HL_RSSI_4 : 208|8@1+ (1.0,-90) [-90|90] "°" IPB_App1
 SG_ LocalizationInitFBD_HL_Sign_00 : 216|8@1+ (1.0,0) [0|255] "" IPB_App1
 SG_ LocalizationInitFBD_HL_Sign_01 : 224|8@1+ (1.0,0) [0|255] "" IPB_App1
 SG_ LocalizationInitFBD_HL_Sign_02 : 232|8@1+ (1.0,0) [0|255] "" IPB_App1
 SG_ LocalizationInitFBD_HL_Sign_03 : 240|8@1+ (1.0,0) [0|255] "" IPB_App1
 SG_ LocalizationInitFBD_HL_Sign_04 : 248|8@1+ (1.0,0) [0|255] "" IPB_App1
 SG_ LocalizationInitFBD_HL_Sign_05 : 256|8@1+ (1.0,0) [0|255] "" IPB_App1
 SG_ LocalizationInitFBD_HL_Sign_06 : 264|8@1+ (1.0,0) [0|255] "" IPB_App1
 SG_ LocalizationInitFBD_HL_Sign_07 : 272|8@1+ (1.0,0) [0|255] "" IPB_App1
 SG_ LocalizationInitFBD_HL_Sign_08 : 280|8@1+ (1.0,0) [0|255] "" IPB_App1
 SG_ LocalizationInitFBD_HL_Sign_09 : 288|8@1+ (1.0,0) [0|255] "" IPB_App1
 SG_ LocalizationInitFBD_HL_Sign_10 : 296|8@1+ (1.0,0) [0|255] "" IPB_App1
 SG_ LocalizationInitFBD_HL_Sign_11 : 304|8@1+ (1.0,0) [0|255] "" IPB_App1
 SG_ LocalizationInitFBD_HL_Sign_12 : 312|8@1+ (1.0,0) [0|255] "" IPB_App1
 SG_ LocalizationInitFBD_HL_Sign_13 : 320|8@1+ (1.0,0) [0|255] "" IPB_App1
 SG_ LocalizationInitFBD_HL_Sign_14 : 328|8@1+ (1.0,0) [0|255] "" IPB_App1
 SG_ LocalizationInitFBD_HL_Sign_15 : 336|8@1+ (1.0,0) [0|255] "" IPB_App1
 SG_ LocalizationInitFBD_HL_RangingRo : 344|8@1+ (1.0,0) [0|255] "" IPB_App1
 SG_ LocalizationInitFBD_HL_Ranging_6 : 352|8@1+ (1.0,0) [0|255] "" IPB_App1
 SG_ LocalizationInitFBD_HL_Ranging_7 : 360|8@1+ (1.0,0) [0|255] "" IPB_App1
 SG_ LocalizationInitFBD_HL_Ranging_8 : 368|8@1+ (1.0,0) [0|255] "" IPB_App1
 SG_ LocalizationInitFBD_HL_Ranging_9 : 376|8@1+ (1.0,0) [0|255] "" IPB_App1

BO_ 551 LocalizationInitFBD_HM: 48 FBD_HM
 SG_ LocalizationInitFBD_HM_IRKListIn : 0|8@1+ (1.0,0) [0|252] "" IPB_App1
 SG_ LocalizationInitFBD_HM_ZoneEntry : 8|8@1+ (1.0,0) [0|252] "" IPB_App1
 SG_ LocalizationInitFBD_HM_RangingBl : 16|16@1+ (1.0,0) [0|65532] "" IPB_App1
 SG_ LocalizationInitFBD_HM_TimeOfFli : 32|16@1+ (15.65,0) [0|1000000] "ps" IPB_App1
 SG_ LocalizationInitFBD_HM_RSSI_0 : 48|8@1+ (1.0,-90) [-90|90] "°" IPB_App1
 SG_ LocalizationInitFBD_HM_Ranging_2 : 56|16@1+ (1.0,0) [0|65532] "" IPB_App1
 SG_ LocalizationInitFBD_HM_TimeOfF_2 : 72|16@1+ (15.65,0) [0|1000000] "ps" IPB_App1
 SG_ LocalizationInitFBD_HM_RSSI_1 : 88|8@1+ (1.0,-90) [-90|90] "°" IPB_App1
 SG_ LocalizationInitFBD_HM_Ranging_3 : 96|16@1+ (1.0,0) [0|65532] "" IPB_App1
 SG_ LocalizationInitFBD_HM_TimeOfF_3 : 112|16@1+ (15.65,0) [0|1000000] "ps" IPB_App1
 SG_ LocalizationInitFBD_HM_RSSI_2 : 128|8@1+ (1.0,-90) [-90|90] "°" IPB_App1
 SG_ LocalizationInitFBD_HM_Ranging_4 : 136|16@1+ (1.0,0) [0|65532] "" IPB_App1
 SG_ LocalizationInitFBD_HM_TimeOfF_4 : 152|16@1+ (15.65,0) [0|1000000] "ps" IPB_App1
 SG_ LocalizationInitFBD_HM_RSSI_3 : 168|8@1+ (1.0,-90) [-90|90] "°" IPB_App1
 SG_ LocalizationInitFBD_HM_Ranging_5 : 176|16@1+ (1.0,0) [0|65532] "" IPB_App1
 SG_ LocalizationInitFBD_HM_TimeOfF_5 : 192|16@1+ (15.65,0) [0|1000000] "ps" IPB_App1
 SG_ LocalizationInitFBD_HM_RSSI_4 : 208|8@1+ (1.0,-90) [-90|90] "°" IPB_App1
 SG_ LocalizationInitFBD_HM_Sign_00 : 216|8@1+ (1.0,0) [0|255] "" IPB_App1
 SG_ LocalizationInitFBD_HM_Sign_01 : 224|8@1+ (1.0,0) [0|255] "" IPB_App1
 SG_ LocalizationInitFBD_HM_Sign_02 : 232|8@1+ (1.0,0) [0|255] "" IPB_App1
 SG_ LocalizationInitFBD_HM_Sign_03 : 240|8@1+ (1.0,0) [0|255] "" IPB_App1
 SG_ LocalizationInitFBD_HM_Sign_04 : 248|8@1+ (1.0,0) [0|255] "" IPB_App1
 SG_ LocalizationInitFBD_HM_Sign_05 : 256|8@1+ (1.0,0) [0|255] "" IPB_App1
 SG_ LocalizationInitFBD_HM_Sign_06 : 264|8@1+ (1.0,0) [0|255] "" IPB_App1
 SG_ LocalizationInitFBD_HM_Sign_07 : 272|8@1+ (1.0,0) [0|255] "" IPB_App1
 SG_ LocalizationInitFBD_HM_Sign_08 : 280|8@1+ (1.0,0) [0|255] "" IPB_App1
 SG_ LocalizationInitFBD_HM_Sign_09 : 288|8@1+ (1.0,0) [0|255] "" IPB_App1
 SG_ LocalizationInitFBD_HM_Sign_10 : 296|8@1+ (1.0,0) [0|255] "" IPB_App1
 SG_ LocalizationInitFBD_HM_Sign_11 : 304|8@1+ (1.0,0) [0|255] "" IPB_App1
 SG_ LocalizationInitFBD_HM_Sign_12 : 312|8@1+ (1.0,0) [0|255] "" IPB_App1
 SG_ LocalizationInitFBD_HM_Sign_13 : 320|8@1+ (1.0,0) [0|255] "" IPB_App1
 SG_ LocalizationInitFBD_HM_Sign_14 : 328|8@1+ (1.0,0) [0|255] "" IPB_App1
 SG_ LocalizationInitFBD_HM_Sign_15 : 336|8@1+ (1.0,0) [0|255] "" IPB_App1
 SG_ LocalizationInitFBD_HM_RangingRo : 344|8@1+ (1.0,0) [0|255] "" IPB_App1
 SG_ LocalizationInitFBD_HM_Ranging_6 : 352|8@1+ (1.0,0) [0|255] "" IPB_App1
 SG_ LocalizationInitFBD_HM_Ranging_7 : 360|8@1+ (1.0,0) [0|255] "" IPB_App1
 SG_ LocalizationInitFBD_HM_Ranging_8 : 368|8@1+ (1.0,0) [0|255] "" IPB_App1
 SG_ LocalizationInitFBD_HM_Ranging_9 : 376|8@1+ (1.0,0) [0|255] "" IPB_App1

BO_ 557 LocalizationInitFBD_HR: 48 FBD_HR
 SG_ LocalizationInitFBD_HR_IRKListIn : 0|8@1+ (1.0,0) [0|252] "" IPB_App1
 SG_ LocalizationInitFBD_HR_ZoneEntry : 8|8@1+ (1.0,0) [0|252] "" IPB_App1
 SG_ LocalizationInitFBD_HR_RangingBl : 16|16@1+ (1.0,0) [0|65532] "" IPB_App1
 SG_ LocalizationInitFBD_HR_TimeOfFli : 32|16@1+ (15.65,0) [0|1000000] "ps" IPB_App1
 SG_ LocalizationInitFBD_HR_RSSI_0 : 48|8@1+ (1.0,-90) [-90|90] "°" IPB_App1
 SG_ LocalizationInitFBD_HR_Ranging_2 : 56|16@1+ (1.0,0) [0|65532] "" IPB_App1
 SG_ LocalizationInitFBD_HR_TimeOfF_2 : 72|16@1+ (15.65,0) [0|1000000] "ps" IPB_App1
 SG_ LocalizationInitFBD_HR_RSSI_1 : 88|8@1+ (1.0,-90) [-90|90] "°" IPB_App1
 SG_ LocalizationInitFBD_HR_Ranging_3 : 96|16@1+ (1.0,0) [0|65532] "" IPB_App1
 SG_ LocalizationInitFBD_HR_TimeOfF_3 : 112|16@1+ (15.65,0) [0|1000000] "ps" IPB_App1
 SG_ LocalizationInitFBD_HR_RSSI_2 : 128|8@1+ (1.0,-90) [-90|90] "°" IPB_App1
 SG_ LocalizationInitFBD_HR_Ranging_4 : 136|16@1+ (1.0,0) [0|65532] "" IPB_App1
 SG_ LocalizationInitFBD_HR_TimeOfF_4 : 152|16@1+ (15.65,0) [0|1000000] "ps" IPB_App1
 SG_ LocalizationInitFBD_HR_RSSI_3 : 168|8@1+ (1.0,-90) [-90|90] "°" IPB_App1
 SG_ LocalizationInitFBD_HR_Ranging_5 : 176|16@1+ (1.0,0) [0|65532] "" IPB_App1
 SG_ LocalizationInitFBD_HR_TimeOfF_5 : 192|16@1+ (15.65,0) [0|1000000] "ps" IPB_App1
 SG_ LocalizationInitFBD_HR_RSSI_4 : 208|8@1+ (1.0,-90) [-90|90] "°" IPB_App1
 SG_ LocalizationInitFBD_HR_Sign_00 : 216|8@1+ (1.0,0) [0|255] "" IPB_App1
 SG_ LocalizationInitFBD_HR_Sign_01 : 224|8@1+ (1.0,0) [0|255] "" IPB_App1
 SG_ LocalizationInitFBD_HR_Sign_02 : 232|8@1+ (1.0,0) [0|255] "" IPB_App1
 SG_ LocalizationInitFBD_HR_Sign_03 : 240|8@1+ (1.0,0) [0|255] "" IPB_App1
 SG_ LocalizationInitFBD_HR_Sign_04 : 248|8@1+ (1.0,0) [0|255] "" IPB_App1
 SG_ LocalizationInitFBD_HR_Sign_05 : 256|8@1+ (1.0,0) [0|255] "" IPB_App1
 SG_ LocalizationInitFBD_HR_Sign_06 : 264|8@1+ (1.0,0) [0|255] "" IPB_App1
 SG_ LocalizationInitFBD_HR_Sign_07 : 272|8@1+ (1.0,0) [0|255] "" IPB_App1
 SG_ LocalizationInitFBD_HR_Sign_08 : 280|8@1+ (1.0,0) [0|255] "" IPB_App1
 SG_ LocalizationInitFBD_HR_Sign_09 : 288|8@1+ (1.0,0) [0|255] "" IPB_App1
 SG_ LocalizationInitFBD_HR_Sign_10 : 296|8@1+ (1.0,0) [0|255] "" IPB_App1
 SG_ LocalizationInitFBD_HR_Sign_11 : 304|8@1+ (1.0,0) [0|255] "" IPB_App1
 SG_ LocalizationInitFBD_HR_Sign_12 : 312|8@1+ (1.0,0) [0|255] "" IPB_App1
 SG_ LocalizationInitFBD_HR_Sign_13 : 320|8@1+ (1.0,0) [0|255] "" IPB_App1
 SG_ LocalizationInitFBD_HR_Sign_14 : 328|8@1+ (1.0,0) [0|255] "" IPB_App1
 SG_ LocalizationInitFBD_HR_Sign_15 : 336|8@1+ (1.0,0) [0|255] "" IPB_App1
 SG_ LocalizationInitFBD_HR_RangingRo : 344|8@1+ (1.0,0) [0|255] "" IPB_App1
 SG_ LocalizationInitFBD_HR_Ranging_6 : 352|8@1+ (1.0,0) [0|255] "" IPB_App1
 SG_ LocalizationInitFBD_HR_Ranging_7 : 360|8@1+ (1.0,0) [0|255] "" IPB_App1
 SG_ LocalizationInitFBD_HR_Ranging_8 : 368|8@1+ (1.0,0) [0|255] "" IPB_App1
 SG_ LocalizationInitFBD_HR_Ranging_9 : 376|8@1+ (1.0,0) [0|255] "" IPB_App1

CM_ SG_ 686 AnalyticsDataFBD_HL_Ranging_Upti "Total ranging uptime, i.e., at least one session active (range: 0s ... 65532s / step: 1s)";
CM_ SG_ 686 AnalyticsDataFBD_HL_Ranging_Coun "Number of resumed ranging sessions (range: 0 ... 65532 / step: 1)";
CM_ SG_ 686 AnalyticsDataFBD_HL_RI_Low_New "Number of received ranging intents with Low_approach_confidence that lead to a ranging session resume (range: 0 ... 65532 / step: 1)";
CM_ SG_ 686 AnalyticsDataFBD_HL_RI_Low_Cont "Number of received ranging intents with Low_approach_confidence that extended a ranging session (range: 0 ... 65532 / step: 1)";
CM_ SG_ 686 AnalyticsDataFBD_HL_RI_Med_New "Number of received ranging intents with Medium_approach_confidence that lead to a ranging session resume (range: 0 ... 65532 / step: 1)";
CM_ SG_ 686 AnalyticsDataFBD_HL_RI_Med_Cont "Number of received ranging intents with Medium_approach_confidence that extended a ranging session (range: 0 ... 65532 / step: 1)";
CM_ SG_ 686 AnalyticsDataFBD_HL_RI_High_New "Number of received ranging intents with High_approach_confidence that lead to a ranging session resume (range: 0 ... 65532 / step: 1)";
CM_ SG_ 686 AnalyticsDataFBD_HL_RI_High_Cont "Number of received ranging intents with High_approach_confidence that extended a ranging session (range: 0 ... 65532 / step: 1)";
CM_ SG_ 686 AnalyticsDataFBD_HL_Ranging_Sess "Number of resumed ranging sessions with continuous invalid ToF values for all anchors (range: 0 ... 65532 / step: 1)";
CM_ SG_ 686 AnalyticsDataFBD_HL_Ranging_Se_2 "Number of resumed ranging sessions localized a within distance to the vehicle between FBD_Only_WUT and FBD_Only_WUT + 1m (range: 0 ... 65532 / step: 1)";
CM_ SG_ 686 AnalyticsDataFBD_HL_Ranging_Se_3 "Number of resumed ranging sessions localized a within distance to the vehicle between FBD_Only_WUT + 1m and FBD_Only_WUT + 2m (range: 0 ... 65532 / step: 1)";
CM_ SG_ 686 AnalyticsDataFBD_HL_Ranging_Se_4 "Number of resumed ranging sessions localized a within distance to the vehicle between FBD_Only_WUT + 2m and FBD_Only_WUT + 3m (range: 0 ... 65532 / step: 1)";
CM_ SG_ 686 AnalyticsDataFBD_HL_Ranging_Se_5 "Number of resumed ranging sessions localized a within distance to the vehicle between FBD_Only_WUT + 3m and FBD_Only_WUT + 4m (range: 0 ... 65532 / step: 1)";
CM_ SG_ 686 AnalyticsDataFBD_HL_Ranging_Se_6 "Number of resumed ranging sessions localized a within distance to the vehicle between FBD_Only_WUT + 4m and FBD_Only_WUT + 5m (range: 0 ... 65532 / step: 1)";
CM_ SG_ 686 AnalyticsDataFBD_HL_Receive_Wind "Cumulated time in receive mode for ranging with digital keys (range: 0s … 6553.2s / step: 0.1s)";
CM_ SG_ 686 AnalyticsDataFBD_HL_Receive_Wi_2 "Cumulated time in receive mode for ranging with key fobs (range: 0s … 6553.2s / step: 0.1s)";
CM_ SG_ 686 AnalyticsDataFBD_HL_Receive_Wi_3 "Cumulated time in receive mode for child presence detection (range: 0s … 6553.2s / step: 0.1s)";
CM_ SG_ 686 AnalyticsDataFBD_HL_FDD_Success_ "Number of successful rangings with the help of a Final_Data distributed over the bus, and originally received via UWB (range: 0 ... 65532 / step: 1)";
CM_ SG_ 686 AnalyticsDataFBD_HL_FDD_Succes_2 "Number of successful rangings with the help of a Final_Data distributed over the bus, and originally received via BLE (range: 0 ... 65532 / step: 1)";
CM_ SG_ 686 AnalyticsDataFBD_HL_RSSI_New "Number of detected RSSI motion sensing ranging intents that lead to a ranging session resume (range: 0 ... 65532 / step: 1)";
CM_ SG_ 686 AnalyticsDataFBD_HL_RSSI_Cont "Number of detected RSSI motion sensing ranging intents that extended a ranging session (range: 0 ... 65532 / step: 1)";
CM_ SG_ 686 AnalyticsDataFBD_HL_BLE_Localiza "contains localization uptime";
CM_ SG_ 686 AnalyticsDataFBD_HL_BLE_Locali_2 "contains localization count";
CM_ SG_ 686 AnalyticsDataFBD_HL_Fallback_Mod "contains localization count";
CM_ SG_ 681 AnalyticsDataFBD_HM_Ranging_Upti "Total ranging uptime, i.e., at least one session active (range: 0s ... 65532s / step: 1s)";
CM_ SG_ 681 AnalyticsDataFBD_HM_Ranging_Coun "Number of resumed ranging sessions (range: 0 ... 65532 / step: 1)";
CM_ SG_ 681 AnalyticsDataFBD_HM_RI_Low_New "Number of received ranging intents with Low_approach_confidence that lead to a ranging session resume (range: 0 ... 65532 / step: 1)";
CM_ SG_ 681 AnalyticsDataFBD_HM_RI_Low_Cont "Number of received ranging intents with Low_approach_confidence that extended a ranging session (range: 0 ... 65532 / step: 1)";
CM_ SG_ 681 AnalyticsDataFBD_HM_RI_Med_New "Number of received ranging intents with Medium_approach_confidence that lead to a ranging session resume (range: 0 ... 65532 / step: 1)";
CM_ SG_ 681 AnalyticsDataFBD_HM_RI_Med_Cont "Number of received ranging intents with Medium_approach_confidence that extended a ranging session (range: 0 ... 65532 / step: 1)";
CM_ SG_ 681 AnalyticsDataFBD_HM_RI_High_New "Number of received ranging intents with High_approach_confidence that lead to a ranging session resume (range: 0 ... 65532 / step: 1)";
CM_ SG_ 681 AnalyticsDataFBD_HM_RI_High_Cont "Number of received ranging intents with High_approach_confidence that extended a ranging session (range: 0 ... 65532 / step: 1)";
CM_ SG_ 681 AnalyticsDataFBD_HM_Ranging_Sess "Number of resumed ranging sessions with continuous invalid ToF values for all anchors (range: 0 ... 65532 / step: 1)";
CM_ SG_ 681 AnalyticsDataFBD_HM_Ranging_Se_2 "Number of resumed ranging sessions localized a within distance to the vehicle between FBD_Only_WUT and FBD_Only_WUT + 1m (range: 0 ... 65532 / step: 1)";
CM_ SG_ 681 AnalyticsDataFBD_HM_Ranging_Se_3 "Number of resumed ranging sessions localized a within distance to the vehicle between FBD_Only_WUT + 1m and FBD_Only_WUT + 2m (range: 0 ... 65532 / step: 1)";
CM_ SG_ 681 AnalyticsDataFBD_HM_Ranging_Se_4 "Number of resumed ranging sessions localized a within distance to the vehicle between FBD_Only_WUT + 2m and FBD_Only_WUT + 3m (range: 0 ... 65532 / step: 1)";
CM_ SG_ 681 AnalyticsDataFBD_HM_Ranging_Se_5 "Number of resumed ranging sessions localized a within distance to the vehicle between FBD_Only_WUT + 3m and FBD_Only_WUT + 4m (range: 0 ... 65532 / step: 1)";
CM_ SG_ 681 AnalyticsDataFBD_HM_Ranging_Se_6 "Number of resumed ranging sessions localized a within distance to the vehicle between FBD_Only_WUT + 4m and FBD_Only_WUT + 5m (range: 0 ... 65532 / step: 1)";
CM_ SG_ 681 AnalyticsDataFBD_HM_Receive_Wind "Cumulated time in receive mode for ranging with digital keys (range: 0s … 6553.2s / step: 0.1s)";
CM_ SG_ 681 AnalyticsDataFBD_HM_Receive_Wi_2 "Cumulated time in receive mode for ranging with key fobs (range: 0s … 6553.2s / step: 0.1s)";
CM_ SG_ 681 AnalyticsDataFBD_HM_Receive_Wi_3 "Cumulated time in receive mode for child presence detection (range: 0s … 6553.2s / step: 0.1s)";
CM_ SG_ 681 AnalyticsDataFBD_HM_FDD_Success_ "Number of successful rangings with the help of a Final_Data distributed over the bus, and originally received via UWB (range: 0 ... 65532 / step: 1)";
CM_ SG_ 681 AnalyticsDataFBD_HM_FDD_Succes_2 "Number of successful rangings with the help of a Final_Data distributed over the bus, and originally received via BLE (range: 0 ... 65532 / step: 1)";
CM_ SG_ 681 AnalyticsDataFBD_HM_RSSI_New "Number of detected RSSI motion sensing ranging intents that lead to a ranging session resume (range: 0 ... 65532 / step: 1)";
CM_ SG_ 681 AnalyticsDataFBD_HM_RSSI_Cont "Number of detected RSSI motion sensing ranging intents that extended a ranging session (range: 0 ... 65532 / step: 1)";
CM_ SG_ 681 AnalyticsDataFBD_HM_BLE_Localiza "contains localization uptime";
CM_ SG_ 681 AnalyticsDataFBD_HM_BLE_Locali_2 "contains localization count";
CM_ SG_ 681 AnalyticsDataFBD_HM_Fallback_Mod "contains localization count";
CM_ SG_ 687 AnalyticsDataFBD_HR_Ranging_Upti "Total ranging uptime, i.e., at least one session active (range: 0s ... 65532s / step: 1s)";
CM_ SG_ 687 AnalyticsDataFBD_HR_Ranging_Coun "Number of resumed ranging sessions (range: 0 ... 65532 / step: 1)";
CM_ SG_ 687 AnalyticsDataFBD_HR_RI_Low_New "Number of received ranging intents with Low_approach_confidence that lead to a ranging session resume (range: 0 ... 65532 / step: 1)";
CM_ SG_ 687 AnalyticsDataFBD_HR_RI_Low_Cont "Number of received ranging intents with Low_approach_confidence that extended a ranging session (range: 0 ... 65532 / step: 1)";
CM_ SG_ 687 AnalyticsDataFBD_HR_RI_Med_New "Number of received ranging intents with Medium_approach_confidence that lead to a ranging session resume (range: 0 ... 65532 / step: 1)";
CM_ SG_ 687 AnalyticsDataFBD_HR_RI_Med_Cont "Number of received ranging intents with Medium_approach_confidence that extended a ranging session (range: 0 ... 65532 / step: 1)";
CM_ SG_ 687 AnalyticsDataFBD_HR_RI_High_New "Number of received ranging intents with High_approach_confidence that lead to a ranging session resume (range: 0 ... 65532 / step: 1)";
CM_ SG_ 687 AnalyticsDataFBD_HR_RI_High_Cont "Number of received ranging intents with High_approach_confidence that extended a ranging session (range: 0 ... 65532 / step: 1)";
CM_ SG_ 687 AnalyticsDataFBD_HR_Ranging_Sess "Number of resumed ranging sessions with continuous invalid ToF values for all anchors (range: 0 ... 65532 / step: 1)";
CM_ SG_ 687 AnalyticsDataFBD_HR_Ranging_Se_2 "Number of resumed ranging sessions localized a within distance to the vehicle between FBD_Only_WUT and FBD_Only_WUT + 1m (range: 0 ... 65532 / step: 1)";
CM_ SG_ 687 AnalyticsDataFBD_HR_Ranging_Se_3 "Number of resumed ranging sessions localized a within distance to the vehicle between FBD_Only_WUT + 1m and FBD_Only_WUT + 2m (range: 0 ... 65532 / step: 1)";
CM_ SG_ 687 AnalyticsDataFBD_HR_Ranging_Se_4 "Number of resumed ranging sessions localized a within distance to the vehicle between FBD_Only_WUT + 2m and FBD_Only_WUT + 3m (range: 0 ... 65532 / step: 1)";
CM_ SG_ 687 AnalyticsDataFBD_HR_Ranging_Se_5 "Number of resumed ranging sessions localized a within distance to the vehicle between FBD_Only_WUT + 3m and FBD_Only_WUT + 4m (range: 0 ... 65532 / step: 1)";
CM_ SG_ 687 AnalyticsDataFBD_HR_Ranging_Se_6 "Number of resumed ranging sessions localized a within distance to the vehicle between FBD_Only_WUT + 4m and FBD_Only_WUT + 5m (range: 0 ... 65532 / step: 1)";
CM_ SG_ 687 AnalyticsDataFBD_HR_Receive_Wind "Cumulated time in receive mode for ranging with digital keys (range: 0s … 6553.2s / step: 0.1s)";
CM_ SG_ 687 AnalyticsDataFBD_HR_Receive_Wi_2 "Cumulated time in receive mode for ranging with key fobs (range: 0s … 6553.2s / step: 0.1s)";
CM_ SG_ 687 AnalyticsDataFBD_HR_Receive_Wi_3 "Cumulated time in receive mode for child presence detection (range: 0s … 6553.2s / step: 0.1s)";
CM_ SG_ 687 AnalyticsDataFBD_HR_FDD_Success_ "Number of successful rangings with the help of a Final_Data distributed over the bus, and originally received via UWB (range: 0 ... 65532 / step: 1)";
CM_ SG_ 687 AnalyticsDataFBD_HR_FDD_Succes_2 "Number of successful rangings with the help of a Final_Data distributed over the bus, and originally received via BLE (range: 0 ... 65532 / step: 1)";
CM_ SG_ 687 AnalyticsDataFBD_HR_RSSI_New "Number of detected RSSI motion sensing ranging intents that lead to a ranging session resume (range: 0 ... 65532 / step: 1)";
CM_ SG_ 687 AnalyticsDataFBD_HR_RSSI_Cont "Number of detected RSSI motion sensing ranging intents that extended a ranging session (range: 0 ... 65532 / step: 1)";
CM_ SG_ 687 AnalyticsDataFBD_HR_BLE_Localiza "contains localization uptime";
CM_ SG_ 687 AnalyticsDataFBD_HR_BLE_Locali_2 "contains localization count";
CM_ SG_ 687 AnalyticsDataFBD_HR_Fallback_Mod "contains localization count";
CM_ SG_ 682 AnalyticsDataFBD_Miko_Ranging_Up "Total ranging uptime, i.e., at least one session active (range: 0s ... 65532s / step: 1s)";
CM_ SG_ 682 AnalyticsDataFBD_Miko_Ranging_Co "Number of resumed ranging sessions (range: 0 ... 65532 / step: 1)";
CM_ SG_ 682 AnalyticsDataFBD_Miko_RI_Low_New "Number of received ranging intents with Low_approach_confidence that lead to a ranging session resume (range: 0 ... 65532 / step: 1)";
CM_ SG_ 682 AnalyticsDataFBD_Miko_RI_Low_Con "Number of received ranging intents with Low_approach_confidence that extended a ranging session (range: 0 ... 65532 / step: 1)";
CM_ SG_ 682 AnalyticsDataFBD_Miko_RI_Med_New "Number of received ranging intents with Medium_approach_confidence that lead to a ranging session resume (range: 0 ... 65532 / step: 1)";
CM_ SG_ 682 AnalyticsDataFBD_Miko_RI_Med_Con "Number of received ranging intents with Medium_approach_confidence that extended a ranging session (range: 0 ... 65532 / step: 1)";
CM_ SG_ 682 AnalyticsDataFBD_Miko_RI_High_Ne "Number of received ranging intents with High_approach_confidence that lead to a ranging session resume (range: 0 ... 65532 / step: 1)";
CM_ SG_ 682 AnalyticsDataFBD_Miko_RI_High_Co "Number of received ranging intents with High_approach_confidence that extended a ranging session (range: 0 ... 65532 / step: 1)";
CM_ SG_ 682 AnalyticsDataFBD_Miko_Ranging_Se "Number of resumed ranging sessions with continuous invalid ToF values for all anchors (range: 0 ... 65532 / step: 1)";
CM_ SG_ 682 AnalyticsDataFBD_Miko_Ranging__2 "Number of resumed ranging sessions localized a within distance to the vehicle between FBD_Only_WUT and FBD_Only_WUT + 1m (range: 0 ... 65532 / step: 1)";
CM_ SG_ 682 AnalyticsDataFBD_Miko_Ranging__3 "Number of resumed ranging sessions localized a within distance to the vehicle between FBD_Only_WUT + 1m and FBD_Only_WUT + 2m (range: 0 ... 65532 / step: 1)";
CM_ SG_ 682 AnalyticsDataFBD_Miko_Ranging__4 "Number of resumed ranging sessions localized a within distance to the vehicle between FBD_Only_WUT + 2m and FBD_Only_WUT + 3m (range: 0 ... 65532 / step: 1)";
CM_ SG_ 682 AnalyticsDataFBD_Miko_Ranging__5 "Number of resumed ranging sessions localized a within distance to the vehicle between FBD_Only_WUT + 3m and FBD_Only_WUT + 4m (range: 0 ... 65532 / step: 1)";
CM_ SG_ 682 AnalyticsDataFBD_Miko_Ranging__6 "Number of resumed ranging sessions localized a within distance to the vehicle between FBD_Only_WUT + 4m and FBD_Only_WUT + 5m (range: 0 ... 65532 / step: 1)";
CM_ SG_ 682 AnalyticsDataFBD_Miko_Receive_Wi "Cumulated time in receive mode for ranging with digital keys (range: 0s … 6553.2s / step: 0.1s)";
CM_ SG_ 682 AnalyticsDataFBD_Miko_Receive__2 "Cumulated time in receive mode for ranging with key fobs (range: 0s … 6553.2s / step: 0.1s)";
CM_ SG_ 682 AnalyticsDataFBD_Miko_Receive__3 "Cumulated time in receive mode for child presence detection (range: 0s … 6553.2s / step: 0.1s)";
CM_ SG_ 682 AnalyticsDataFBD_Miko_FDD_Succes "Number of successful rangings with the help of a Final_Data distributed over the bus, and originally received via UWB (range: 0 ... 65532 / step: 1)";
CM_ SG_ 682 AnalyticsDataFBD_Miko_FDD_Succ_2 "Number of successful rangings with the help of a Final_Data distributed over the bus, and originally received via BLE (range: 0 ... 65532 / step: 1)";
CM_ SG_ 682 AnalyticsDataFBD_Miko_RSSI_New "Number of detected RSSI motion sensing ranging intents that lead to a ranging session resume (range: 0 ... 65532 / step: 1)";
CM_ SG_ 682 AnalyticsDataFBD_Miko_RSSI_Cont "Number of detected RSSI motion sensing ranging intents that extended a ranging session (range: 0 ... 65532 / step: 1)";
CM_ SG_ 682 AnalyticsDataFBD_Miko_BLE_Locali "contains localization uptime";
CM_ SG_ 682 AnalyticsDataFBD_Miko_BLE_Loca_2 "contains localization count";
CM_ SG_ 682 AnalyticsDataFBD_Miko_Fallback_M "contains localization count";
CM_ SG_ 690 AnalyticsDataFBD_MM_Ranging_Upti "Total ranging uptime, i.e., at least one session active (range: 0s ... 65532s / step: 1s)";
CM_ SG_ 690 AnalyticsDataFBD_MM_Ranging_Coun "Number of resumed ranging sessions (range: 0 ... 65532 / step: 1)";
CM_ SG_ 690 AnalyticsDataFBD_MM_RI_Low_New "Number of received ranging intents with Low_approach_confidence that lead to a ranging session resume (range: 0 ... 65532 / step: 1)";
CM_ SG_ 690 AnalyticsDataFBD_MM_RI_Low_Cont "Number of received ranging intents with Low_approach_confidence that extended a ranging session (range: 0 ... 65532 / step: 1)";
CM_ SG_ 690 AnalyticsDataFBD_MM_RI_Med_New "Number of received ranging intents with Medium_approach_confidence that lead to a ranging session resume (range: 0 ... 65532 / step: 1)";
CM_ SG_ 690 AnalyticsDataFBD_MM_RI_Med_Cont "Number of received ranging intents with Medium_approach_confidence that extended a ranging session (range: 0 ... 65532 / step: 1)";
CM_ SG_ 690 AnalyticsDataFBD_MM_RI_High_New "Number of received ranging intents with High_approach_confidence that lead to a ranging session resume (range: 0 ... 65532 / step: 1)";
CM_ SG_ 690 AnalyticsDataFBD_MM_RI_High_Cont "Number of received ranging intents with High_approach_confidence that extended a ranging session (range: 0 ... 65532 / step: 1)";
CM_ SG_ 690 AnalyticsDataFBD_MM_Ranging_Sess "Number of resumed ranging sessions with continuous invalid ToF values for all anchors (range: 0 ... 65532 / step: 1)";
CM_ SG_ 690 AnalyticsDataFBD_MM_Ranging_Se_2 "Number of resumed ranging sessions localized a within distance to the vehicle between FBD_Only_WUT and FBD_Only_WUT + 1m (range: 0 ... 65532 / step: 1)";
CM_ SG_ 690 AnalyticsDataFBD_MM_Ranging_Se_3 "Number of resumed ranging sessions localized a within distance to the vehicle between FBD_Only_WUT + 1m and FBD_Only_WUT + 2m (range: 0 ... 65532 / step: 1)";
CM_ SG_ 690 AnalyticsDataFBD_MM_Ranging_Se_4 "Number of resumed ranging sessions localized a within distance to the vehicle between FBD_Only_WUT + 2m and FBD_Only_WUT + 3m (range: 0 ... 65532 / step: 1)";
CM_ SG_ 690 AnalyticsDataFBD_MM_Ranging_Se_5 "Number of resumed ranging sessions localized a within distance to the vehicle between FBD_Only_WUT + 3m and FBD_Only_WUT + 4m (range: 0 ... 65532 / step: 1)";
CM_ SG_ 690 AnalyticsDataFBD_MM_Ranging_Se_6 "Number of resumed ranging sessions localized a within distance to the vehicle between FBD_Only_WUT + 4m and FBD_Only_WUT + 5m (range: 0 ... 65532 / step: 1)";
CM_ SG_ 690 AnalyticsDataFBD_MM_Receive_Wind "Cumulated time in receive mode for ranging with digital keys (range: 0s … 6553.2s / step: 0.1s)";
CM_ SG_ 690 AnalyticsDataFBD_MM_Receive_Wi_2 "Cumulated time in receive mode for ranging with key fobs (range: 0s … 6553.2s / step: 0.1s)";
CM_ SG_ 690 AnalyticsDataFBD_MM_Receive_Wi_3 "Cumulated time in receive mode for child presence detection (range: 0s … 6553.2s / step: 0.1s)";
CM_ SG_ 690 AnalyticsDataFBD_MM_FDD_Success_ "Number of successful rangings with the help of a Final_Data distributed over the bus, and originally received via UWB (range: 0 ... 65532 / step: 1)";
CM_ SG_ 690 AnalyticsDataFBD_MM_FDD_Succes_2 "Number of successful rangings with the help of a Final_Data distributed over the bus, and originally received via BLE (range: 0 ... 65532 / step: 1)";
CM_ SG_ 690 AnalyticsDataFBD_MM_RSSI_New "Number of detected RSSI motion sensing ranging intents that lead to a ranging session resume (range: 0 ... 65532 / step: 1)";
CM_ SG_ 690 AnalyticsDataFBD_MM_RSSI_Cont "Number of detected RSSI motion sensing ranging intents that extended a ranging session (range: 0 ... 65532 / step: 1)";
CM_ SG_ 690 AnalyticsDataFBD_MM_BLE_Localiza "contains localization uptime";
CM_ SG_ 690 AnalyticsDataFBD_MM_BLE_Locali_2 "contains localization count";
CM_ SG_ 690 AnalyticsDataFBD_MM_Fallback_Mod "contains localization count";
CM_ SG_ 683 AnalyticsDataFBD_Trunk_Ranging_U "Total ranging uptime, i.e., at least one session active (range: 0s ... 65532s / step: 1s)";
CM_ SG_ 683 AnalyticsDataFBD_Trunk_Ranging_C "Number of resumed ranging sessions (range: 0 ... 65532 / step: 1)";
CM_ SG_ 683 AnalyticsDataFBD_Trunk_RI_Low_Ne "Number of received ranging intents with Low_approach_confidence that lead to a ranging session resume (range: 0 ... 65532 / step: 1)";
CM_ SG_ 683 AnalyticsDataFBD_Trunk_RI_Low_Co "Number of received ranging intents with Low_approach_confidence that extended a ranging session (range: 0 ... 65532 / step: 1)";
CM_ SG_ 683 AnalyticsDataFBD_Trunk_RI_Med_Ne "Number of received ranging intents with Medium_approach_confidence that lead to a ranging session resume (range: 0 ... 65532 / step: 1)";
CM_ SG_ 683 AnalyticsDataFBD_Trunk_RI_Med_Co "Number of received ranging intents with Medium_approach_confidence that extended a ranging session (range: 0 ... 65532 / step: 1)";
CM_ SG_ 683 AnalyticsDataFBD_Trunk_RI_High_N "Number of received ranging intents with High_approach_confidence that lead to a ranging session resume (range: 0 ... 65532 / step: 1)";
CM_ SG_ 683 AnalyticsDataFBD_Trunk_RI_High_C "Number of received ranging intents with High_approach_confidence that extended a ranging session (range: 0 ... 65532 / step: 1)";
CM_ SG_ 683 AnalyticsDataFBD_Trunk_Ranging_S "Number of resumed ranging sessions with continuous invalid ToF values for all anchors (range: 0 ... 65532 / step: 1)";
CM_ SG_ 683 AnalyticsDataFBD_Trunk_Ranging_2 "Number of resumed ranging sessions localized a within distance to the vehicle between FBD_Only_WUT and FBD_Only_WUT + 1m (range: 0 ... 65532 / step: 1)";
CM_ SG_ 683 AnalyticsDataFBD_Trunk_Ranging_3 "Number of resumed ranging sessions localized a within distance to the vehicle between FBD_Only_WUT + 1m and FBD_Only_WUT + 2m (range: 0 ... 65532 / step: 1)";
CM_ SG_ 683 AnalyticsDataFBD_Trunk_Ranging_4 "Number of resumed ranging sessions localized a within distance to the vehicle between FBD_Only_WUT + 2m and FBD_Only_WUT + 3m (range: 0 ... 65532 / step: 1)";
CM_ SG_ 683 AnalyticsDataFBD_Trunk_Ranging_5 "Number of resumed ranging sessions localized a within distance to the vehicle between FBD_Only_WUT + 3m and FBD_Only_WUT + 4m (range: 0 ... 65532 / step: 1)";
CM_ SG_ 683 AnalyticsDataFBD_Trunk_Ranging_6 "Number of resumed ranging sessions localized a within distance to the vehicle between FBD_Only_WUT + 4m and FBD_Only_WUT + 5m (range: 0 ... 65532 / step: 1)";
CM_ SG_ 683 AnalyticsDataFBD_Trunk_Receive_W "Cumulated time in receive mode for ranging with digital keys (range: 0s … 6553.2s / step: 0.1s)";
CM_ SG_ 683 AnalyticsDataFBD_Trunk_Receive_2 "Cumulated time in receive mode for ranging with key fobs (range: 0s … 6553.2s / step: 0.1s)";
CM_ SG_ 683 AnalyticsDataFBD_Trunk_Receive_3 "Cumulated time in receive mode for child presence detection (range: 0s … 6553.2s / step: 0.1s)";
CM_ SG_ 683 AnalyticsDataFBD_Trunk_FDD_Succe "Number of successful rangings with the help of a Final_Data distributed over the bus, and originally received via UWB (range: 0 ... 65532 / step: 1)";
CM_ SG_ 683 AnalyticsDataFBD_Trunk_FDD_Suc_2 "Number of successful rangings with the help of a Final_Data distributed over the bus, and originally received via BLE (range: 0 ... 65532 / step: 1)";
CM_ SG_ 683 AnalyticsDataFBD_Trunk_RSSI_New "Number of detected RSSI motion sensing ranging intents that lead to a ranging session resume (range: 0 ... 65532 / step: 1)";
CM_ SG_ 683 AnalyticsDataFBD_Trunk_RSSI_Cont "Number of detected RSSI motion sensing ranging intents that extended a ranging session (range: 0 ... 65532 / step: 1)";
CM_ SG_ 683 AnalyticsDataFBD_Trunk_BLE_Local "contains localization uptime";
CM_ SG_ 683 AnalyticsDataFBD_Trunk_BLE_Loc_2 "contains localization count";
CM_ SG_ 683 AnalyticsDataFBD_Trunk_Fallback_ "contains localization count";
CM_ SG_ 684 AnalyticsDataFBD_VL_Ranging_Upti "Total ranging uptime, i.e., at least one session active (range: 0s ... 65532s / step: 1s)";
CM_ SG_ 684 AnalyticsDataFBD_VL_Ranging_Coun "Number of resumed ranging sessions (range: 0 ... 65532 / step: 1)";
CM_ SG_ 684 AnalyticsDataFBD_VL_RI_Low_New "Number of received ranging intents with Low_approach_confidence that lead to a ranging session resume (range: 0 ... 65532 / step: 1)";
CM_ SG_ 684 AnalyticsDataFBD_VL_RI_Low_Cont "Number of received ranging intents with Low_approach_confidence that extended a ranging session (range: 0 ... 65532 / step: 1)";
CM_ SG_ 684 AnalyticsDataFBD_VL_RI_Med_New "Number of received ranging intents with Medium_approach_confidence that lead to a ranging session resume (range: 0 ... 65532 / step: 1)";
CM_ SG_ 684 AnalyticsDataFBD_VL_RI_Med_Cont "Number of received ranging intents with Medium_approach_confidence that extended a ranging session (range: 0 ... 65532 / step: 1)";
CM_ SG_ 684 AnalyticsDataFBD_VL_RI_High_New "Number of received ranging intents with High_approach_confidence that lead to a ranging session resume (range: 0 ... 65532 / step: 1)";
CM_ SG_ 684 AnalyticsDataFBD_VL_RI_High_Cont "Number of received ranging intents with High_approach_confidence that extended a ranging session (range: 0 ... 65532 / step: 1)";
CM_ SG_ 684 AnalyticsDataFBD_VL_Ranging_Sess "Number of resumed ranging sessions with continuous invalid ToF values for all anchors (range: 0 ... 65532 / step: 1)";
CM_ SG_ 684 AnalyticsDataFBD_VL_Ranging_Se_2 "Number of resumed ranging sessions localized a within distance to the vehicle between FBD_Only_WUT and FBD_Only_WUT + 1m (range: 0 ... 65532 / step: 1)";
CM_ SG_ 684 AnalyticsDataFBD_VL_Ranging_Se_3 "Number of resumed ranging sessions localized a within distance to the vehicle between FBD_Only_WUT + 1m and FBD_Only_WUT + 2m (range: 0 ... 65532 / step: 1)";
CM_ SG_ 684 AnalyticsDataFBD_VL_Ranging_Se_4 "Number of resumed ranging sessions localized a within distance to the vehicle between FBD_Only_WUT + 2m and FBD_Only_WUT + 3m (range: 0 ... 65532 / step: 1)";
CM_ SG_ 684 AnalyticsDataFBD_VL_Ranging_Se_5 "Number of resumed ranging sessions localized a within distance to the vehicle between FBD_Only_WUT + 3m and FBD_Only_WUT + 4m (range: 0 ... 65532 / step: 1)";
CM_ SG_ 684 AnalyticsDataFBD_VL_Ranging_Se_6 "Number of resumed ranging sessions localized a within distance to the vehicle between FBD_Only_WUT + 4m and FBD_Only_WUT + 5m (range: 0 ... 65532 / step: 1)";
CM_ SG_ 684 AnalyticsDataFBD_VL_Receive_Wind "Cumulated time in receive mode for ranging with digital keys (range: 0s … 6553.2s / step: 0.1s)";
CM_ SG_ 684 AnalyticsDataFBD_VL_Receive_Wi_2 "Cumulated time in receive mode for ranging with key fobs (range: 0s … 6553.2s / step: 0.1s)";
CM_ SG_ 684 AnalyticsDataFBD_VL_Receive_Wi_3 "Cumulated time in receive mode for child presence detection (range: 0s … 6553.2s / step: 0.1s)";
CM_ SG_ 684 AnalyticsDataFBD_VL_FDD_Success_ "Number of successful rangings with the help of a Final_Data distributed over the bus, and originally received via UWB (range: 0 ... 65532 / step: 1)";
CM_ SG_ 684 AnalyticsDataFBD_VL_FDD_Succes_2 "Number of successful rangings with the help of a Final_Data distributed over the bus, and originally received via BLE (range: 0 ... 65532 / step: 1)";
CM_ SG_ 684 AnalyticsDataFBD_VL_RSSI_New "Number of detected RSSI motion sensing ranging intents that lead to a ranging session resume (range: 0 ... 65532 / step: 1)";
CM_ SG_ 684 AnalyticsDataFBD_VL_RSSI_Cont "Number of detected RSSI motion sensing ranging intents that extended a ranging session (range: 0 ... 65532 / step: 1)";
CM_ SG_ 684 AnalyticsDataFBD_VL_BLE_Localiza "contains localization uptime";
CM_ SG_ 684 AnalyticsDataFBD_VL_BLE_Locali_2 "contains localization count";
CM_ SG_ 684 AnalyticsDataFBD_VL_Fallback_Mod "contains localization count";
CM_ SG_ 680 AnalyticsDataFBD_VM_Ranging_Upti "Total ranging uptime, i.e., at least one session active (range: 0s ... 65532s / step: 1s)";
CM_ SG_ 680 AnalyticsDataFBD_VM_Ranging_Coun "Number of resumed ranging sessions (range: 0 ... 65532 / step: 1)";
CM_ SG_ 680 AnalyticsDataFBD_VM_RI_Low_New "Number of received ranging intents with Low_approach_confidence that lead to a ranging session resume (range: 0 ... 65532 / step: 1)";
CM_ SG_ 680 AnalyticsDataFBD_VM_RI_Low_Cont "Number of received ranging intents with Low_approach_confidence that extended a ranging session (range: 0 ... 65532 / step: 1)";
CM_ SG_ 680 AnalyticsDataFBD_VM_RI_Med_New "Number of received ranging intents with Medium_approach_confidence that lead to a ranging session resume (range: 0 ... 65532 / step: 1)";
CM_ SG_ 680 AnalyticsDataFBD_VM_RI_Med_Cont "Number of received ranging intents with Medium_approach_confidence that extended a ranging session (range: 0 ... 65532 / step: 1)";
CM_ SG_ 680 AnalyticsDataFBD_VM_RI_High_New "Number of received ranging intents with High_approach_confidence that lead to a ranging session resume (range: 0 ... 65532 / step: 1)";
CM_ SG_ 680 AnalyticsDataFBD_VM_RI_High_Cont "Number of received ranging intents with High_approach_confidence that extended a ranging session (range: 0 ... 65532 / step: 1)";
CM_ SG_ 680 AnalyticsDataFBD_VM_Ranging_Sess "Number of resumed ranging sessions with continuous invalid ToF values for all anchors (range: 0 ... 65532 / step: 1)";
CM_ SG_ 680 AnalyticsDataFBD_VM_Ranging_Se_2 "Number of resumed ranging sessions localized a within distance to the vehicle between FBD_Only_WUT and FBD_Only_WUT + 1m (range: 0 ... 65532 / step: 1)";
CM_ SG_ 680 AnalyticsDataFBD_VM_Ranging_Se_3 "Number of resumed ranging sessions localized a within distance to the vehicle between FBD_Only_WUT + 1m and FBD_Only_WUT + 2m (range: 0 ... 65532 / step: 1)";
CM_ SG_ 680 AnalyticsDataFBD_VM_Ranging_Se_4 "Number of resumed ranging sessions localized a within distance to the vehicle between FBD_Only_WUT + 2m and FBD_Only_WUT + 3m (range: 0 ... 65532 / step: 1)";
CM_ SG_ 680 AnalyticsDataFBD_VM_Ranging_Se_5 "Number of resumed ranging sessions localized a within distance to the vehicle between FBD_Only_WUT + 3m and FBD_Only_WUT + 4m (range: 0 ... 65532 / step: 1)";
CM_ SG_ 680 AnalyticsDataFBD_VM_Ranging_Se_6 "Number of resumed ranging sessions localized a within distance to the vehicle between FBD_Only_WUT + 4m and FBD_Only_WUT + 5m (range: 0 ... 65532 / step: 1)";
CM_ SG_ 680 AnalyticsDataFBD_VM_Receive_Wind "Cumulated time in receive mode for ranging with digital keys (range: 0s … 6553.2s / step: 0.1s)";
CM_ SG_ 680 AnalyticsDataFBD_VM_Receive_Wi_2 "Cumulated time in receive mode for ranging with key fobs (range: 0s … 6553.2s / step: 0.1s)";
CM_ SG_ 680 AnalyticsDataFBD_VM_Receive_Wi_3 "Cumulated time in receive mode for child presence detection (range: 0s … 6553.2s / step: 0.1s)";
CM_ SG_ 680 AnalyticsDataFBD_VM_FDD_Success_ "Number of successful rangings with the help of a Final_Data distributed over the bus, and originally received via UWB (range: 0 ... 65532 / step: 1)";
CM_ SG_ 680 AnalyticsDataFBD_VM_FDD_Succes_2 "Number of successful rangings with the help of a Final_Data distributed over the bus, and originally received via BLE (range: 0 ... 65532 / step: 1)";
CM_ SG_ 680 AnalyticsDataFBD_VM_RSSI_New "Number of detected RSSI motion sensing ranging intents that lead to a ranging session resume (range: 0 ... 65532 / step: 1)";
CM_ SG_ 680 AnalyticsDataFBD_VM_RSSI_Cont "Number of detected RSSI motion sensing ranging intents that extended a ranging session (range: 0 ... 65532 / step: 1)";
CM_ SG_ 680 AnalyticsDataFBD_VM_BLE_Localiza "contains localization uptime";
CM_ SG_ 680 AnalyticsDataFBD_VM_BLE_Locali_2 "contains localization count";
CM_ SG_ 680 AnalyticsDataFBD_VM_Fallback_Mod "contains localization count";
CM_ SG_ 685 AnalyticsDataFBD_VR_Ranging_Upti "Total ranging uptime, i.e., at least one session active (range: 0s ... 65532s / step: 1s)";
CM_ SG_ 685 AnalyticsDataFBD_VR_Ranging_Coun "Number of resumed ranging sessions (range: 0 ... 65532 / step: 1)";
CM_ SG_ 685 AnalyticsDataFBD_VR_RI_Low_New "Number of received ranging intents with Low_approach_confidence that lead to a ranging session resume (range: 0 ... 65532 / step: 1)";
CM_ SG_ 685 AnalyticsDataFBD_VR_RI_Low_Cont "Number of received ranging intents with Low_approach_confidence that extended a ranging session (range: 0 ... 65532 / step: 1)";
CM_ SG_ 685 AnalyticsDataFBD_VR_RI_Med_New "Number of received ranging intents with Medium_approach_confidence that lead to a ranging session resume (range: 0 ... 65532 / step: 1)";
CM_ SG_ 685 AnalyticsDataFBD_VR_RI_Med_Cont "Number of received ranging intents with Medium_approach_confidence that extended a ranging session (range: 0 ... 65532 / step: 1)";
CM_ SG_ 685 AnalyticsDataFBD_VR_RI_High_New "Number of received ranging intents with High_approach_confidence that lead to a ranging session resume (range: 0 ... 65532 / step: 1)";
CM_ SG_ 685 AnalyticsDataFBD_VR_RI_High_Cont "Number of received ranging intents with High_approach_confidence that extended a ranging session (range: 0 ... 65532 / step: 1)";
CM_ SG_ 685 AnalyticsDataFBD_VR_Ranging_Sess "Number of resumed ranging sessions with continuous invalid ToF values for all anchors (range: 0 ... 65532 / step: 1)";
CM_ SG_ 685 AnalyticsDataFBD_VR_Ranging_Se_2 "Number of resumed ranging sessions localized a within distance to the vehicle between FBD_Only_WUT and FBD_Only_WUT + 1m (range: 0 ... 65532 / step: 1)";
CM_ SG_ 685 AnalyticsDataFBD_VR_Ranging_Se_3 "Number of resumed ranging sessions localized a within distance to the vehicle between FBD_Only_WUT + 1m and FBD_Only_WUT + 2m (range: 0 ... 65532 / step: 1)";
CM_ SG_ 685 AnalyticsDataFBD_VR_Ranging_Se_4 "Number of resumed ranging sessions localized a within distance to the vehicle between FBD_Only_WUT + 2m and FBD_Only_WUT + 3m (range: 0 ... 65532 / step: 1)";
CM_ SG_ 685 AnalyticsDataFBD_VR_Ranging_Se_5 "Number of resumed ranging sessions localized a within distance to the vehicle between FBD_Only_WUT + 3m and FBD_Only_WUT + 4m (range: 0 ... 65532 / step: 1)";
CM_ SG_ 685 AnalyticsDataFBD_VR_Ranging_Se_6 "Number of resumed ranging sessions localized a within distance to the vehicle between FBD_Only_WUT + 4m and FBD_Only_WUT + 5m (range: 0 ... 65532 / step: 1)";
CM_ SG_ 685 AnalyticsDataFBD_VR_Receive_Wind "Cumulated time in receive mode for ranging with digital keys (range: 0s … 6553.2s / step: 0.1s)";
CM_ SG_ 685 AnalyticsDataFBD_VR_Receive_Wi_2 "Cumulated time in receive mode for ranging with key fobs (range: 0s … 6553.2s / step: 0.1s)";
CM_ SG_ 685 AnalyticsDataFBD_VR_Receive_Wi_3 "Cumulated time in receive mode for child presence detection (range: 0s … 6553.2s / step: 0.1s)";
CM_ SG_ 685 AnalyticsDataFBD_VR_FDD_Success_ "Number of successful rangings with the help of a Final_Data distributed over the bus, and originally received via UWB (range: 0 ... 65532 / step: 1)";
CM_ SG_ 685 AnalyticsDataFBD_VR_FDD_Succes_2 "Number of successful rangings with the help of a Final_Data distributed over the bus, and originally received via BLE (range: 0 ... 65532 / step: 1)";
CM_ SG_ 685 AnalyticsDataFBD_VR_RSSI_New "Number of detected RSSI motion sensing ranging intents that lead to a ranging session resume (range: 0 ... 65532 / step: 1)";
CM_ SG_ 685 AnalyticsDataFBD_VR_RSSI_Cont "Number of detected RSSI motion sensing ranging intents that extended a ranging session (range: 0 ... 65532 / step: 1)";
CM_ SG_ 685 AnalyticsDataFBD_VR_BLE_Localiza "contains localization uptime";
CM_ SG_ 685 AnalyticsDataFBD_VR_BLE_Locali_2 "contains localization count";
CM_ SG_ 685 AnalyticsDataFBD_VR_Fallback_Mod "contains localization count";
CM_ SG_ 607 AnalyticsDataRequest_Address "addressing of the UWB anchors";
CM_ SG_ 607 AnalyticsDataRequest_RequestData "request, activate, deactivate Analytics data";
CM_ SG_ 605 ControlBindingFBD_Address "addressing of the UWB anchors";
CM_ SG_ 605 ControlBindingFBD_BindingSequenc "contains binding sequence";
CM_ SG_ 605 ControlBindingFBD_Data00 "contains Auth. Signal is encrypted, signal TAG not possible";
CM_ SG_ 605 ControlBindingFBD_Data01 "contains Auth. Signal is encrypted, signal TAG not possible";
CM_ SG_ 605 ControlBindingFBD_Data02 "contains Auth. Signal is encrypted, signal TAG not possible";
CM_ SG_ 605 ControlBindingFBD_Data03 "contains Auth. Signal is encrypted, signal TAG not possible";
CM_ SG_ 605 ControlBindingFBD_Data04 "contains Auth. Signal is encrypted, signal TAG not possible";
CM_ SG_ 605 ControlBindingFBD_Data05 "contains Auth. Signal is encrypted, signal TAG not possible";
CM_ SG_ 605 ControlBindingFBD_Data06 "contains Auth. Signal is encrypted, signal TAG not possible";
CM_ SG_ 605 ControlBindingFBD_Data07 "contains Auth. Signal is encrypted, signal TAG not possible";
CM_ SG_ 605 ControlBindingFBD_Data08 "contains Auth. Signal is encrypted, signal TAG not possible";
CM_ SG_ 605 ControlBindingFBD_Data09 "contains Auth. Signal is encrypted, signal TAG not possible";
CM_ SG_ 605 ControlBindingFBD_Data10 "contains Auth. Signal is encrypted, signal TAG not possible";
CM_ SG_ 605 ControlBindingFBD_Data11 "contains Auth. Signal is encrypted, signal TAG not possible";
CM_ SG_ 605 ControlBindingFBD_Data12 "contains Auth. Signal is encrypted, signal TAG not possible";
CM_ SG_ 605 ControlBindingFBD_Data13 "contains Auth. Signal is encrypted, signal TAG not possible";
CM_ SG_ 605 ControlBindingFBD_Data14 "contains Auth. Signal is encrypted, signal TAG not possible";
CM_ SG_ 605 ControlBindingFBD_Data15 "contains Auth. Signal is encrypted, signal TAG not possible";
CM_ SG_ 605 ControlBindingFBD_Data16 "contains Auth. Signal is encrypted, signal TAG not possible";
CM_ SG_ 605 ControlBindingFBD_Data17 "contains Auth. Signal is encrypted, signal TAG not possible";
CM_ SG_ 605 ControlBindingFBD_Data18 "contains Auth. Signal is encrypted, signal TAG not possible";
CM_ SG_ 605 ControlBindingFBD_Data19 "contains Auth. Signal is encrypted, signal TAG not possible";
CM_ SG_ 605 ControlBindingFBD_Data20 "contains Auth. Signal is encrypted, signal TAG not possible";
CM_ SG_ 605 ControlBindingFBD_Data21 "contains Auth. Signal is encrypted, signal TAG not possible";
CM_ SG_ 605 ControlBindingFBD_Data22 "contains Auth. Signal is encrypted, signal TAG not possible";
CM_ SG_ 605 ControlBindingFBD_Data23 "contains Auth. Signal is encrypted, signal TAG not possible";
CM_ SG_ 605 ControlBindingFBD_Data24 "contains Auth. Signal is encrypted, signal TAG not possible";
CM_ SG_ 605 ControlBindingFBD_Data25 "contains Auth. Signal is encrypted, signal TAG not possible";
CM_ SG_ 605 ControlBindingFBD_Data26 "contains Auth. Signal is encrypted, signal TAG not possible";
CM_ SG_ 605 ControlBindingFBD_Data27 "contains Auth. Signal is encrypted, signal TAG not possible";
CM_ SG_ 605 ControlBindingFBD_Data28 "contains Auth. Signal is encrypted, signal TAG not possible";
CM_ SG_ 605 ControlBindingFBD_Data29 "contains Auth. Signal is encrypted, signal TAG not possible";
CM_ SG_ 605 ControlBindingFBD_Data30 "contains Auth. Signal is encrypted, signal TAG not possible";
CM_ SG_ 605 ControlBindingFBD_Data31 "contains Auth. Signal is encrypted, signal TAG not possible";
CM_ SG_ 605 ControlBindingFBD_Data32 "contains Auth. Signal is encrypted, signal TAG not possible";
CM_ SG_ 605 ControlBindingFBD_Data33 "contains Auth. Signal is encrypted, signal TAG not possible";
CM_ SG_ 605 ControlBindingFBD_Data34 "contains Auth. Signal is encrypted, signal TAG not possible";
CM_ SG_ 605 ControlBindingFBD_Data35 "contains Auth. Signal is encrypted, signal TAG not possible";
CM_ SG_ 605 ControlBindingFBD_Data36 "contains Auth. Signal is encrypted, signal TAG not possible";
CM_ SG_ 605 ControlBindingFBD_Data37 "contains Auth. Signal is encrypted, signal TAG not possible";
CM_ SG_ 605 ControlBindingFBD_Data38 "contains Auth. Signal is encrypted, signal TAG not possible";
CM_ SG_ 605 ControlBindingFBD_Data39 "contains Auth. Signal is encrypted, signal TAG not possible";
CM_ SG_ 605 ControlBindingFBD_Data40 "contains Auth. Signal is encrypted, signal TAG not possible";
CM_ SG_ 605 ControlBindingFBD_Data41 "contains Auth. Signal is encrypted, signal TAG not possible";
CM_ SG_ 605 ControlBindingFBD_Data42 "contains Auth. Signal is encrypted, signal TAG not possible";
CM_ SG_ 605 ControlBindingFBD_Data43 "contains Auth. Signal is encrypted, signal TAG not possible";
CM_ SG_ 605 ControlBindingFBD_Data44 "contains Auth. Signal is encrypted, signal TAG not possible";
CM_ SG_ 605 ControlBindingFBD_Data45 "contains Auth. Signal is encrypted, signal TAG not possible";
CM_ SG_ 605 ControlBindingFBD_Data46 "contains Auth. Signal is encrypted, signal TAG not possible";
CM_ SG_ 605 ControlBindingFBD_Data47 "contains Auth. Signal is encrypted, signal TAG not possible";
CM_ SG_ 605 ControlBindingFBD_Data48 "contains Auth. Signal is encrypted, signal TAG not possible";
CM_ SG_ 605 ControlBindingFBD_Data49 "contains Auth. Signal is encrypted, signal TAG not possible";
CM_ SG_ 605 ControlBindingFBD_Data50 "contains Auth. Signal is encrypted, signal TAG not possible";
CM_ SG_ 605 ControlBindingFBD_Data51 "contains Auth. Signal is encrypted, signal TAG not possible";
CM_ SG_ 605 ControlBindingFBD_Data52 "contains Auth. Signal is encrypted, signal TAG not possible";
CM_ SG_ 605 ControlBindingFBD_Data53 "contains Auth. Signal is encrypted, signal TAG not possible";
CM_ SG_ 605 ControlBindingFBD_Data54 "contains Auth. Signal is encrypted, signal TAG not possible";
CM_ SG_ 605 ControlBindingFBD_Data55 "contains Auth. Signal is encrypted, signal TAG not possible";
CM_ SG_ 605 ControlBindingFBD_Data56 "contains Auth. Signal is encrypted, signal TAG not possible";
CM_ SG_ 605 ControlBindingFBD_Data57 "contains Auth. Signal is encrypted, signal TAG not possible";
CM_ SG_ 605 ControlBindingFBD_Data58 "contains Auth. Signal is encrypted, signal TAG not possible";
CM_ SG_ 605 ControlBindingFBD_Data59 "contains Auth. Signal is encrypted, signal TAG not possible";
CM_ SG_ 605 ControlBindingFBD_Data60 "contains Auth. Signal is encrypted, signal TAG not possible";
CM_ SG_ 245 ControlBLEConnectionMonitoring_A "addressing of the BLE nodes";
CM_ SG_ 245 ControlBLEConnectionMonitoring_B "active BLE nodes for connection monitoring";
CM_ SG_ 245 ControlBLEConnectionMonitoring_I "contains ConnectionID";
CM_ SG_ 245 ControlBLEConnectionMonitoring_M "activation/deactivation of connection monitoring";
CM_ SG_ 245 ControlBLEConnectionMonitoring_2 "The cycle time of sending the RSSI raw values to IPB for a connection identified with IRKListID (range: 0ms…2520ms/ step: 10ms)";
CM_ SG_ 383 ControlBLECS_Address "addressing of the BLE nodes";
CM_ SG_ 383 ControlBLECS_SessionID "defines the channel sounding session ID within the active connection";
CM_ SG_ 383 ControlBLECS_IRKListID "defines the connected BLE device";
CM_ SG_ 383 ControlBLECS_DeviceGroup "defines the device group";
CM_ SG_ 383 ControlBLECS_Algorithm "Channel Sounding Algorithm";
CM_ SG_ 383 ControlBLECS_DistanceOffset "Constant offset due to RF front end (RFFE)";
CM_ SG_ 383 ControlBLECS_AntennaConfig "defines antenna configuration";
CM_ SG_ 383 ControlBLECS_TxPower "defines tx power for channel sounding (10dBm by Default)";
CM_ SG_ 383 ControlBLECS_Role "defines the role of the receiver";
CM_ SG_ 383 ControlBLECS_ProcedureResultsTra "controls sending of procedure results";
CM_ SG_ 383 ControlBLECS_AntennaPathProcedur "defines the antenna path which is included in procedure results (Bit0 is antenna path 1, Bit1 is antenna path 2, Bit2 is antenna path 3, Bit3 is antenna path 4)";
CM_ SG_ 383 ControlBLECS_FBDonlyThreshold "distance threshold based on BLE channel sounding";
CM_ SG_ 383 ControlBLECS_InlinePCT "defines if inline PCT is activated on the FBD side. Only relevant in case of reflector role";
CM_ SG_ 608 ControlBLEDeviceName_Address "addressing of the UWB anchors";
CM_ SG_ 608 ControlBLEDeviceName_Character00 "contains 1st character of BLE device name";
CM_ SG_ 608 ControlBLEDeviceName_Character01 "contains 2nd character of BLE device name";
CM_ SG_ 608 ControlBLEDeviceName_Character02 "contains 3rd character of BLE device name";
CM_ SG_ 608 ControlBLEDeviceName_Character03 "contains 4th character of BLE device name";
CM_ SG_ 608 ControlBLEDeviceName_Character04 "contains 5th character of BLE device name";
CM_ SG_ 608 ControlBLEDeviceName_Character05 "contains 6th character of BLE device name";
CM_ SG_ 608 ControlBLEDeviceName_Character06 "contains 7th character of BLE device name";
CM_ SG_ 608 ControlBLEDeviceName_Character07 "contains 8th character of BLE device name";
CM_ SG_ 608 ControlBLEDeviceName_Character08 "contains 9th character of BLE device name";
CM_ SG_ 608 ControlBLEDeviceName_Character09 "contains 10th character of BLE device name";
CM_ SG_ 608 ControlBLEDeviceName_Character10 "contains 11th character of BLE device name";
CM_ SG_ 608 ControlBLEDeviceName_Character11 "contains 12th character of BLE device name";
CM_ SG_ 608 ControlBLEDeviceName_Character12 "contains 13th character of BLE device name";
CM_ SG_ 608 ControlBLEDeviceName_Character13 "contains 14th character of BLE device name";
CM_ SG_ 608 ControlBLEDeviceName_Character14 "contains 15th character of BLE device name";
CM_ SG_ 608 ControlBLEDeviceName_Character15 "contains 16th character of BLE device name";
CM_ SG_ 608 ControlBLEDeviceName_Character16 "contains 17th character of BLE device name";
CM_ SG_ 608 ControlBLEDeviceName_Character17 "contains 18th character of BLE device name";
CM_ SG_ 608 ControlBLEDeviceName_Character18 "contains 19th character of BLE device name";
CM_ SG_ 608 ControlBLEDeviceName_Character19 "contains 20th character of BLE device name";
CM_ SG_ 608 ControlBLEDeviceName_Character20 "contains 21st character of BLE device name";
CM_ SG_ 608 ControlBLEDeviceName_Character21 "contains 22nd character of BLE device name";
CM_ SG_ 608 ControlBLEDeviceName_Character22 "contains 23rd character of BLE device name";
CM_ SG_ 608 ControlBLEDeviceName_Character23 "contains 24th character of BLE device name";
CM_ SG_ 608 ControlBLEDeviceName_Character24 "contains 25th character of BLE device name";
CM_ SG_ 608 ControlBLEDeviceName_Character25 "contains 26th character of BLE device name";
CM_ SG_ 608 ControlBLEDeviceName_Character26 "contains 27th character of BLE device name";
CM_ SG_ 608 ControlBLEDeviceName_Character27 "contains 28th character of BLE device name";
CM_ SG_ 608 ControlBLEDeviceName_Character28 "contains 29th character of BLE device name";
CM_ SG_ 608 ControlBLEDeviceName_Character29 "contains 30th character of BLE device name";
CM_ SG_ 200 ControlBLEInitialSettings_Addres "addressing of the BLE TRX";
CM_ SG_ 200 ControlBLEInitialSettings_BLEOpe "Set the BLE operation mode";
CM_ SG_ 200 ControlBLEInitialSettings_Advert "Set the advertising interval in case advertising is active";
CM_ SG_ 200 ControlBLEInitialSettings_ScanWi "Set the scanning parameters in case scanning is active";
CM_ SG_ 200 ControlBLEInitialSettings_enable "Activate or deactivate LELR mode";
CM_ SG_ 200 ControlBLEInitialSettings_SetBLE "Set the LELR mode in case it is active";
CM_ SG_ 200 ControlBLEInitialSettings_LR500_ "Set the advertising interval for LELR 500Kb in case advertising is active";
CM_ SG_ 200 ControlBLEInitialSettings_LR125_ "Set the advertising interval for LELR 125Kb in case advertising is active";
CM_ SG_ 200 ControlBLEInitialSettings_Enable "Activate or deactivate extended advertising";
CM_ SG_ 200 ControlBLEInitialSettings_SetTxP "Set The Tx power";
CM_ SG_ 200 ControlBLEInitialSettings_SetPSM "Set PSM for L2CAP connection oriented channel";
CM_ SG_ 200 ControlBLEInitialSettings_SetRPA "Set the frequency of RPA change";
CM_ SG_ 200 ControlBLEInitialSettings_SetDCK "Set the protocol version of DCK system according to CCC specification";
CM_ SG_ 200 ControlBLEInitialSettings_SetSca "Set the BLE scan request mode";
CM_ SG_ 209 ControlBLERSSIRangingIntent_Addr "addressing of the UWB anchors";
CM_ SG_ 209 ControlBLERSSIRangingIntent_Acti "activate/deactivate function RSSI based ranging intent";
CM_ SG_ 209 ControlBLERSSIRangingIntent_Movi "Time in ms (Range: 0ms ... 65532ms / step: 1ms)";
CM_ SG_ 209 ControlBLERSSIRangingIntent_FBD_ "number of consecutive increasing RSSI measurements";
CM_ SG_ 209 ControlBLERSSIRangingIntent_Mult "contaíns multi RSSI Intent";
CM_ SG_ 209 ControlBLERSSIRangingIntent_IRKL "contains IRK List ID";
CM_ SG_ 209 ControlBLERSSIRangingIntent_BLEN "contains BLE Nodes";
CM_ SG_ 209 ControlBLERSSIRangingIntent_MinN "contains minimum number of anchors for ranging intent";
CM_ SG_ 209 ControlBLERSSIRangingIntent_Devi "contains device group setting";
CM_ SG_ 248 ControlBLESeamlessSettings_Addre "addressing of the UWB anchors";
CM_ SG_ 248 ControlBLESeamlessSettings_Activ "acivate or deactivate seamless BLE handover";
CM_ SG_ 248 ControlBLESeamlessSettings_Numbe "defines the number of samples for RSSI averaging";
CM_ SG_ 248 ControlBLESeamlessSettings_RSSIT "defines the RSSI threeshold (Range: -127 ... -1 dB / step: 0.5dB)";
CM_ SG_ 248 ControlBLESeamlessSettings_RSSID "defines the minimum RSSI difference (Range: 0 ... 127 dB / step: 0.5dB)";
CM_ SG_ 248 ControlBLESeamlessSettings_Timeo "defines max time delay until handover must be finished (range: 0ms ... 252ms / step: 1ms)";
CM_ SG_ 201 ControlBLESettingsChange_Address "addressing of the BLE TRX";
CM_ SG_ 201 ControlBLESettingsChange_Disconn "Disconnect the connected device";
CM_ SG_ 201 ControlBLESettingsChange_SetConn "Set BLE connection interval";
CM_ SG_ 201 ControlBLESettingsChange_SetCo_2 "Set BLE connection supervision timeout";
CM_ SG_ 247 ControlBLESettingsPriority_Addre "addressing of the UWB anchors";
CM_ SG_ 247 ControlBLESettingsPriority_Conne "contains ConnectionID";
CM_ SG_ 247 ControlBLESettingsPriority_Level "contains priority level to connection";
CM_ SG_ 208 ControlBLEThirdParty_Address "addressing of the BLE TRX";
CM_ SG_ 208 ControlBLEThirdParty_DisableThir "Disable advertising for third Party";
CM_ SG_ 208 ControlBLEThirdParty_ResquestThi "Request logging data for third party";
CM_ SG_ 208 ControlBLEThirdParty_RequestThir "Request connection settings for third party";
CM_ SG_ 208 ControlBLEThirdParty_EnablePaylo "Activate or deactivate payload filtering";
CM_ SG_ 208 ControlBLEThirdParty_SetScanning "Activate scanninng for third party";
CM_ SG_ 600 ControlConfigurationFBD_Address "addressing of the UWB anchors";
CM_ SG_ 600 ControlConfigurationFBD_DeviceGr "contains device group setting";
CM_ SG_ 600 ControlConfigurationFBD_IRKListI "contains IRK list ID";
CM_ SG_ 600 ControlConfigurationFBD_RSSIRang "contains a Ranging Intent Play Protection; maximum RSSI motion sensing ranging activations per 5 minutes (ranging session independent) in FBD_Only_Mode";
CM_ SG_ 600 ControlConfigurationFBD_RSSIRa_2 "contains the Ranging Intent Maximum; maximum RSSI motion sensing ranging activations per ranging session in FBD_Only_Mode";
CM_ SG_ 600 ControlConfigurationFBD_FBD_Only "set UWB diversity mode";
CM_ SG_ 600 ControlConfigurationFBD_UWBDutyC "set maximal UWB duty cycle limit per sec (Range: 0 ... 126ms / step: 0,5ms)";
CM_ SG_ 600 ControlConfigurationFBD_UWBDut_2 "contains setting of maximal UWB duty cycle limit per hour (Range: 0 ... 25,2s / step: 0,1s)";
CM_ SG_ 600 ControlConfigurationFBD_UWBDut_3 "contains setting of maximal UWB duty cycle limit per second on average (Range: 0 ... 126ms / step: 0,5ms)";
CM_ SG_ 600 ControlConfigurationFBD_FBDonlyW "set distance to the vehicle a FBD shall trigger CCU wake-up (range: 0m ... 25.2m / step: 0.1m)";
CM_ SG_ 600 ControlConfigurationFBD_FBDonlyR "set ranging intent threshold in FBD-only mode (categorical: low, medium, high)";
CM_ SG_ 600 ControlConfigurationFBD_FBDonl_2 "contains setting of ranging intent threshold in FBD-only mode";
CM_ SG_ 600 ControlConfigurationFBD_FBDonl_3 "set ranging session uptime extension in seconds (range: 0s ... 252s / step: 1s)";
CM_ SG_ 600 ControlConfigurationFBD_FBDonl_4 "contains ranging session suspension timeout (invalid rangings) in seconds (range: 0s ... 252s / step: 1s)";
CM_ SG_ 600 ControlConfigurationFBD_FBDonl_5 "contains maximum ranging session uptime in seconds (range: 0s ... 252s / step: 1s)";
CM_ SG_ 600 ControlConfigurationFBD_FBDonl_6 "contains maximum total ranging uptime over all ranging sessions (range: 0min ... 252min / step: 1min)";
CM_ SG_ 600 ControlConfigurationFBD_FBDonl_7 "contains RAN multiplier for resuming ranging sessions (range: 1 ... 255 / step: 1)";
CM_ SG_ 600 ControlConfigurationFBD_FBDonlyD "contains activity state of analytics data collection from customer fleet about feature usage";
CM_ SG_ 604 ControlCoordinatesCAR_Address "addressing of the UWB anchors";
CM_ SG_ 604 ControlCoordinatesCAR_BodyFrontL "CoordinatesFBD6 (Range: -250cm ... 770cm / step: 1cm)";
CM_ SG_ 604 ControlCoordinatesCAR_BodyFron_2 "CoordinatesFBD6 (Range: -250cm ... 770cm / step: 1cm)";
CM_ SG_ 604 ControlCoordinatesCAR_BodyRearRi "CoordinatesFBD6 (Range: -250cm ... 770cm / step: 1cm)";
CM_ SG_ 604 ControlCoordinatesCAR_BodyRear_2 "CoordinatesFBD6 (Range: -250cm ... 770cm / step: 1cm)";
CM_ SG_ 603 ControlCoordinatesFBD_Address "addressing of the UWB anchors";
CM_ SG_ 603 ControlCoordinatesFBD_VM_X "CoordinatesFBD6 (Range: -250cm ... 770cm / step: 1cm)";
CM_ SG_ 603 ControlCoordinatesFBD_VM_Y "CoordinatesFBD6 (Range: -250cm ... 770cm / step: 1cm)";
CM_ SG_ 603 ControlCoordinatesFBD_VM_Z "CoordinatesFBD6 (Range: -250cm ... 770cm / step: 1cm)";
CM_ SG_ 603 ControlCoordinatesFBD_VM_azimuth "AzimuthFB6 (Range: -180° ... 180° / step: 1°)";
CM_ SG_ 603 ControlCoordinatesFBD_VM_elevati "ElevationFBD6 (Range: -100 ... 100° / step: 1°)";
CM_ SG_ 603 ControlCoordinatesFBD_HM_X "CoordinatesFBD6 (Range: -250cm ... 770cm / step: 1cm)";
CM_ SG_ 603 ControlCoordinatesFBD_HM_Y "CoordinatesFBD6 (Range: -250cm ... 770cm / step: 1cm)";
CM_ SG_ 603 ControlCoordinatesFBD_HM_Z "CoordinatesFBD6 (Range: -250cm ... 770cm / step: 1cm)";
CM_ SG_ 603 ControlCoordinatesFBD_HM_azimuth "AzimuthFB6 (Range: -180° ... 180° / step: 1°)";
CM_ SG_ 603 ControlCoordinatesFBD_HM_elevati "ElevationFBD6 (Range: -100 ... 100° / step: 1°)";
CM_ SG_ 603 ControlCoordinatesFBD_Miko_X "CoordinatesFBD6 (Range: -250cm ... 770cm / step: 1cm)";
CM_ SG_ 603 ControlCoordinatesFBD_Miko_Y "CoordinatesFBD6 (Range: -250cm ... 770cm / step: 1cm)";
CM_ SG_ 603 ControlCoordinatesFBD_Miko_Z "CoordinatesFBD6 (Range: -250cm ... 770cm / step: 1cm)";
CM_ SG_ 603 ControlCoordinatesFBD_Miko_azimu "AzimuthFB6 (Range: -180° ... 180° / step: 1°)";
CM_ SG_ 603 ControlCoordinatesFBD_Miko_eleva "ElevationFBD6 (Range: -100 ... 100° / step: 1°)";
CM_ SG_ 603 ControlCoordinatesFBD_Trunk_X "CoordinatesFBD6 (Range: -250cm ... 770cm / step: 1cm)";
CM_ SG_ 603 ControlCoordinatesFBD_Trunk_Y "CoordinatesFBD6 (Range: -250cm ... 770cm / step: 1cm)";
CM_ SG_ 603 ControlCoordinatesFBD_Trunk_Z "CoordinatesFBD6 (Range: -250cm ... 770cm / step: 1cm)";
CM_ SG_ 603 ControlCoordinatesFBD_Trunk_azim "AzimuthFB6 (Range: -180° ... 180° / step: 1°)";
CM_ SG_ 603 ControlCoordinatesFBD_Trunk_elev "ElevationFBD6 (Range: -100 ... 100° / step: 1°)";
CM_ SG_ 603 ControlCoordinatesFBD_VL_X "CoordinatesFBD6 (Range: -250cm ... 770cm / step: 1cm)";
CM_ SG_ 603 ControlCoordinatesFBD_VL_Y "CoordinatesFBD6 (Range: -250cm ... 770cm / step: 1cm)";
CM_ SG_ 603 ControlCoordinatesFBD_VL_Z "CoordinatesFBD6 (Range: -250cm ... 770cm / step: 1cm)";
CM_ SG_ 603 ControlCoordinatesFBD_VL_azimuth "AzimuthFB6 (Range: -180° ... 180° / step: 1°)";
CM_ SG_ 603 ControlCoordinatesFBD_VL_elevati "ElevationFBD6 (Range: -100 ... 100° / step: 1°)";
CM_ SG_ 603 ControlCoordinatesFBD_VR_X "CoordinatesFBD6 (Range: -250cm ... 770cm / step: 1cm)";
CM_ SG_ 603 ControlCoordinatesFBD_VR_Y "CoordinatesFBD6 (Range: -250cm ... 770cm / step: 1cm)";
CM_ SG_ 603 ControlCoordinatesFBD_VR_Z "CoordinatesFBD6 (Range: -250cm ... 770cm / step: 1cm)";
CM_ SG_ 603 ControlCoordinatesFBD_VR_azimuth "AzimuthFB6 (Range: -180° ... 180° / step: 1°)";
CM_ SG_ 603 ControlCoordinatesFBD_VR_elevati "ElevationFBD6 (Range: -100 ... 100° / step: 1°)";
CM_ SG_ 603 ControlCoordinatesFBD_HL_X "CoordinatesFBD6 (Range: -250cm ... 770cm / step: 1cm)";
CM_ SG_ 603 ControlCoordinatesFBD_HL_Y "CoordinatesFBD6 (Range: -250cm ... 770cm / step: 1cm)";
CM_ SG_ 603 ControlCoordinatesFBD_HL_Z "CoordinatesFBD6 (Range: -250cm ... 770cm / step: 1cm)";
CM_ SG_ 603 ControlCoordinatesFBD_HL_azimuth "AzimuthFB6 (Range: -180° ... 180° / step: 1°)";
CM_ SG_ 603 ControlCoordinatesFBD_HL_elevati "ElevationFBD6 (Range: -100 ... 100° / step: 1°)";
CM_ SG_ 603 ControlCoordinatesFBD_HR_X "CoordinatesFBD6 (Range: -250cm ... 770cm / step: 1cm)";
CM_ SG_ 603 ControlCoordinatesFBD_HR_Y "CoordinatesFBD6 (Range: -250cm ... 770cm / step: 1cm)";
CM_ SG_ 603 ControlCoordinatesFBD_HR_Z "CoordinatesFBD6 (Range: -250cm ... 770cm / step: 1cm)";
CM_ SG_ 603 ControlCoordinatesFBD_HR_azimuth "AzimuthFB6 (Range: -180° ... 180° / step: 1°)";
CM_ SG_ 603 ControlCoordinatesFBD_HR_elevati "ElevationFBD6 (Range: -100 ... 100° / step: 1°)";
CM_ SG_ 603 ControlCoordinatesFBD_SML_X "CoordinatesFBD6 (Range: -250cm ... 770cm / step: 1cm)";
CM_ SG_ 603 ControlCoordinatesFBD_SML_Y "CoordinatesFBD6 (Range: -250cm ... 770cm / step: 1cm)";
CM_ SG_ 603 ControlCoordinatesFBD_SML_Z "CoordinatesFBD6 (Range: -250cm ... 770cm / step: 1cm)";
CM_ SG_ 603 ControlCoordinatesFBD_SML_azimut "AzimuthFB6 (Range: -180° ... 180° / step: 1°)";
CM_ SG_ 603 ControlCoordinatesFBD_SML_elevat "ElevationFBD6 (Range: -100 ... 100° / step: 1°)";
CM_ SG_ 603 ControlCoordinatesFBD_SMR_X "CoordinatesFBD6 (Range: -250cm ... 770cm / step: 1cm)";
CM_ SG_ 603 ControlCoordinatesFBD_SMR_Y "CoordinatesFBD6 (Range: -250cm ... 770cm / step: 1cm)";
CM_ SG_ 603 ControlCoordinatesFBD_SMR_Z "CoordinatesFBD6 (Range: -250cm ... 770cm / step: 1cm)";
CM_ SG_ 603 ControlCoordinatesFBD_SMR_azimut "AzimuthFB6 (Range: -180° ... 180° / step: 1°)";
CM_ SG_ 603 ControlCoordinatesFBD_SMR_elevat "ElevationFBD6 (Range: -100 ... 100° / step: 1°)";
CM_ SG_ 302 ControlCPDSession_Address "addressing of the UWB anchors";
CM_ SG_ 302 ControlCPDSession_Command "start, stop a CPD session";
CM_ SG_ 302 ControlCPDSession_SensitivityBoo "defines Sensitivity Boost";
CM_ SG_ 302 ControlCPDSession_CycleTime "defines Cycle Time of CPD session. For not defined values the cycle time of 96 ms shall be used as default.";
CM_ SG_ 302 ControlCPDSession_Channel "defines used Channels of CPD session";
CM_ SG_ 302 ControlCPDSession_NoiseSuppressi "defines usage of RadarNoiseSuppression-Function";
CM_ SG_ 302 ControlCPDSession_SessionPriorit "definition of parameter";
CM_ SG_ 302 ControlCPDSession_Sign "signature of telegram, only signal TAG 0xFF possible";
CM_ SG_ 302 ControlCPDSession_Data00 "signal is encrypted, signal TAG not possible";
CM_ SG_ 302 ControlCPDSession_Data01 "signal is encrypted, signal TAG not possible";
CM_ SG_ 302 ControlCPDSession_Data02 "signal is encrypted, signal TAG not possible";
CM_ SG_ 302 ControlCPDSession_Data03 "signal is encrypted, signal TAG not possible";
CM_ SG_ 302 ControlCPDSession_Data04 "signal is encrypted, signal TAG not possible";
CM_ SG_ 302 ControlCPDSession_Data05 "signal is encrypted, signal TAG not possible";
CM_ SG_ 302 ControlCPDSession_Data06 "signal is encrypted, signal TAG not possible";
CM_ SG_ 302 ControlCPDSession_Data07 "signal is encrypted, signal TAG not possible";
CM_ SG_ 140 ControlFBD_Address "addressing of the UWB anchors";
CM_ SG_ 140 ControlFBD_PowerMode "set power mode of FBD";
CM_ SG_ 140 ControlFBD_RequestStatus "request actual status of FBD";
CM_ SG_ 140 ControlFBD_ResetFBD "force reset of FBD";
CM_ SG_ 140 ControlFBD_ResetFBDStatus "force reset of StatusData (counter)";
CM_ SG_ 140 ControlFBD_SetCyclicStatus "set cyclic status transmission of FBD (value in sec, 0=off)";
CM_ SG_ 140 ControlFBD_OptionCode "addressing of the UWB anchors";
CM_ SG_ 402 ControlRangingSession_Address "addressing of the UWB anchors";
CM_ SG_ 402 ControlRangingSession_Function "Start, Stop, Suspend, Resume, Delete a Session";
CM_ SG_ 402 ControlRangingSession_SessionIDS "definition of Session-ID";
CM_ SG_ 402 ControlRangingSession_STSIndex "contains STS-Index";
CM_ SG_ 402 ControlRangingSession_RANmultipl "set RAN multiplier of ranging session";
CM_ SG_ 402 ControlRangingSession_UWBTime0 "Time-sync information";
CM_ SG_ 400 ControlRangingSessionSetup1_Addr "addressing of the UWB anchors";
CM_ SG_ 400 ControlRangingSessionSetup1_Sess "definition of Session-ID";
CM_ SG_ 400 ControlRangingSessionSetup1_Conf "length of RangingSessionSetup";
CM_ SG_ 400 ControlRangingSessionSetup1_Co_2 "definition of action";
CM_ SG_ 400 ControlRangingSessionSetup1_Auto "defines start of UWB ranging with reception of RangingSessionSetup";
CM_ SG_ 400 ControlRangingSessionSetup1_Bitm "Bitmask of built-in FBD6 anchors";
CM_ SG_ 400 ControlRangingSessionSetup1_Prot "definition of protocol content";
CM_ SG_ 400 ControlRangingSessionSetup1_Data "signal is encrypted, signal TAG not possible";
CM_ SG_ 400 ControlRangingSessionSetup1_Da_2 "signal is encrypted, signal TAG not possible";
CM_ SG_ 400 ControlRangingSessionSetup1_Da_3 "signal is encrypted, signal TAG not possible";
CM_ SG_ 400 ControlRangingSessionSetup1_Da_4 "signal is encrypted, signal TAG not possible";
CM_ SG_ 400 ControlRangingSessionSetup1_Da_5 "signal is encrypted, signal TAG not possible";
CM_ SG_ 400 ControlRangingSessionSetup1_Da_6 "signal is encrypted, signal TAG not possible";
CM_ SG_ 400 ControlRangingSessionSetup1_Da_7 "signal is encrypted, signal TAG not possible";
CM_ SG_ 400 ControlRangingSessionSetup1_Da_8 "signal is encrypted, signal TAG not possible";
CM_ SG_ 400 ControlRangingSessionSetup1_Da_9 "signal is encrypted, signal TAG not possible";
CM_ SG_ 400 ControlRangingSessionSetup1_D_10 "signal is encrypted, signal TAG not possible";
CM_ SG_ 400 ControlRangingSessionSetup1_D_11 "signal is encrypted, signal TAG not possible";
CM_ SG_ 400 ControlRangingSessionSetup1_D_12 "signal is encrypted, signal TAG not possible";
CM_ SG_ 400 ControlRangingSessionSetup1_D_13 "signal is encrypted, signal TAG not possible";
CM_ SG_ 400 ControlRangingSessionSetup1_D_14 "signal is encrypted, signal TAG not possible";
CM_ SG_ 400 ControlRangingSessionSetup1_D_15 "signal is encrypted, signal TAG not possible";
CM_ SG_ 400 ControlRangingSessionSetup1_D_16 "signal is encrypted, signal TAG not possible";
CM_ SG_ 400 ControlRangingSessionSetup1_D_17 "signal is encrypted, signal TAG not possible";
CM_ SG_ 400 ControlRangingSessionSetup1_D_18 "signal is encrypted, signal TAG not possible";
CM_ SG_ 400 ControlRangingSessionSetup1_D_19 "signal is encrypted, signal TAG not possible";
CM_ SG_ 400 ControlRangingSessionSetup1_D_20 "signal is encrypted, signal TAG not possible";
CM_ SG_ 400 ControlRangingSessionSetup1_D_21 "signal is encrypted, signal TAG not possible";
CM_ SG_ 400 ControlRangingSessionSetup1_D_22 "signal is encrypted, signal TAG not possible";
CM_ SG_ 400 ControlRangingSessionSetup1_D_23 "signal is encrypted, signal TAG not possible";
CM_ SG_ 400 ControlRangingSessionSetup1_D_24 "signal is encrypted, signal TAG not possible";
CM_ SG_ 400 ControlRangingSessionSetup1_D_25 "signal is encrypted, signal TAG not possible";
CM_ SG_ 400 ControlRangingSessionSetup1_D_26 "signal is encrypted, signal TAG not possible";
CM_ SG_ 400 ControlRangingSessionSetup1_D_27 "signal is encrypted, signal TAG not possible";
CM_ SG_ 400 ControlRangingSessionSetup1_D_28 "signal is encrypted, signal TAG not possible";
CM_ SG_ 400 ControlRangingSessionSetup1_D_29 "signal is encrypted, signal TAG not possible";
CM_ SG_ 400 ControlRangingSessionSetup1_D_30 "signal is encrypted, signal TAG not possible";
CM_ SG_ 400 ControlRangingSessionSetup1_D_31 "signal is encrypted, signal TAG not possible";
CM_ SG_ 400 ControlRangingSessionSetup1_D_32 "signal is encrypted, signal TAG not possible";
CM_ SG_ 400 ControlRangingSessionSetup1_D_33 "signal is encrypted, signal TAG not possible";
CM_ SG_ 400 ControlRangingSessionSetup1_D_34 "signal is encrypted, signal TAG not possible";
CM_ SG_ 400 ControlRangingSessionSetup1_D_35 "signal is encrypted, signal TAG not possible";
CM_ SG_ 400 ControlRangingSessionSetup1_D_36 "signal is encrypted, signal TAG not possible";
CM_ SG_ 400 ControlRangingSessionSetup1_D_37 "signal is encrypted, signal TAG not possible";
CM_ SG_ 400 ControlRangingSessionSetup1_D_38 "signal is encrypted, signal TAG not possible";
CM_ SG_ 400 ControlRangingSessionSetup1_D_39 "signal is encrypted, signal TAG not possible";
CM_ SG_ 400 ControlRangingSessionSetup1_D_40 "signal is encrypted, signal TAG not possible";
CM_ SG_ 400 ControlRangingSessionSetup1_D_41 "signal is encrypted, signal TAG not possible";
CM_ SG_ 400 ControlRangingSessionSetup1_D_42 "signal is encrypted, signal TAG not possible";
CM_ SG_ 400 ControlRangingSessionSetup1_D_43 "signal is encrypted, signal TAG not possible";
CM_ SG_ 400 ControlRangingSessionSetup1_D_44 "signal is encrypted, signal TAG not possible";
CM_ SG_ 400 ControlRangingSessionSetup1_D_45 "signal is encrypted, signal TAG not possible";
CM_ SG_ 400 ControlRangingSessionSetup1_D_46 "signal is encrypted, signal TAG not possible";
CM_ SG_ 400 ControlRangingSessionSetup1_D_47 "signal is encrypted, signal TAG not possible";
CM_ SG_ 400 ControlRangingSessionSetup1_D_48 "signal is encrypted, signal TAG not possible";
CM_ SG_ 400 ControlRangingSessionSetup1_D_49 "signal is encrypted, signal TAG not possible";
CM_ SG_ 400 ControlRangingSessionSetup1_D_50 "signal is encrypted, signal TAG not possible";
CM_ SG_ 400 ControlRangingSessionSetup1_D_51 "signal is encrypted, signal TAG not possible";
CM_ SG_ 400 ControlRangingSessionSetup1_D_52 "signal is encrypted, signal TAG not possible";
CM_ SG_ 400 ControlRangingSessionSetup1_D_53 "signal is encrypted, signal TAG not possible";
CM_ SG_ 401 ControlRangingSessionSetup2_Addr "addressing of the UWB anchors";
CM_ SG_ 401 ControlRangingSessionSetup2_Sess "definition of Session-ID";
CM_ SG_ 401 ControlRangingSessionSetup2_Data "signal is encrypted, signal TAG not possible";
CM_ SG_ 401 ControlRangingSessionSetup2_Da_2 "signal is encrypted, signal TAG not possible";
CM_ SG_ 401 ControlRangingSessionSetup2_Da_3 "signal is encrypted, signal TAG not possible";
CM_ SG_ 401 ControlRangingSessionSetup2_Da_4 "signal is encrypted, signal TAG not possible";
CM_ SG_ 401 ControlRangingSessionSetup2_Da_5 "signal is encrypted, signal TAG not possible";
CM_ SG_ 401 ControlRangingSessionSetup2_Da_6 "signal is encrypted, signal TAG not possible";
CM_ SG_ 401 ControlRangingSessionSetup2_Da_7 "signal is encrypted, signal TAG not possible";
CM_ SG_ 401 ControlRangingSessionSetup2_Da_8 "signal is encrypted, signal TAG not possible";
CM_ SG_ 401 ControlRangingSessionSetup2_Da_9 "signal is encrypted, signal TAG not possible";
CM_ SG_ 401 ControlRangingSessionSetup2_D_10 "signal is encrypted, signal TAG not possible";
CM_ SG_ 401 ControlRangingSessionSetup2_D_11 "signal is encrypted, signal TAG not possible";
CM_ SG_ 401 ControlRangingSessionSetup2_D_12 "signal is encrypted, signal TAG not possible";
CM_ SG_ 401 ControlRangingSessionSetup2_D_13 "signal is encrypted, signal TAG not possible";
CM_ SG_ 401 ControlRangingSessionSetup2_D_14 "signal is encrypted, signal TAG not possible";
CM_ SG_ 401 ControlRangingSessionSetup2_D_15 "signal is encrypted, signal TAG not possible";
CM_ SG_ 401 ControlRangingSessionSetup2_D_16 "signal is encrypted, signal TAG not possible";
CM_ SG_ 401 ControlRangingSessionSetup2_D_17 "signal is encrypted, signal TAG not possible";
CM_ SG_ 401 ControlRangingSessionSetup2_D_18 "signal is encrypted, signal TAG not possible";
CM_ SG_ 401 ControlRangingSessionSetup2_D_19 "signal is encrypted, signal TAG not possible";
CM_ SG_ 401 ControlRangingSessionSetup2_D_20 "signal is encrypted, signal TAG not possible";
CM_ SG_ 401 ControlRangingSessionSetup2_D_21 "signal is encrypted, signal TAG not possible";
CM_ SG_ 401 ControlRangingSessionSetup2_D_22 "signal is encrypted, signal TAG not possible";
CM_ SG_ 401 ControlRangingSessionSetup2_D_23 "signal is encrypted, signal TAG not possible";
CM_ SG_ 401 ControlRangingSessionSetup2_D_24 "signal is encrypted, signal TAG not possible";
CM_ SG_ 401 ControlRangingSessionSetup2_D_25 "signal is encrypted, signal TAG not possible";
CM_ SG_ 401 ControlRangingSessionSetup2_D_26 "signal is encrypted, signal TAG not possible";
CM_ SG_ 401 ControlRangingSessionSetup2_D_27 "signal is encrypted, signal TAG not possible";
CM_ SG_ 401 ControlRangingSessionSetup2_D_28 "signal is encrypted, signal TAG not possible";
CM_ SG_ 401 ControlRangingSessionSetup2_D_29 "signal is encrypted, signal TAG not possible";
CM_ SG_ 401 ControlRangingSessionSetup2_D_30 "signal is encrypted, signal TAG not possible";
CM_ SG_ 401 ControlRangingSessionSetup2_D_31 "signal is encrypted, signal TAG not possible";
CM_ SG_ 401 ControlRangingSessionSetup2_D_32 "signal is encrypted, signal TAG not possible";
CM_ SG_ 401 ControlRangingSessionSetup2_D_33 "signal is encrypted, signal TAG not possible";
CM_ SG_ 401 ControlRangingSessionSetup2_D_34 "signal is encrypted, signal TAG not possible";
CM_ SG_ 401 ControlRangingSessionSetup2_D_35 "signal is encrypted, signal TAG not possible";
CM_ SG_ 401 ControlRangingSessionSetup2_D_36 "signal is encrypted, signal TAG not possible";
CM_ SG_ 401 ControlRangingSessionSetup2_D_37 "signal is encrypted, signal TAG not possible";
CM_ SG_ 401 ControlRangingSessionSetup2_D_38 "signal is encrypted, signal TAG not possible";
CM_ SG_ 401 ControlRangingSessionSetup2_D_39 "signal is encrypted, signal TAG not possible";
CM_ SG_ 401 ControlRangingSessionSetup2_D_40 "signal is encrypted, signal TAG not possible";
CM_ SG_ 401 ControlRangingSessionSetup2_D_41 "signal is encrypted, signal TAG not possible";
CM_ SG_ 401 ControlRangingSessionSetup2_D_42 "signal is encrypted, signal TAG not possible";
CM_ SG_ 401 ControlRangingSessionSetup2_D_43 "signal is encrypted, signal TAG not possible";
CM_ SG_ 401 ControlRangingSessionSetup2_D_44 "signal is encrypted, signal TAG not possible";
CM_ SG_ 401 ControlRangingSessionSetup2_D_45 "signal is encrypted, signal TAG not possible";
CM_ SG_ 401 ControlRangingSessionSetup2_D_46 "signal is encrypted, signal TAG not possible";
CM_ SG_ 401 ControlRangingSessionSetup2_D_47 "signal is encrypted, signal TAG not possible";
CM_ SG_ 401 ControlRangingSessionSetup2_D_48 "signal is encrypted, signal TAG not possible";
CM_ SG_ 401 ControlRangingSessionSetup2_D_49 "signal is encrypted, signal TAG not possible";
CM_ SG_ 401 ControlRangingSessionSetup2_D_50 "signal is encrypted, signal TAG not possible";
CM_ SG_ 401 ControlRangingSessionSetup2_D_51 "signal is encrypted, signal TAG not possible";
CM_ SG_ 401 ControlRangingSessionSetup2_D_52 "signal is encrypted, signal TAG not possible";
CM_ SG_ 401 ControlRangingSessionSetup2_D_53 "signal is encrypted, signal TAG not possible";
CM_ SG_ 401 ControlRangingSessionSetup2_D_54 "signal is encrypted, signal TAG not possible";
CM_ SG_ 401 ControlRangingSessionSetup2_D_55 "signal is encrypted, signal TAG not possible";
CM_ SG_ 401 ControlRangingSessionSetup2_D_56 "signal is encrypted, signal TAG not possible";
CM_ SG_ 401 ControlRangingSessionSetup2_D_57 "signal is encrypted, signal TAG not possible";
CM_ SG_ 401 ControlRangingSessionSetup2_D_58 "signal is encrypted, signal TAG not possible";
CM_ SG_ 401 ControlRangingSessionSetup2_D_59 "signal is encrypted, signal TAG not possible";
CM_ SG_ 401 ControlRangingSessionSetup2_D_60 "signal is encrypted, signal TAG not possible";
CM_ SG_ 401 ControlRangingSessionSetup2_D_61 "signal is encrypted, signal TAG not possible";
CM_ SG_ 404 ControlRangingSessionSetup3_Addr "addressing of the UWB anchors";
CM_ SG_ 404 ControlRangingSessionSetup3_Sess "definition of Session-ID";
CM_ SG_ 404 ControlRangingSessionSetup3_Data "signal is encrypted, signal TAG not possible";
CM_ SG_ 404 ControlRangingSessionSetup3_Da_2 "signal is encrypted, signal TAG not possible";
CM_ SG_ 404 ControlRangingSessionSetup3_Da_3 "signal is encrypted, signal TAG not possible";
CM_ SG_ 404 ControlRangingSessionSetup3_Da_4 "signal is encrypted, signal TAG not possible";
CM_ SG_ 404 ControlRangingSessionSetup3_Da_5 "signal is encrypted, signal TAG not possible";
CM_ SG_ 404 ControlRangingSessionSetup3_Da_6 "signal is encrypted, signal TAG not possible";
CM_ SG_ 404 ControlRangingSessionSetup3_Da_7 "signal is encrypted, signal TAG not possible";
CM_ SG_ 404 ControlRangingSessionSetup3_Da_8 "signal is encrypted, signal TAG not possible";
CM_ SG_ 404 ControlRangingSessionSetup3_Da_9 "signal is encrypted, signal TAG not possible";
CM_ SG_ 404 ControlRangingSessionSetup3_D_10 "signal is encrypted, signal TAG not possible";
CM_ SG_ 404 ControlRangingSessionSetup3_D_11 "signal is encrypted, signal TAG not possible";
CM_ SG_ 404 ControlRangingSessionSetup3_D_12 "signal is encrypted, signal TAG not possible";
CM_ SG_ 404 ControlRangingSessionSetup3_D_13 "signal is encrypted, signal TAG not possible";
CM_ SG_ 404 ControlRangingSessionSetup3_D_14 "signal is encrypted, signal TAG not possible";
CM_ SG_ 404 ControlRangingSessionSetup3_D_15 "signal is encrypted, signal TAG not possible";
CM_ SG_ 404 ControlRangingSessionSetup3_D_16 "signal is encrypted, signal TAG not possible";
CM_ SG_ 404 ControlRangingSessionSetup3_D_17 "signal is encrypted, signal TAG not possible";
CM_ SG_ 404 ControlRangingSessionSetup3_D_18 "signal is encrypted, signal TAG not possible";
CM_ SG_ 404 ControlRangingSessionSetup3_D_19 "signal is encrypted, signal TAG not possible";
CM_ SG_ 404 ControlRangingSessionSetup3_D_20 "signal is encrypted, signal TAG not possible";
CM_ SG_ 404 ControlRangingSessionSetup3_D_21 "signal is encrypted, signal TAG not possible";
CM_ SG_ 404 ControlRangingSessionSetup3_D_22 "signal is encrypted, signal TAG not possible";
CM_ SG_ 404 ControlRangingSessionSetup3_D_23 "signal is encrypted, signal TAG not possible";
CM_ SG_ 404 ControlRangingSessionSetup3_D_24 "signal is encrypted, signal TAG not possible";
CM_ SG_ 404 ControlRangingSessionSetup3_D_25 "signal is encrypted, signal TAG not possible";
CM_ SG_ 404 ControlRangingSessionSetup3_D_26 "signal is encrypted, signal TAG not possible";
CM_ SG_ 404 ControlRangingSessionSetup3_D_27 "signal is encrypted, signal TAG not possible";
CM_ SG_ 404 ControlRangingSessionSetup3_D_28 "signal is encrypted, signal TAG not possible";
CM_ SG_ 404 ControlRangingSessionSetup3_D_29 "signal is encrypted, signal TAG not possible";
CM_ SG_ 404 ControlRangingSessionSetup3_D_30 "signal is encrypted, signal TAG not possible";
CM_ SG_ 404 ControlRangingSessionSetup3_D_31 "signal is encrypted, signal TAG not possible";
CM_ SG_ 404 ControlRangingSessionSetup3_D_32 "signal is encrypted, signal TAG not possible";
CM_ SG_ 404 ControlRangingSessionSetup3_D_33 "signal is encrypted, signal TAG not possible";
CM_ SG_ 404 ControlRangingSessionSetup3_D_34 "signal is encrypted, signal TAG not possible";
CM_ SG_ 404 ControlRangingSessionSetup3_D_35 "signal is encrypted, signal TAG not possible";
CM_ SG_ 404 ControlRangingSessionSetup3_D_36 "signal is encrypted, signal TAG not possible";
CM_ SG_ 404 ControlRangingSessionSetup3_D_37 "signal is encrypted, signal TAG not possible";
CM_ SG_ 404 ControlRangingSessionSetup3_D_38 "signal is encrypted, signal TAG not possible";
CM_ SG_ 404 ControlRangingSessionSetup3_D_39 "signal is encrypted, signal TAG not possible";
CM_ SG_ 404 ControlRangingSessionSetup3_D_40 "signal is encrypted, signal TAG not possible";
CM_ SG_ 404 ControlRangingSessionSetup3_D_41 "signal is encrypted, signal TAG not possible";
CM_ SG_ 404 ControlRangingSessionSetup3_D_42 "signal is encrypted, signal TAG not possible";
CM_ SG_ 404 ControlRangingSessionSetup3_D_43 "signal is encrypted, signal TAG not possible";
CM_ SG_ 404 ControlRangingSessionSetup3_D_44 "signal is encrypted, signal TAG not possible";
CM_ SG_ 404 ControlRangingSessionSetup3_D_45 "signal is encrypted, signal TAG not possible";
CM_ SG_ 404 ControlRangingSessionSetup3_D_46 "signal is encrypted, signal TAG not possible";
CM_ SG_ 404 ControlRangingSessionSetup3_D_47 "signal is encrypted, signal TAG not possible";
CM_ SG_ 404 ControlRangingSessionSetup3_D_48 "signal is encrypted, signal TAG not possible";
CM_ SG_ 404 ControlRangingSessionSetup3_D_49 "signal is encrypted, signal TAG not possible";
CM_ SG_ 404 ControlRangingSessionSetup3_D_50 "signal is encrypted, signal TAG not possible";
CM_ SG_ 404 ControlRangingSessionSetup3_D_51 "signal is encrypted, signal TAG not possible";
CM_ SG_ 404 ControlRangingSessionSetup3_D_52 "signal is encrypted, signal TAG not possible";
CM_ SG_ 404 ControlRangingSessionSetup3_D_53 "signal is encrypted, signal TAG not possible";
CM_ SG_ 404 ControlRangingSessionSetup3_D_54 "signal is encrypted, signal TAG not possible";
CM_ SG_ 404 ControlRangingSessionSetup3_D_55 "signal is encrypted, signal TAG not possible";
CM_ SG_ 404 ControlRangingSessionSetup3_D_56 "signal is encrypted, signal TAG not possible";
CM_ SG_ 404 ControlRangingSessionSetup3_D_57 "signal is encrypted, signal TAG not possible";
CM_ SG_ 404 ControlRangingSessionSetup3_D_58 "signal is encrypted, signal TAG not possible";
CM_ SG_ 404 ControlRangingSessionSetup3_D_59 "signal is encrypted, signal TAG not possible";
CM_ SG_ 404 ControlRangingSessionSetup3_D_60 "signal is encrypted, signal TAG not possible";
CM_ SG_ 404 ControlRangingSessionSetup3_D_61 "signal is encrypted, signal TAG not possible";
CM_ SG_ 997 DoorButler_IPB_Byte00 "debug information byte 0";
CM_ SG_ 997 DoorButler_IPB_Byte01 "debug information byte 1";
CM_ SG_ 997 DoorButler_IPB_Byte02 "debug information byte 2";
CM_ SG_ 997 DoorButler_IPB_Byte03 "debug information byte 3";
CM_ SG_ 997 DoorButler_IPB_Byte04 "debug information byte 4";
CM_ SG_ 997 DoorButler_IPB_Byte05 "debug information byte 5";
CM_ SG_ 997 DoorButler_IPB_Byte06 "debug information byte 6";
CM_ SG_ 997 DoorButler_IPB_Byte07 "debug information byte 7";
CM_ SG_ 976 InfoFBD_HL_Data00 "contains information Byte 0";
CM_ SG_ 976 InfoFBD_HL_Data01 "contains information Byte 1";
CM_ SG_ 976 InfoFBD_HL_Data02 "contains information Byte 2";
CM_ SG_ 976 InfoFBD_HL_Data03 "contains information Byte 3";
CM_ SG_ 976 InfoFBD_HL_Data04 "contains information Byte 4";
CM_ SG_ 976 InfoFBD_HL_Data05 "contains information Byte 5";
CM_ SG_ 976 InfoFBD_HL_Data06 "contains information Byte 6";
CM_ SG_ 976 InfoFBD_HL_Data07 "contains information Byte 7";
CM_ SG_ 971 InfoFBD_HM_Data00 "contains information Byte 0";
CM_ SG_ 971 InfoFBD_HM_Data01 "contains information Byte 1";
CM_ SG_ 971 InfoFBD_HM_Data02 "contains information Byte 2";
CM_ SG_ 971 InfoFBD_HM_Data03 "contains information Byte 3";
CM_ SG_ 971 InfoFBD_HM_Data04 "contains information Byte 4";
CM_ SG_ 971 InfoFBD_HM_Data05 "contains information Byte 5";
CM_ SG_ 971 InfoFBD_HM_Data06 "contains information Byte 6";
CM_ SG_ 971 InfoFBD_HM_Data07 "contains information Byte 7";
CM_ SG_ 977 InfoFBD_HR_Data00 "contains information Byte 0";
CM_ SG_ 977 InfoFBD_HR_Data01 "contains information Byte 1";
CM_ SG_ 977 InfoFBD_HR_Data02 "contains information Byte 2";
CM_ SG_ 977 InfoFBD_HR_Data03 "contains information Byte 3";
CM_ SG_ 977 InfoFBD_HR_Data04 "contains information Byte 4";
CM_ SG_ 977 InfoFBD_HR_Data05 "contains information Byte 5";
CM_ SG_ 977 InfoFBD_HR_Data06 "contains information Byte 6";
CM_ SG_ 977 InfoFBD_HR_Data07 "contains information Byte 7";
CM_ SG_ 972 InfoFBD_Miko_Data00 "contains information Byte 0";
CM_ SG_ 972 InfoFBD_Miko_Data01 "contains information Byte 1";
CM_ SG_ 972 InfoFBD_Miko_Data02 "contains information Byte 2";
CM_ SG_ 972 InfoFBD_Miko_Data03 "contains information Byte 3";
CM_ SG_ 972 InfoFBD_Miko_Data04 "contains information Byte 4";
CM_ SG_ 972 InfoFBD_Miko_Data05 "contains information Byte 5";
CM_ SG_ 972 InfoFBD_Miko_Data06 "contains information Byte 6";
CM_ SG_ 972 InfoFBD_Miko_Data07 "contains information Byte 7";
CM_ SG_ 980 InfoFBD_MM_Data00 "contains information Byte 0";
CM_ SG_ 980 InfoFBD_MM_Data01 "contains information Byte 1";
CM_ SG_ 980 InfoFBD_MM_Data02 "contains information Byte 2";
CM_ SG_ 980 InfoFBD_MM_Data03 "contains information Byte 3";
CM_ SG_ 980 InfoFBD_MM_Data04 "contains information Byte 4";
CM_ SG_ 980 InfoFBD_MM_Data05 "contains information Byte 5";
CM_ SG_ 980 InfoFBD_MM_Data06 "contains information Byte 6";
CM_ SG_ 980 InfoFBD_MM_Data07 "contains information Byte 7";
CM_ SG_ 973 InfoFBD_Trunk_Data00 "contains information Byte 0";
CM_ SG_ 973 InfoFBD_Trunk_Data01 "contains information Byte 1";
CM_ SG_ 973 InfoFBD_Trunk_Data02 "contains information Byte 2";
CM_ SG_ 973 InfoFBD_Trunk_Data03 "contains information Byte 3";
CM_ SG_ 973 InfoFBD_Trunk_Data04 "contains information Byte 4";
CM_ SG_ 973 InfoFBD_Trunk_Data05 "contains information Byte 5";
CM_ SG_ 973 InfoFBD_Trunk_Data06 "contains information Byte 6";
CM_ SG_ 973 InfoFBD_Trunk_Data07 "contains information Byte 7";
CM_ SG_ 974 InfoFBD_VL_Data00 "contains information Byte 0";
CM_ SG_ 974 InfoFBD_VL_Data01 "contains information Byte 1";
CM_ SG_ 974 InfoFBD_VL_Data02 "contains information Byte 2";
CM_ SG_ 974 InfoFBD_VL_Data03 "contains information Byte 3";
CM_ SG_ 974 InfoFBD_VL_Data04 "contains information Byte 4";
CM_ SG_ 974 InfoFBD_VL_Data05 "contains information Byte 5";
CM_ SG_ 974 InfoFBD_VL_Data06 "contains information Byte 6";
CM_ SG_ 974 InfoFBD_VL_Data07 "contains information Byte 7";
CM_ SG_ 970 InfoFBD_VM_Data00 "contains information Byte 0";
CM_ SG_ 970 InfoFBD_VM_Data01 "contains information Byte 1";
CM_ SG_ 970 InfoFBD_VM_Data02 "contains information Byte 2";
CM_ SG_ 970 InfoFBD_VM_Data03 "contains information Byte 3";
CM_ SG_ 970 InfoFBD_VM_Data04 "contains information Byte 4";
CM_ SG_ 970 InfoFBD_VM_Data05 "contains information Byte 5";
CM_ SG_ 970 InfoFBD_VM_Data06 "contains information Byte 6";
CM_ SG_ 970 InfoFBD_VM_Data07 "contains information Byte 7";
CM_ SG_ 975 InfoFBD_VR_Data00 "contains information Byte 0";
CM_ SG_ 975 InfoFBD_VR_Data01 "contains information Byte 1";
CM_ SG_ 975 InfoFBD_VR_Data02 "contains information Byte 2";
CM_ SG_ 975 InfoFBD_VR_Data03 "contains information Byte 3";
CM_ SG_ 975 InfoFBD_VR_Data04 "contains information Byte 4";
CM_ SG_ 975 InfoFBD_VR_Data05 "contains information Byte 5";
CM_ SG_ 975 InfoFBD_VR_Data06 "contains information Byte 6";
CM_ SG_ 975 InfoFBD_VR_Data07 "contains information Byte 7";
CM_ SG_ 556 LocalizationInitFBD_HL_IRKListIn "contains Session-ID";
CM_ SG_ 556 LocalizationInitFBD_HL_ZoneEntry "contains Zone transition";
CM_ SG_ 556 LocalizationInitFBD_HL_RangingBl "Frame Index of the latest ranging";
CM_ SG_ 556 LocalizationInitFBD_HL_TimeOfFli "ranging result in ps (PH) = (DEC) * 15.65";
CM_ SG_ 556 LocalizationInitFBD_HL_RSSI_0 "first path AoA";
CM_ SG_ 556 LocalizationInitFBD_HL_Ranging_2 "Frame Index of the second-to-last ranging";
CM_ SG_ 556 LocalizationInitFBD_HL_TimeOfF_2 "ranging result in ps (PH) = (DEC) * 15.65";
CM_ SG_ 556 LocalizationInitFBD_HL_RSSI_1 "first path AoA";
CM_ SG_ 556 LocalizationInitFBD_HL_Ranging_3 "Frame Index of the third-to-last ranging";
CM_ SG_ 556 LocalizationInitFBD_HL_TimeOfF_3 "ranging result in ps (PH) = (DEC) * 15.65";
CM_ SG_ 556 LocalizationInitFBD_HL_RSSI_2 "first path AoA";
CM_ SG_ 556 LocalizationInitFBD_HL_Ranging_4 "Frame Index of the fourth-last ranging";
CM_ SG_ 556 LocalizationInitFBD_HL_TimeOfF_4 "ranging result in ps (PH) = (DEC) * 15.65";
CM_ SG_ 556 LocalizationInitFBD_HL_RSSI_3 "first path AoA";
CM_ SG_ 556 LocalizationInitFBD_HL_Ranging_5 "Frame Index of the fifth-last ranging";
CM_ SG_ 556 LocalizationInitFBD_HL_TimeOfF_5 "ranging result in ps (PH) = (DEC) * 15.65";
CM_ SG_ 556 LocalizationInitFBD_HL_RSSI_4 "first path AoA";
CM_ SG_ 556 LocalizationInitFBD_HL_Sign_00 "contains Auth. Signal is encrypted, signal TAG not possible";
CM_ SG_ 556 LocalizationInitFBD_HL_Sign_01 "contains Auth. Signal is encrypted, signal TAG not possible";
CM_ SG_ 556 LocalizationInitFBD_HL_Sign_02 "contains Auth. Signal is encrypted, signal TAG not possible";
CM_ SG_ 556 LocalizationInitFBD_HL_Sign_03 "contains Auth. Signal is encrypted, signal TAG not possible";
CM_ SG_ 556 LocalizationInitFBD_HL_Sign_04 "contains Auth. Signal is encrypted, signal TAG not possible";
CM_ SG_ 556 LocalizationInitFBD_HL_Sign_05 "contains Auth. Signal is encrypted, signal TAG not possible";
CM_ SG_ 556 LocalizationInitFBD_HL_Sign_06 "contains Auth. Signal is encrypted, signal TAG not possible";
CM_ SG_ 556 LocalizationInitFBD_HL_Sign_07 "contains Auth. Signal is encrypted, signal TAG not possible";
CM_ SG_ 556 LocalizationInitFBD_HL_Sign_08 "contains Auth. Signal is encrypted, signal TAG not possible";
CM_ SG_ 556 LocalizationInitFBD_HL_Sign_09 "contains Auth. Signal is encrypted, signal TAG not possible";
CM_ SG_ 556 LocalizationInitFBD_HL_Sign_10 "contains Auth. Signal is encrypted, signal TAG not possible";
CM_ SG_ 556 LocalizationInitFBD_HL_Sign_11 "contains Auth. Signal is encrypted, signal TAG not possible";
CM_ SG_ 556 LocalizationInitFBD_HL_Sign_12 "contains Auth. Signal is encrypted, signal TAG not possible";
CM_ SG_ 556 LocalizationInitFBD_HL_Sign_13 "contains Auth. Signal is encrypted, signal TAG not possible";
CM_ SG_ 556 LocalizationInitFBD_HL_Sign_14 "contains Auth. Signal is encrypted, signal TAG not possible";
CM_ SG_ 556 LocalizationInitFBD_HL_Sign_15 "contains Auth. Signal is encrypted, signal TAG not possible";
CM_ SG_ 556 LocalizationInitFBD_HL_RangingRo "contains Hopping Offset";
CM_ SG_ 556 LocalizationInitFBD_HL_Ranging_6 "contains Hopping Offset";
CM_ SG_ 556 LocalizationInitFBD_HL_Ranging_7 "contains Hopping Offset";
CM_ SG_ 556 LocalizationInitFBD_HL_Ranging_8 "contains Hopping Offset";
CM_ SG_ 556 LocalizationInitFBD_HL_Ranging_9 "contains Hopping Offset";
CM_ SG_ 551 LocalizationInitFBD_HM_IRKListIn "contains Session-ID";
CM_ SG_ 551 LocalizationInitFBD_HM_ZoneEntry "contains Zone transition";
CM_ SG_ 551 LocalizationInitFBD_HM_RangingBl "Frame Index of the latest ranging";
CM_ SG_ 551 LocalizationInitFBD_HM_TimeOfFli "ranging result in ps (PH) = (DEC) * 15.65";
CM_ SG_ 551 LocalizationInitFBD_HM_RSSI_0 "first path AoA";
CM_ SG_ 551 LocalizationInitFBD_HM_Ranging_2 "Frame Index of the second-to-last ranging";
CM_ SG_ 551 LocalizationInitFBD_HM_TimeOfF_2 "ranging result in ps (PH) = (DEC) * 15.65";
CM_ SG_ 551 LocalizationInitFBD_HM_RSSI_1 "first path AoA";
CM_ SG_ 551 LocalizationInitFBD_HM_Ranging_3 "Frame Index of the third-to-last ranging";
CM_ SG_ 551 LocalizationInitFBD_HM_TimeOfF_3 "ranging result in ps (PH) = (DEC) * 15.65";
CM_ SG_ 551 LocalizationInitFBD_HM_RSSI_2 "first path AoA";
CM_ SG_ 551 LocalizationInitFBD_HM_Ranging_4 "Frame Index of the fourth-last ranging";
CM_ SG_ 551 LocalizationInitFBD_HM_TimeOfF_4 "ranging result in ps (PH) = (DEC) * 15.65";
CM_ SG_ 551 LocalizationInitFBD_HM_RSSI_3 "first path AoA";
CM_ SG_ 551 LocalizationInitFBD_HM_Ranging_5 "Frame Index of the fifth-last ranging";
CM_ SG_ 551 LocalizationInitFBD_HM_TimeOfF_5 "ranging result in ps (PH) = (DEC) * 15.65";
CM_ SG_ 551 LocalizationInitFBD_HM_RSSI_4 "first path AoA";
CM_ SG_ 551 LocalizationInitFBD_HM_Sign_00 "contains Auth. Signal is encrypted, signal TAG not possible";
CM_ SG_ 551 LocalizationInitFBD_HM_Sign_01 "contains Auth. Signal is encrypted, signal TAG not possible";
CM_ SG_ 551 LocalizationInitFBD_HM_Sign_02 "contains Auth. Signal is encrypted, signal TAG not possible";
CM_ SG_ 551 LocalizationInitFBD_HM_Sign_03 "contains Auth. Signal is encrypted, signal TAG not possible";
CM_ SG_ 551 LocalizationInitFBD_HM_Sign_04 "contains Auth. Signal is encrypted, signal TAG not possible";
CM_ SG_ 551 LocalizationInitFBD_HM_Sign_05 "contains Auth. Signal is encrypted, signal TAG not possible";
CM_ SG_ 551 LocalizationInitFBD_HM_Sign_06 "contains Auth. Signal is encrypted, signal TAG not possible";
CM_ SG_ 551 LocalizationInitFBD_HM_Sign_07 "contains Auth. Signal is encrypted, signal TAG not possible";
CM_ SG_ 551 LocalizationInitFBD_HM_Sign_08 "contains Auth. Signal is encrypted, signal TAG not possible";
CM_ SG_ 551 LocalizationInitFBD_HM_Sign_09 "contains Auth. Signal is encrypted, signal TAG not possible";
CM_ SG_ 551 LocalizationInitFBD_HM_Sign_10 "contains Auth. Signal is encrypted, signal TAG not possible";
CM_ SG_ 551 LocalizationInitFBD_HM_Sign_11 "contains Auth. Signal is encrypted, signal TAG not possible";
CM_ SG_ 551 LocalizationInitFBD_HM_Sign_12 "contains Auth. Signal is encrypted, signal TAG not possible";
CM_ SG_ 551 LocalizationInitFBD_HM_Sign_13 "contains Auth. Signal is encrypted, signal TAG not possible";
CM_ SG_ 551 LocalizationInitFBD_HM_Sign_14 "contains Auth. Signal is encrypted, signal TAG not possible";
CM_ SG_ 551 LocalizationInitFBD_HM_Sign_15 "contains Auth. Signal is encrypted, signal TAG not possible";
CM_ SG_ 551 LocalizationInitFBD_HM_RangingRo "contains Hopping Offset";
CM_ SG_ 551 LocalizationInitFBD_HM_Ranging_6 "contains Hopping Offset";
CM_ SG_ 551 LocalizationInitFBD_HM_Ranging_7 "contains Hopping Offset";
CM_ SG_ 551 LocalizationInitFBD_HM_Ranging_8 "contains Hopping Offset";
CM_ SG_ 551 LocalizationInitFBD_HM_Ranging_9 "contains Hopping Offset";
CM_ SG_ 557 LocalizationInitFBD_HR_IRKListIn "contains Session-ID";
CM_ SG_ 557 LocalizationInitFBD_HR_ZoneEntry "contains Zone transition";
CM_ SG_ 557 LocalizationInitFBD_HR_RangingBl "Frame Index of the latest ranging";
CM_ SG_ 557 LocalizationInitFBD_HR_TimeOfFli "ranging result in ps (PH) = (DEC) * 15.65";
CM_ SG_ 557 LocalizationInitFBD_HR_RSSI_0 "first path AoA";
CM_ SG_ 557 LocalizationInitFBD_HR_Ranging_2 "Frame Index of the second-to-last ranging";
CM_ SG_ 557 LocalizationInitFBD_HR_TimeOfF_2 "ranging result in ps (PH) = (DEC) * 15.65";
CM_ SG_ 557 LocalizationInitFBD_HR_RSSI_1 "first path AoA";
CM_ SG_ 557 LocalizationInitFBD_HR_Ranging_3 "Frame Index of the third-to-last ranging";
CM_ SG_ 557 LocalizationInitFBD_HR_TimeOfF_3 "ranging result in ps (PH) = (DEC) * 15.65";
CM_ SG_ 557 LocalizationInitFBD_HR_RSSI_2 "first path AoA";
CM_ SG_ 557 LocalizationInitFBD_HR_Ranging_4 "Frame Index of the fourth-last ranging";
CM_ SG_ 557 LocalizationInitFBD_HR_TimeOfF_4 "ranging result in ps (PH) = (DEC) * 15.65";
CM_ SG_ 557 LocalizationInitFBD_HR_RSSI_3 "first path AoA";
CM_ SG_ 557 LocalizationInitFBD_HR_Ranging_5 "Frame Index of the fifth-last ranging";
CM_ SG_ 557 LocalizationInitFBD_HR_TimeOfF_5 "ranging result in ps (PH) = (DEC) * 15.65";
CM_ SG_ 557 LocalizationInitFBD_HR_RSSI_4 "first path AoA";
CM_ SG_ 557 LocalizationInitFBD_HR_Sign_00 "contains Auth. Signal is encrypted, signal TAG not possible";
CM_ SG_ 557 LocalizationInitFBD_HR_Sign_01 "contains Auth. Signal is encrypted, signal TAG not possible";
CM_ SG_ 557 LocalizationInitFBD_HR_Sign_02 "contains Auth. Signal is encrypted, signal TAG not possible";
CM_ SG_ 557 LocalizationInitFBD_HR_Sign_03 "contains Auth. Signal is encrypted, signal TAG not possible";
CM_ SG_ 557 LocalizationInitFBD_HR_Sign_04 "contains Auth. Signal is encrypted, signal TAG not possible";
CM_ SG_ 557 LocalizationInitFBD_HR_Sign_05 "contains Auth. Signal is encrypted, signal TAG not possible";
CM_ SG_ 557 LocalizationInitFBD_HR_Sign_06 "contains Auth. Signal is encrypted, signal TAG not possible";
CM_ SG_ 557 LocalizationInitFBD_HR_Sign_07 "contains Auth. Signal is encrypted, signal TAG not possible";
CM_ SG_ 557 LocalizationInitFBD_HR_Sign_08 "contains Auth. Signal is encrypted, signal TAG not possible";
CM_ SG_ 557 LocalizationInitFBD_HR_Sign_09 "contains Auth. Signal is encrypted, signal TAG not possible";
CM_ SG_ 557 LocalizationInitFBD_HR_Sign_10 "contains Auth. Signal is encrypted, signal TAG not possible";
CM_ SG_ 557 LocalizationInitFBD_HR_Sign_11 "contains Auth. Signal is encrypted, signal TAG not possible";
CM_ SG_ 557 LocalizationInitFBD_HR_Sign_12 "contains Auth. Signal is encrypted, signal TAG not possible";
CM_ SG_ 557 LocalizationInitFBD_HR_Sign_13 "contains Auth. Signal is encrypted, signal TAG not possible";
CM_ SG_ 557 LocalizationInitFBD_HR_Sign_14 "contains Auth. Signal is encrypted, signal TAG not possible";
CM_ SG_ 557 LocalizationInitFBD_HR_Sign_15 "contains Auth. Signal is encrypted, signal TAG not possible";
CM_ SG_ 557 LocalizationInitFBD_HR_RangingRo "contains Hopping Offset";
CM_ SG_ 557 LocalizationInitFBD_HR_Ranging_6 "contains Hopping Offset";
CM_ SG_ 557 LocalizationInitFBD_HR_Ranging_7 "contains Hopping Offset";
CM_ SG_ 557 LocalizationInitFBD_HR_Ranging_8 "contains Hopping Offset";
CM_ SG_ 557 LocalizationInitFBD_HR_Ranging_9 "contains Hopping Offset";

BA_DEF_ BO_ "VFrameFormat" ENUM "StandardCAN","ExtendedCAN","reserved","J1939PG","reserved","reserved","reserved","reserved","reserved","reserved","reserved","reserved","reserved","reserved","StandardCAN_FD","ExtendedCAN_FD";
BA_DEF_DEF_ "VFrameFormat" "StandardCAN";
BA_ "VFrameFormat" BO_ 686 14;
BA_ "VFrameFormat" BO_ 681 14;
BA_ "VFrameFormat" BO_ 687 14;
BA_ "VFrameFormat" BO_ 682 14;
BA_ "VFrameFormat" BO_ 690 14;
BA_ "VFrameFormat" BO_ 683 14;
BA_ "VFrameFormat" BO_ 684 14;
BA_ "VFrameFormat" BO_ 680 14;
BA_ "VFrameFormat" BO_ 685 14;
BA_ "VFrameFormat" BO_ 605 14;
BA_ "VFrameFormat" BO_ 383 14;
BA_ "VFrameFormat" BO_ 608 14;
BA_ "VFrameFormat" BO_ 200 14;
BA_ "VFrameFormat" BO_ 209 14;
BA_ "VFrameFormat" BO_ 600 14;
BA_ "VFrameFormat" BO_ 603 14;
BA_ "VFrameFormat" BO_ 302 14;
BA_ "VFrameFormat" BO_ 402 14;
BA_ "VFrameFormat" BO_ 400 14;
BA_ "VFrameFormat" BO_ 401 14;
BA_ "VFrameFormat" BO_ 404 14;
BA_ "VFrameFormat" BO_ 1100 14;
BA_ "VFrameFormat" BO_ 1101 14;
BA_ "VFrameFormat" BO_ 556 14;
BA_ "VFrameFormat" BO_ 551 14;
BA_ "VFrameFormat" BO_ 557 14;
